VERSION "dbc-export 1 2025.20.8"

NS_ :

BS_:

BU_: ADSP APB APP APS APSB BB BMS CC CMP CMPD CP DAS DI DIF DIR DPB EPAS3P EPAS3S EPASTP EPASTS EPBL EPBR ESP EVSE FC GTW HCML HCMR HVP IBST ICR IDB LS OCS1P ODIN PARK PCS PLG PM PMF PMR PNCD PTC RADC RCM RCM2 RCM3 RCU SCCM SCM SCS SDCR TAS TCU TPMS TRCM UDS UI UIS UMC USM VC VCFRONT VCLEFT VCRIGHT VCSEC VEH

BO_ 1298 TRCM_alertLog: 8 TRCM
 SG_ TRCM_alertID M : 0|10@1+ (1,0) [0|1023] "" Vector__XXX
 SG_ TRCM_alertState : 15|1@1+ (1,0) [0|1] "" Vector__XXX
 SG_ TRCM_a015_NVMMMemOverflow m15 : 16|1@1+ (1,0) [0|1] "" Vector__XXX
 SG_ TRCM_a015_NVMMFilesystemError m15 : 17|1@1+ (1,0) [0|1] "" Vector__XXX
 SG_ TRCM_a015_NVMMRecordIDError m15 : 18|1@1+ (1,0) [0|1] "" Vector__XXX
 SG_ TRCM_a057_VEH_cpControl m57 : 16|1@1+ (1,0) [0|1] "" Vector__XXX
 SG_ TRCM_a059_voltageDrop m59 : 16|12@1+ (0.005443676,0) [0|22.29185322] "V" Vector__XXX
 SG_ TRCM_a059_resistanceEstimate m59 : 28|12@1+ (0.00244,0) [0|9.9918] "Ohms" Vector__XXX
 SG_ TRCM_a059_current m59 : 40|12@1+ (0.05,0) [0|204.75] "A" Vector__XXX
 SG_ TRCM_a063_switchChannel m63 : 16|8@1+ (1,0) [0|255] "" Vector__XXX
 SG_ TRCM_a063_switchType m63 : 24|8@1+ (1,0) [0|255] "" Vector__XXX
 SG_ TRCM_a063_ADCVoltage m63 : 32|8@1+ (0.025,0) [0|6.375] "V" Vector__XXX
 SG_ TRCM_a063_disconnected m63 : 40|1@1+ (1,0) [0|1] "" Vector__XXX
 SG_ TRCM_a063_indeterminate m63 : 41|1@1+ (1,0) [0|1] "" Vector__XXX
 SG_ TRCM_a063_stuckActive m63 : 42|1@1+ (1,0) [0|1] "" Vector__XXX
 SG_ TRCM_a063_faulted m63 : 43|1@1+ (1,0) [0|1] "" Vector__XXX
 SG_ TRCM_a082_RIPC_epbPrivateState m82 : 16|1@1+ (1,0) [0|1] "" Vector__XXX
 SG_ TRCM_a082_RIPC_remoteHSD m82 : 17|1@1+ (1,0) [0|1] "" Vector__XXX
 SG_ TRCM_a082_RIPC_railStatus m82 : 18|1@1+ (1,0) [0|1] "" Vector__XXX
 SG_ TRCM_a082_RIPC_remoteMux m82 : 19|1@1+ (1,0) [0|1] "" Vector__XXX
 SG_ TRCM_a083_LIPC_epbPrivateState m83 : 16|1@1+ (1,0) [0|1] "" Vector__XXX
 SG_ TRCM_a083_LIPC_remoteHSD m83 : 17|1@1+ (1,0) [0|1] "" Vector__XXX
 SG_ TRCM_a083_LIPC_railStatus m83 : 18|1@1+ (1,0) [0|1] "" Vector__XXX
 SG_ TRCM_a083_LIPC_HSDFaults m83 : 19|1@1+ (1,0) [0|1] "" Vector__XXX
 SG_ TRCM_a084_CH_StatusC m84 : 16|1@1+ (1,0) [0|1] "" Vector__XXX
 SG_ TRCM_a085_PARTY_buttonStatus m85 : 16|1@1+ (1,0) [0|1] "" Vector__XXX
 SG_ TRCM_a086_VEH_LVBMS_statusHigh m86 : 16|1@1+ (1,0) [0|1] "" Vector__XXX
 SG_ TRCM_a086_VEH_LVBMS_statusLow m86 : 17|1@1+ (1,0) [0|1] "" Vector__XXX
 SG_ TRCM_a086_VEH_status m86 : 18|1@1+ (1,0) [0|1] "" Vector__XXX
 SG_ TRCM_a086_VEH_12VBatteryStatus m86 : 19|1@1+ (1,0) [0|1] "" Vector__XXX
 SG_ TRCM_a086_VEH_LVPowerState m86 : 20|1@1+ (1,0) [0|1] "" Vector__XXX
 SG_ TRCM_a086_VEH_lightStatus m86 : 21|1@1+ (1,0) [0|1] "" Vector__XXX
 SG_ TRCM_a086_VEH_systemStatus m86 : 22|1@1+ (1,0) [0|1] "" Vector__XXX
 SG_ TRCM_a086_VEH_thermalStatus m86 : 23|1@1+ (1,0) [0|1] "" Vector__XXX
 SG_ TRCM_a086_VEH_vehNm m86 : 24|1@1+ (1,0) [0|1] "" Vector__XXX
 SG_ TRCM_a087_VEH_temperature m87 : 16|1@1+ (1,0) [0|1] "" Vector__XXX
 SG_ TRCM_a087_VEH_thermalControl m87 : 17|1@1+ (1,0) [0|1] "" Vector__XXX
 SG_ TRCM_a087_VEH_torque m87 : 18|1@1+ (1,0) [0|1] "" Vector__XXX
 SG_ TRCM_a087_VEH_status m87 : 19|1@1+ (1,0) [0|1] "" Vector__XXX
 SG_ TRCM_a087_PARTY_torque m87 : 20|1@1+ (1,0) [0|1] "" Vector__XXX
 SG_ TRCM_a087_PARTY_status m87 : 21|1@1+ (1,0) [0|1] "" Vector__XXX
 SG_ TRCM_a087_PARTY_temperature m87 : 22|1@1+ (1,0) [0|1] "" Vector__XXX
 SG_ TRCM_a087_PARTY_thermalControl m87 : 23|1@1+ (1,0) [0|1] "" Vector__XXX
 SG_ TRCM_a088_VEH_temperature m88 : 16|1@1+ (1,0) [0|1] "" Vector__XXX
 SG_ TRCM_a088_VEH_thermalControl m88 : 17|1@1+ (1,0) [0|1] "" Vector__XXX
 SG_ TRCM_a088_VEH_torque m88 : 18|1@1+ (1,0) [0|1] "" Vector__XXX
 SG_ TRCM_a088_VEH_status m88 : 19|1@1+ (1,0) [0|1] "" Vector__XXX
 SG_ TRCM_a088_PARTY_torque m88 : 20|1@1+ (1,0) [0|1] "" Vector__XXX
 SG_ TRCM_a088_PARTY_status m88 : 21|1@1+ (1,0) [0|1] "" Vector__XXX
 SG_ TRCM_a088_PARTY_temperature m88 : 22|1@1+ (1,0) [0|1] "" Vector__XXX
 SG_ TRCM_a088_PARTY_thermalControl m88 : 23|1@1+ (1,0) [0|1] "" Vector__XXX
 SG_ TRCM_a089_PARTY_party1 m89 : 16|1@1+ (1,0) [0|1] "" Vector__XXX
 SG_ TRCM_a089_PARTY_status m89 : 17|1@1+ (1,0) [0|1] "" Vector__XXX
 SG_ TRCM_a089_VEH_status m89 : 18|1@1+ (1,0) [0|1] "" Vector__XXX
 SG_ TRCM_a089_BDY_party1 m89 : 19|1@1+ (1,0) [0|1] "" Vector__XXX
 SG_ TRCM_a089_BDY_status m89 : 20|1@1+ (1,0) [0|1] "" Vector__XXX
 SG_ TRCM_a089_CH_status m89 : 21|1@1+ (1,0) [0|1] "" Vector__XXX
 SG_ TRCM_a089_CH_party1 m89 : 22|1@1+ (1,0) [0|1] "" Vector__XXX
 SG_ TRCM_a089_CH_party3 m89 : 23|1@1+ (1,0) [0|1] "" Vector__XXX
 SG_ TRCM_a089_VEH_party1 m89 : 24|1@1+ (1,0) [0|1] "" Vector__XXX
 SG_ TRCM_a089_VEH_party3 m89 : 25|1@1+ (1,0) [0|1] "" Vector__XXX
 SG_ TRCM_a091_VEH_faultsAndExtras m91 : 16|1@1+ (1,0) [0|1] "" Vector__XXX
 SG_ TRCM_a091_VEH_info m91 : 17|1@1+ (1,0) [0|1] "" Vector__XXX
 SG_ TRCM_a091_VEH_state m91 : 18|1@1+ (1,0) [0|1] "" Vector__XXX
 SG_ TRCM_a092_VEH_restraintStatus m92 : 16|1@1+ (1,0) [0|1] "" Vector__XXX
 SG_ TRCM_a092_VEH_switchStatus m92 : 17|1@1+ (1,0) [0|1] "" Vector__XXX
 SG_ TRCM_a092_VEH_seatStatus2 m92 : 18|1@1+ (1,0) [0|1] "" Vector__XXX
 SG_ TRCM_a092_VEH_vehNm m92 : 19|1@1+ (1,0) [0|1] "" Vector__XXX
 SG_ TRCM_a093_VEH_restraintStatus m93 : 16|1@1+ (1,0) [0|1] "" Vector__XXX
 SG_ TRCM_a093_VEH_switchStatus m93 : 17|1@1+ (1,0) [0|1] "" Vector__XXX
 SG_ TRCM_a093_VEH_seatStatus2 m93 : 18|1@1+ (1,0) [0|1] "" Vector__XXX
 SG_ TRCM_a093_VEH_vehNm m93 : 19|1@1+ (1,0) [0|1] "" Vector__XXX
 SG_ TRCM_a094_VEH_sysStatus m94 : 16|1@1+ (1,0) [0|1] "" Vector__XXX
 SG_ TRCM_a094_PARTY_sysStatus m94 : 17|1@1+ (1,0) [0|1] "" Vector__XXX
 SG_ TRCM_a095_PT_ptNm m95 : 16|1@1+ (1,0) [0|1] "" Vector__XXX
 SG_ TRCM_a095_PT_status m95 : 17|1@1+ (1,0) [0|1] "" Vector__XXX
 SG_ TRCM_a096_VEH_status m96 : 16|1@1+ (1,0) [0|1] "" Vector__XXX
 SG_ TRCM_a096_CH_status m96 : 17|1@1+ (1,0) [0|1] "" Vector__XXX
 SG_ TRCM_a098_CH_torque m98 : 16|1@1+ (1,0) [0|1] "" Vector__XXX
 SG_ TRCM_a098_VEH_hvStatus m98 : 17|1@1+ (1,0) [0|1] "" Vector__XXX
 SG_ TRCM_a098_VEH_status m98 : 18|1@1+ (1,0) [0|1] "" Vector__XXX
 SG_ TRCM_a098_VEH_thermalControl m98 : 19|1@1+ (1,0) [0|1] "" Vector__XXX
 SG_ TRCM_a098_VEH_temperature m98 : 20|1@1+ (1,0) [0|1] "" Vector__XXX
 SG_ TRCM_a098_VEH_torque m98 : 21|1@1+ (1,0) [0|1] "" Vector__XXX
 SG_ TRCM_a098_PARTY_status m98 : 22|1@1+ (1,0) [0|1] "" Vector__XXX
 SG_ TRCM_a098_PARTY_temperature m98 : 23|1@1+ (1,0) [0|1] "" Vector__XXX
 SG_ TRCM_a098_PARTY_thermalControl m98 : 24|1@1+ (1,0) [0|1] "" Vector__XXX
 SG_ TRCM_a098_PARTY_torque m98 : 25|1@1+ (1,0) [0|1] "" Vector__XXX
 SG_ TRCM_a098_PT_thermalControl m98 : 26|1@1+ (1,0) [0|1] "" Vector__XXX
 SG_ TRCM_a098_PT_temperature m98 : 27|1@1+ (1,0) [0|1] "" Vector__XXX
 SG_ TRCM_a099_VEH_oocStatus m99 : 16|1@1+ (1,0) [0|1] "" Vector__XXX
 SG_ TRCM_a100_VEH m100 : 16|1@1+ (1,0) [0|1] "" Vector__XXX
 SG_ TRCM_a100_PARTY m100 : 17|1@1+ (1,0) [0|1] "" Vector__XXX
 SG_ TRCM_a100_PT m100 : 18|1@1+ (1,0) [0|1] "" Vector__XXX
 SG_ TRCM_a100_CH m100 : 19|1@1+ (1,0) [0|1] "" Vector__XXX
 SG_ TRCM_a100_OBD m100 : 20|1@1+ (1,0) [0|1] "" Vector__XXX
 SG_ TRCM_a101_VEH_state m101 : 16|1@1+ (1,0) [0|1] "" Vector__XXX
 SG_ TRCM_a101_PARTY_locState m101 : 17|1@1+ (1,0) [0|1] "" Vector__XXX
 SG_ TRCM_a101_LIPC_externalWatchdogH m101 : 18|1@1+ (1,0) [0|1] "" Vector__XXX
 SG_ TRCM_a101_VEH_locState m101 : 19|1@1+ (1,0) [0|1] "" Vector__XXX
 SG_ TRCM_a101_BDY_locState m101 : 20|1@1+ (1,0) [0|1] "" Vector__XXX
 SG_ TRCM_a102_VEH_faultsAndExtras m102 : 16|1@1+ (1,0) [0|1] "" Vector__XXX
 SG_ TRCM_a102_VEH_feedbackStatus m102 : 17|1@1+ (1,0) [0|1] "" Vector__XXX
 SG_ TRCM_a102_VEH_sensorStatus m102 : 18|1@1+ (1,0) [0|1] "" Vector__XXX
 SG_ TRCM_a102_VEH_rods m102 : 19|1@1+ (1,0) [0|1] "" Vector__XXX
 SG_ TRCM_a103_VEH_hvsNm m103 : 16|1@1+ (1,0) [0|1] "" Vector__XXX
 SG_ TRCM_a103_VEH_vehNm m103 : 17|1@1+ (1,0) [0|1] "" Vector__XXX
 SG_ TRCM_a103_VEH_status m103 : 18|1@1+ (1,0) [0|1] "" Vector__XXX
 SG_ TRCM_a103_PT_ptNm m103 : 19|1@1+ (1,0) [0|1] "" Vector__XXX
 SG_ TRCM_a103_PT_status m103 : 20|1@1+ (1,0) [0|1] "" Vector__XXX
 SG_ TRCM_a103_VEH_evseStatus m103 : 21|1@1+ (1,0) [0|1] "" Vector__XXX
 SG_ TRCM_a105_VEH_states m105 : 16|1@1+ (1,0) [0|1] "" Vector__XXX
 SG_ TRCM_a105_VEH_chNm m105 : 17|1@1+ (1,0) [0|1] "" Vector__XXX
 SG_ TRCM_a105_VEH_dampingStates m105 : 18|1@1+ (1,0) [0|1] "" Vector__XXX
 SG_ TRCM_a106_VEH_dcdcStatus m106 : 16|1@1+ (1,0) [0|1] "" Vector__XXX
 SG_ TRCM_a106_VEH_thermalControl m106 : 17|1@1+ (1,0) [0|1] "" Vector__XXX
 SG_ TRCM_a106_VEH_thermalInterface m106 : 18|1@1+ (1,0) [0|1] "" Vector__XXX
 SG_ TRCM_a106_VEH_dcdcRailStatus m106 : 19|1@1+ (1,0) [0|1] "" Vector__XXX
 SG_ TRCM_a106_CH_dcdcRailStatus m106 : 20|1@1+ (1,0) [0|1] "" Vector__XXX
 SG_ TRCM_a106_CH_alertMatrix m106 : 21|1@1+ (1,0) [0|1] "" Vector__XXX
 SG_ TRCM_a107_VEH_hvsNm m107 : 16|1@1+ (1,0) [0|1] "" Vector__XXX
 SG_ TRCM_a107_VEH_vehNm m107 : 17|1@1+ (1,0) [0|1] "" Vector__XXX
 SG_ TRCM_a107_VEH_status m107 : 18|1@1+ (1,0) [0|1] "" Vector__XXX
 SG_ TRCM_a107_VEH_thermalStatus m107 : 19|1@1+ (1,0) [0|1] "" Vector__XXX
 SG_ TRCM_a107_VEH_thermalStatus2 m107 : 20|1@1+ (1,0) [0|1] "" Vector__XXX
 SG_ TRCM_a107_VEH_bmbMinMax m107 : 21|1@1+ (1,0) [0|1] "" Vector__XXX
 SG_ TRCM_a107_VEH_powerAvailable m107 : 22|1@1+ (1,0) [0|1] "" Vector__XXX
 SG_ TRCM_a107_PT_ptNm m107 : 23|1@1+ (1,0) [0|1] "" Vector__XXX
 SG_ TRCM_a107_PT_status m107 : 24|1@1+ (1,0) [0|1] "" Vector__XXX
 SG_ TRCM_a107_PT_thermalStatus m107 : 25|1@1+ (1,0) [0|1] "" Vector__XXX
 SG_ TRCM_a107_PT_socStatus m107 : 26|1@1+ (1,0) [0|1] "" Vector__XXX
 SG_ TRCM_a107_VEH_socStatus m107 : 27|1@1+ (1,0) [0|1] "" Vector__XXX
 SG_ TRCM_a107_VEH_packConfig m107 : 28|1@1+ (1,0) [0|1] "" Vector__XXX
 SG_ TRCM_a107_VEH_energyStatus m107 : 29|1@1+ (1,0) [0|1] "" Vector__XXX
 SG_ TRCM_a107_VEH_chargeInfo m107 : 30|1@1+ (1,0) [0|1] "" Vector__XXX
 SG_ TRCM_a108_VEH_hvStatus m108 : 16|1@1+ (1,0) [0|1] "" Vector__XXX
 SG_ TRCM_a108_VEH_temperature m108 : 17|1@1+ (1,0) [0|1] "" Vector__XXX
 SG_ TRCM_a108_VEH_thermalControl m108 : 18|1@1+ (1,0) [0|1] "" Vector__XXX
 SG_ TRCM_a108_VEH_torque m108 : 19|1@1+ (1,0) [0|1] "" Vector__XXX
 SG_ TRCM_a108_VEH_status m108 : 20|1@1+ (1,0) [0|1] "" Vector__XXX
 SG_ TRCM_a108_PARTY_torque m108 : 21|1@1+ (1,0) [0|1] "" Vector__XXX
 SG_ TRCM_a108_PARTY_status m108 : 22|1@1+ (1,0) [0|1] "" Vector__XXX
 SG_ TRCM_a108_PARTY_temperature m108 : 23|1@1+ (1,0) [0|1] "" Vector__XXX
 SG_ TRCM_a108_PARTY_thermalControl m108 : 24|1@1+ (1,0) [0|1] "" Vector__XXX
 SG_ TRCM_a108_PT_temperature m108 : 25|1@1+ (1,0) [0|1] "" Vector__XXX
 SG_ TRCM_a108_PT_thermalControl m108 : 26|1@1+ (1,0) [0|1] "" Vector__XXX
 SG_ TRCM_a109_PARTY_status m109 : 16|1@1+ (1,0) [0|1] "" Vector__XXX
 SG_ TRCM_a109_PARTY_inertial2 m109 : 17|1@1+ (1,0) [0|1] "" Vector__XXX
 SG_ TRCM_a109_PARTY_nearDeploy m109 : 18|1@1+ (1,0) [0|1] "" Vector__XXX
 SG_ TRCM_a109_PARTY_collision m109 : 19|1@1+ (1,0) [0|1] "" Vector__XXX
 SG_ TRCM_a109_VEH_status m109 : 20|1@1+ (1,0) [0|1] "" Vector__XXX
 SG_ TRCM_a109_VEH_imuOffsets m109 : 21|1@1+ (1,0) [0|1] "" Vector__XXX
 SG_ TRCM_a109_PARTY_inertial1 m109 : 22|1@1+ (1,0) [0|1] "" Vector__XXX
 SG_ TRCM_a109_BDY_imuOffsets m109 : 23|1@1+ (1,0) [0|1] "" Vector__XXX
 SG_ TRCM_a109_BDY_inertial1 m109 : 24|1@1+ (1,0) [0|1] "" Vector__XXX
 SG_ TRCM_a109_BDY_inertial2 m109 : 25|1@1+ (1,0) [0|1] "" Vector__XXX
 SG_ TRCM_a109_BDY_status m109 : 26|1@1+ (1,0) [0|1] "" Vector__XXX
 SG_ TRCM_a109_VEH_inertial1 m109 : 27|1@1+ (1,0) [0|1] "" Vector__XXX
 SG_ TRCM_a109_VEH_inertial2 m109 : 28|1@1+ (1,0) [0|1] "" Vector__XXX
 SG_ TRCM_a109_CH_inertial1 m109 : 29|1@1+ (1,0) [0|1] "" Vector__XXX
 SG_ TRCM_a109_CH_inertial2 m109 : 30|1@1+ (1,0) [0|1] "" Vector__XXX
 SG_ TRCM_a109_CH_status m109 : 31|1@1+ (1,0) [0|1] "" Vector__XXX
 SG_ TRCM_a110_VEH_carState m110 : 16|1@1+ (1,0) [0|1] "" Vector__XXX
 SG_ TRCM_a110_VEH_carConfig m110 : 17|1@1+ (1,0) [0|1] "" Vector__XXX
 SG_ TRCM_a110_VEH_time m110 : 18|1@1+ (1,0) [0|1] "" Vector__XXX
 SG_ TRCM_a110_VEH_updateStatus m110 : 19|1@1+ (1,0) [0|1] "" Vector__XXX
 SG_ TRCM_a110_VEH_vehNm m110 : 20|1@1+ (1,0) [0|1] "" Vector__XXX
 SG_ TRCM_a110_VEH_mismatchFault m110 : 21|1@1+ (1,0) [0|1] "" Vector__XXX
 SG_ TRCM_a110_VEH_vin m110 : 22|1@1+ (1,0) [0|1] "" Vector__XXX
 SG_ TRCM_a110_VEH_bmpDebug m110 : 23|1@1+ (1,0) [0|1] "" Vector__XXX
 SG_ TRCM_a110_VEH_gearControl m110 : 24|1@1+ (1,0) [0|1] "" Vector__XXX
 SG_ TRCM_a110_VEH_canLogAvailability m110 : 25|1@1+ (1,0) [0|1] "" Vector__XXX
 SG_ TRCM_a110_CH_airbagCutoffStatus m110 : 26|1@1+ (1,0) [0|1] "" Vector__XXX
 SG_ TRCM_a110_CH_carConfig m110 : 27|1@1+ (1,0) [0|1] "" Vector__XXX
 SG_ TRCM_a110_CH_carState m110 : 28|1@1+ (1,0) [0|1] "" Vector__XXX
 SG_ TRCM_a110_CH_vin m110 : 29|1@1+ (1,0) [0|1] "" Vector__XXX
 SG_ TRCM_a110_CH_chNm m110 : 30|1@1+ (1,0) [0|1] "" Vector__XXX
 SG_ TRCM_a110_CH_epochTimeGtw m110 : 31|1@1+ (1,0) [0|1] "" Vector__XXX
 SG_ TRCM_a111_VEH_internalStatus m111 : 16|1@1+ (1,0) [0|1] "" Vector__XXX
 SG_ TRCM_a111_VEH_status m111 : 17|1@1+ (1,0) [0|1] "" Vector__XXX
 SG_ TRCM_a111_VEH_vehNm m111 : 18|1@1+ (1,0) [0|1] "" Vector__XXX
 SG_ TRCM_a111_RIPC_LVPowerState m111 : 19|1@1+ (1,0) [0|1] "" Vector__XXX
 SG_ TRCM_a111_RIPC_epbPrivateState m111 : 20|1@1+ (1,0) [0|1] "" Vector__XXX
 SG_ TRCM_a111_RIPC_railStatus m111 : 21|1@1+ (1,0) [0|1] "" Vector__XXX
 SG_ TRCM_a111_RIPC_remoteADC m111 : 22|1@1+ (1,0) [0|1] "" Vector__XXX
 SG_ TRCM_a111_RIPC_switchStatus m111 : 23|1@1+ (1,0) [0|1] "" Vector__XXX
 SG_ TRCM_a111_VEH_LVPowerState m111 : 24|1@1+ (1,0) [0|1] "" Vector__XXX
 SG_ TRCM_a111_VEH_seatStatus m111 : 25|1@1+ (1,0) [0|1] "" Vector__XXX
 SG_ TRCM_a111_PARTY_status m111 : 26|1@1+ (1,0) [0|1] "" Vector__XXX
 SG_ TRCM_a111_CH_status m111 : 27|1@1+ (1,0) [0|1] "" Vector__XXX
 SG_ TRCM_a112_VEH_internalStatus m112 : 16|1@1+ (1,0) [0|1] "" Vector__XXX
 SG_ TRCM_a112_VEH_status m112 : 17|1@1+ (1,0) [0|1] "" Vector__XXX
 SG_ TRCM_a112_VEH_vehNm m112 : 18|1@1+ (1,0) [0|1] "" Vector__XXX
 SG_ TRCM_a112_LIPC_LVPowerState m112 : 19|1@1+ (1,0) [0|1] "" Vector__XXX
 SG_ TRCM_a112_LIPC_epbPrivateState m112 : 20|1@1+ (1,0) [0|1] "" Vector__XXX
 SG_ TRCM_a112_LIPC_railStatus m112 : 21|1@1+ (1,0) [0|1] "" Vector__XXX
 SG_ TRCM_a112_LIPC_remoteADC m112 : 22|1@1+ (1,0) [0|1] "" Vector__XXX
 SG_ TRCM_a112_LIPC_switchStatus m112 : 23|1@1+ (1,0) [0|1] "" Vector__XXX
 SG_ TRCM_a112_VEH_LVPowerState m112 : 24|1@1+ (1,0) [0|1] "" Vector__XXX
 SG_ TRCM_a112_PARTY_status m112 : 25|1@1+ (1,0) [0|1] "" Vector__XXX
 SG_ TRCM_a112_CH_status m112 : 26|1@1+ (1,0) [0|1] "" Vector__XXX
 SG_ TRCM_a114_PARTY_status m114 : 16|1@1+ (1,0) [0|1] "" Vector__XXX
 SG_ TRCM_a114_PARTY_wheelSpeeds m114 : 17|1@1+ (1,0) [0|1] "" Vector__XXX
 SG_ TRCM_a114_VEH_wheelSpeeds m114 : 18|1@1+ (1,0) [0|1] "" Vector__XXX
 SG_ TRCM_a114_CH_wheelSpeeds m114 : 19|1@1+ (1,0) [0|1] "" Vector__XXX
 SG_ TRCM_a114_PARTY_party3 m114 : 20|1@1+ (1,0) [0|1] "" Vector__XXX
 SG_ TRCM_a114_VEH_party3 m114 : 21|1@1+ (1,0) [0|1] "" Vector__XXX
 SG_ TRCM_a114_VEH_status m114 : 22|1@1+ (1,0) [0|1] "" Vector__XXX
 SG_ TRCM_a114_PARTY_wheelRotation m114 : 23|1@1+ (1,0) [0|1] "" Vector__XXX
 SG_ TRCM_a114_CH_wheelRotation m114 : 24|1@1+ (1,0) [0|1] "" Vector__XXX
 SG_ TRCM_a114_VEH_wheelRotation m114 : 25|1@1+ (1,0) [0|1] "" Vector__XXX
 SG_ TRCM_a114_PARTY_brakeTorque m114 : 26|1@1+ (1,0) [0|1] "" Vector__XXX
 SG_ TRCM_a114_PARTY_offsets m114 : 27|1@1+ (1,0) [0|1] "" Vector__XXX
 SG_ TRCM_a114_BDY_offsets m114 : 28|1@1+ (1,0) [0|1] "" Vector__XXX
 SG_ TRCM_a114_BDY_party3 m114 : 29|1@1+ (1,0) [0|1] "" Vector__XXX
 SG_ TRCM_a114_BDY_status m114 : 30|1@1+ (1,0) [0|1] "" Vector__XXX
 SG_ TRCM_a114_BDY_wheelRotation m114 : 31|1@1+ (1,0) [0|1] "" Vector__XXX
 SG_ TRCM_a114_BDY_wheelSpeeds m114 : 32|1@1+ (1,0) [0|1] "" Vector__XXX
 SG_ TRCM_a114_CH_party1 m114 : 33|1@1+ (1,0) [0|1] "" Vector__XXX
 SG_ TRCM_a114_CH_party3 m114 : 34|1@1+ (1,0) [0|1] "" Vector__XXX
 SG_ TRCM_a114_CH_status m114 : 35|1@1+ (1,0) [0|1] "" Vector__XXX
 SG_ TRCM_a115_VEH_vehNm m115 : 16|1@1+ (1,0) [0|1] "" Vector__XXX
 SG_ TRCM_a115_VEH_authentication m115 : 17|1@1+ (1,0) [0|1] "" Vector__XXX
 SG_ TRCM_a115_VEH_BLEResetRequest m115 : 18|1@1+ (1,0) [0|1] "" Vector__XXX
 SG_ TRCM_a115_VEH_requests m115 : 19|1@1+ (1,0) [0|1] "" Vector__XXX
 SG_ TRCM_a115_VEH_requests2 m115 : 20|1@1+ (1,0) [0|1] "" Vector__XXX
 SG_ TRCM_a115_REM_authentication m115 : 21|1@1+ (1,0) [0|1] "" Vector__XXX
 SG_ TRCM_a115_UI_corianderVehicleCon m115 : 22|1@1+ (1,0) [0|1] "" Vector__XXX
 SG_ TRCM_a115_CH_TPMSDisplay m115 : 23|1@1+ (1,0) [0|1] "" Vector__XXX
 SG_ TRCM_a116_PARTY_epbmStatus m116 : 16|1@1+ (1,0) [0|1] "" Vector__XXX
 SG_ TRCM_a116_VEH_vehNm m116 : 17|1@1+ (1,0) [0|1] "" Vector__XXX
 SG_ TRCM_a116_VEH_hvacRequest m116 : 18|1@1+ (1,0) [0|1] "" Vector__XXX
 SG_ TRCM_a116_VEH_hvacStatus m116 : 19|1@1+ (1,0) [0|1] "" Vector__XXX
 SG_ TRCM_a116_VEH_LVPowerState m116 : 20|1@1+ (1,0) [0|1] "" Vector__XXX
 SG_ TRCM_a116_VEH_lightStatus m116 : 21|1@1+ (1,0) [0|1] "" Vector__XXX
 SG_ TRCM_a116_VEH_seatStatus m116 : 22|1@1+ (1,0) [0|1] "" Vector__XXX
 SG_ TRCM_a116_VEH_thsStatus m116 : 23|1@1+ (1,0) [0|1] "" Vector__XXX
 SG_ TRCM_a116_VEH_doorStatus m116 : 24|1@1+ (1,0) [0|1] "" Vector__XXX
 SG_ TRCM_a116_VEH_seatHeatStatus m116 : 25|1@1+ (1,0) [0|1] "" Vector__XXX
 SG_ TRCM_a116_VEH_restraintStatus m116 : 26|1@1+ (1,0) [0|1] "" Vector__XXX
 SG_ TRCM_a116_VEH_switchStatus m116 : 27|1@1+ (1,0) [0|1] "" Vector__XXX
 SG_ TRCM_a116_VEH_logging1Hz m116 : 28|1@1+ (1,0) [0|1] "" Vector__XXX
 SG_ TRCM_a116_VEH_seatStatus2 m116 : 29|1@1+ (1,0) [0|1] "" Vector__XXX
 SG_ TRCM_a116_VEH_status m116 : 30|1@1+ (1,0) [0|1] "" Vector__XXX
 SG_ TRCM_a116_VEH_thermalCommand m116 : 31|1@1+ (1,0) [0|1] "" Vector__XXX
 SG_ TRCM_a116_VEH_windowStatus m116 : 32|1@1+ (1,0) [0|1] "" Vector__XXX
 SG_ TRCM_a116_PARTY_restraintStatus m116 : 33|1@1+ (1,0) [0|1] "" Vector__XXX
 SG_ TRCM_a116_PARTY_doorStatus m116 : 34|1@1+ (1,0) [0|1] "" Vector__XXX
 SG_ TRCM_a116_BDY_epbmStatus m116 : 35|1@1+ (1,0) [0|1] "" Vector__XXX
 SG_ TRCM_a116_BDY_restraintStatus m116 : 36|1@1+ (1,0) [0|1] "" Vector__XXX
 SG_ TRCM_a117_BDY_epbmStatus m117 : 16|1@1+ (1,0) [0|1] "" Vector__XXX
 SG_ TRCM_a117_BDY_restraintStatus m117 : 17|1@1+ (1,0) [0|1] "" Vector__XXX
 SG_ TRCM_a117_VEH_prndStatus m117 : 18|1@1+ (1,0) [0|1] "" Vector__XXX
 SG_ TRCM_a117_PARTY_epbmStatus m117 : 19|1@1+ (1,0) [0|1] "" Vector__XXX
 SG_ TRCM_a117_VEH_vehNm m117 : 20|1@1+ (1,0) [0|1] "" Vector__XXX
 SG_ TRCM_a117_VEH_hvacBlowerFdb m117 : 21|1@1+ (1,0) [0|1] "" Vector__XXX
 SG_ TRCM_a117_VEH_LVPowerState m117 : 22|1@1+ (1,0) [0|1] "" Vector__XXX
 SG_ TRCM_a117_VEH_restraintStatus m117 : 23|1@1+ (1,0) [0|1] "" Vector__XXX
 SG_ TRCM_a117_VEH_lightStatus m117 : 24|1@1+ (1,0) [0|1] "" Vector__XXX
 SG_ TRCM_a117_VEH_seatStatus m117 : 25|1@1+ (1,0) [0|1] "" Vector__XXX
 SG_ TRCM_a117_BDY_falconSwitchStatus m117 : 26|1@1+ (1,0) [0|1] "" Vector__XXX
 SG_ TRCM_a117_VEH_doorStatus m117 : 27|1@1+ (1,0) [0|1] "" Vector__XXX
 SG_ TRCM_a117_VEH_doorStatus2 m117 : 28|1@1+ (1,0) [0|1] "" Vector__XXX
 SG_ TRCM_a117_VEH_windowStatus m117 : 29|1@1+ (1,0) [0|1] "" Vector__XXX
 SG_ TRCM_a117_VEH_switchStatus m117 : 30|1@1+ (1,0) [0|1] "" Vector__XXX
 SG_ TRCM_a117_VEH_intrusionSensorSta m117 : 31|1@1+ (1,0) [0|1] "" Vector__XXX
 SG_ TRCM_a117_VEH_liftgateStatus m117 : 32|1@1+ (1,0) [0|1] "" Vector__XXX
 SG_ TRCM_a117_VEH_seatStatus2 m117 : 33|1@1+ (1,0) [0|1] "" Vector__XXX
 SG_ TRCM_a117_PARTY_restraintStatus m117 : 34|1@1+ (1,0) [0|1] "" Vector__XXX
 SG_ TRCM_a117_VEH_thermalStatus m117 : 35|1@1+ (1,0) [0|1] "" Vector__XXX
 SG_ TRCM_a117_PARTY_doorStatus m117 : 36|1@1+ (1,0) [0|1] "" Vector__XXX
 SG_ TRCM_a117_VEH_status m117 : 37|1@1+ (1,0) [0|1] "" Vector__XXX
 SG_ TRCM_a117_PARTY_prndStatus m117 : 38|1@1+ (1,0) [0|1] "" Vector__XXX
 SG_ TRCM_a118_VEH_vehNm m118 : 16|1@1+ (1,0) [0|1] "" Vector__XXX
 SG_ TRCM_a118_VEH_lighting m118 : 17|1@1+ (1,0) [0|1] "" Vector__XXX
 SG_ TRCM_a118_VEH_sensors m118 : 18|1@1+ (1,0) [0|1] "" Vector__XXX
 SG_ TRCM_a118_VEH_status m118 : 19|1@1+ (1,0) [0|1] "" Vector__XXX
 SG_ TRCM_a118_VEH_okToUseHighPwr m118 : 20|1@1+ (1,0) [0|1] "" Vector__XXX
 SG_ TRCM_a118_VEH_LVPowerState m118 : 21|1@1+ (1,0) [0|1] "" Vector__XXX
 SG_ TRCM_a118_VEH_coolant m118 : 22|1@1+ (1,0) [0|1] "" Vector__XXX
 SG_ TRCM_a118_VEH_vehicleStatus m118 : 23|1@1+ (1,0) [0|1] "" Vector__XXX
 SG_ TRCM_a118_VEH_12VBatteryStatus m118 : 24|1@1+ (1,0) [0|1] "" Vector__XXX
 SG_ TRCM_a118_VEH_systemStatus m118 : 25|1@1+ (1,0) [0|1] "" Vector__XXX
 SG_ TRCM_a118_PARTY_LVPowerState m118 : 26|1@1+ (1,0) [0|1] "" Vector__XXX
 SG_ TRCM_a118_PARTY_outputPowerStatu m118 : 27|1@1+ (1,0) [0|1] "" Vector__XXX
 SG_ TRCM_a118_PARTY_vehicleTime m118 : 28|1@1+ (1,0) [0|1] "" Vector__XXX
 SG_ TRCM_a118_VEH_thermalCommand m118 : 29|1@1+ (1,0) [0|1] "" Vector__XXX
 SG_ TRCM_a118_CH_LVPowerState m118 : 30|1@1+ (1,0) [0|1] "" Vector__XXX
 SG_ TRCM_a118_PARTY_sensors m118 : 31|1@1+ (1,0) [0|1] "" Vector__XXX
 SG_ TRCM_a118_CH_sensors m118 : 32|1@1+ (1,0) [0|1] "" Vector__XXX
 SG_ TRCM_a118_VEH_interNodeResistanc m118 : 33|1@1+ (1,0) [0|1] "" Vector__XXX
 SG_ TRCM_a118_CH_lighting m118 : 34|1@1+ (1,0) [0|1] "" Vector__XXX
 SG_ TRCM_a118_VEH_lightStatus m118 : 35|1@1+ (1,0) [0|1] "" Vector__XXX
 SG_ TRCM_a118_PARTY_vehNm m118 : 36|1@1+ (1,0) [0|1] "" Vector__XXX
 SG_ TRCM_a118_CH_12VBatteryStatus m118 : 37|1@1+ (1,0) [0|1] "" Vector__XXX
 SG_ TRCM_a118_CH_LVBMS_statusHigh m118 : 38|1@1+ (1,0) [0|1] "" Vector__XXX
 SG_ TRCM_a118_CH_alertMatrix m118 : 39|1@1+ (1,0) [0|1] "" Vector__XXX
 SG_ TRCM_a118_BDY_outputPowerStatus m118 : 40|1@1+ (1,0) [0|1] "" Vector__XXX
 SG_ TRCM_a118_BDY_vehicleTime m118 : 41|1@1+ (1,0) [0|1] "" Vector__XXX
 SG_ TRCM_a118_PARTY_AP_vehicleState1 m118 : 42|1@1+ (1,0) [0|1] "" Vector__XXX
 SG_ TRCM_a118_BDY_AP_vehicleState1Hz m118 : 43|1@1+ (1,0) [0|1] "" Vector__XXX
 SG_ TRCM_a119_VEH_steerAngle m119 : 16|1@1+ (1,0) [0|1] "" Vector__XXX
 SG_ TRCM_a119_VEH_leftStalk m119 : 17|1@1+ (1,0) [0|1] "" Vector__XXX
 SG_ TRCM_a119_VEH_rightStalk m119 : 18|1@1+ (1,0) [0|1] "" Vector__XXX
 SG_ TRCM_a119_PARTY_rightStalk m119 : 19|1@1+ (1,0) [0|1] "" Vector__XXX
 SG_ TRCM_a119_CH_steerAngle m119 : 20|1@1+ (1,0) [0|1] "" Vector__XXX
 SG_ TRCM_a119_PARTY_steerAngle m119 : 21|1@1+ (1,0) [0|1] "" Vector__XXX
 SG_ TRCM_a120_PARTY_chassisCntl m120 : 16|1@1+ (1,0) [0|1] "" Vector__XXX
 SG_ TRCM_a120_VEH_systemStatus m120 : 17|1@1+ (1,0) [0|1] "" Vector__XXX
 SG_ TRCM_a120_CH_chassisCntl m120 : 18|1@1+ (1,0) [0|1] "" Vector__XXX
 SG_ TRCM_a120_PARTY_systemStatus m120 : 19|1@1+ (1,0) [0|1] "" Vector__XXX
 SG_ TRCM_a120_PARTY_torque m120 : 20|1@1+ (1,0) [0|1] "" Vector__XXX
 SG_ TRCM_a120_VEH_torque m120 : 21|1@1+ (1,0) [0|1] "" Vector__XXX
 SG_ TRCM_a120_PARTY_locStatus m120 : 22|1@1+ (1,0) [0|1] "" Vector__XXX
 SG_ TRCM_a120_PARTY_speed m120 : 23|1@1+ (1,0) [0|1] "" Vector__XXX
 SG_ TRCM_a120_VEH_speed m120 : 24|1@1+ (1,0) [0|1] "" Vector__XXX
 SG_ TRCM_a120_PARTY_status m120 : 25|1@1+ (1,0) [0|1] "" Vector__XXX
 SG_ TRCM_a120_PT_speed m120 : 26|1@1+ (1,0) [0|1] "" Vector__XXX
 SG_ TRCM_a120_PT_systemStatus m120 : 27|1@1+ (1,0) [0|1] "" Vector__XXX
 SG_ TRCM_a120_PARTY_vehicleEstimates m120 : 28|1@1+ (1,0) [0|1] "" Vector__XXX
 SG_ TRCM_a120_VEH_aggregatedAxleSpee m120 : 29|1@1+ (1,0) [0|1] "" Vector__XXX
 SG_ TRCM_a120_PARTY_aggregatedAxleSp m120 : 30|1@1+ (1,0) [0|1] "" Vector__XXX
 SG_ TRCM_a120_VEH_systemPower m120 : 31|1@1+ (1,0) [0|1] "" Vector__XXX
 SG_ TRCM_a120_PT_systemPower m120 : 32|1@1+ (1,0) [0|1] "" Vector__XXX
 SG_ TRCM_a120_PARTY_stalklessInterfa m120 : 33|1@1+ (1,0) [0|1] "" Vector__XXX
 SG_ TRCM_a120_CH_speed m120 : 34|1@1+ (1,0) [0|1] "" Vector__XXX
 SG_ TRCM_a120_VEH_estimatedBrakeTemp m120 : 35|1@1+ (1,0) [0|1] "" Vector__XXX
 SG_ TRCM_a120_PARTY_prndControl m120 : 36|1@1+ (1,0) [0|1] "" Vector__XXX
 SG_ TRCM_a120_PARTY_locStatus2 m120 : 37|1@1+ (1,0) [0|1] "" Vector__XXX
 SG_ TRCM_a120_VEH_chassisCntl m120 : 38|1@1+ (1,0) [0|1] "" Vector__XXX
 SG_ TRCM_a120_VEH_locStatus m120 : 39|1@1+ (1,0) [0|1] "" Vector__XXX
 SG_ TRCM_a120_VEH_locStatus2 m120 : 40|1@1+ (1,0) [0|1] "" Vector__XXX
 SG_ TRCM_a120_VEH_prndControl m120 : 41|1@1+ (1,0) [0|1] "" Vector__XXX
 SG_ TRCM_a120_VEH_vehicleEstimates m120 : 42|1@1+ (1,0) [0|1] "" Vector__XXX

BO_ 2030 TRCM_alertMatrix: 8 TRCM
 SG_ TRCM_matrixIndex M : 0|4@1+ (1,0) [0|15] "" Vector__XXX
 SG_ TRCM_a003_SWAssertion m0 : 6|1@1+ (1,0) [0|1] "" Vector__XXX
 SG_ TRCM_a005_CANTXError m0 : 8|1@1+ (1,0) [0|1] "" Vector__XXX
 SG_ TRCM_a006_CANTX_cyclicError m0 : 9|1@1+ (1,0) [0|1] "" Vector__XXX
 SG_ TRCM_a007_chassisChecksumError m0 : 10|1@1+ (1,0) [0|1] "" Vector__XXX
 SG_ TRCM_a008_chassisCounterError m0 : 11|1@1+ (1,0) [0|1] "" Vector__XXX
 SG_ TRCM_a009_partyChecksumError m0 : 12|1@1+ (1,0) [0|1] "" Vector__XXX
 SG_ TRCM_a010_partyCounterError m0 : 13|1@1+ (1,0) [0|1] "" Vector__XXX
 SG_ TRCM_a012_asm5TemperatureOutside m0 : 15|1@1+ (1,0) [0|1] "" Vector__XXX
 SG_ TRCM_a013_AlertManagerFault m0 : 16|1@1+ (1,0) [0|1] "" Vector__XXX
 SG_ TRCM_a014_asm3TemperatureOutside m0 : 17|1@1+ (1,0) [0|1] "" Vector__XXX
 SG_ TRCM_a015_NVMMError m0 : 18|1@1+ (1,0) [0|1] "" Vector__XXX
 SG_ TRCM_a016_NVMMRecordError m0 : 19|1@1+ (1,0) [0|1] "" Vector__XXX
 SG_ TRCM_a017_asm5TemperatureOutside m0 : 20|1@1+ (1,0) [0|1] "" Vector__XXX
 SG_ TRCM_a018_asm3TemperatureOutside m0 : 21|1@1+ (1,0) [0|1] "" Vector__XXX
 SG_ TRCM_a019_Task500usError m0 : 22|1@1+ (1,0) [0|1] "" Vector__XXX
 SG_ TRCM_a020_asm3ComStatusError m0 : 23|1@1+ (1,0) [0|1] "" Vector__XXX
 SG_ TRCM_a021_TaskSchedulerError m0 : 24|1@1+ (1,0) [0|1] "" Vector__XXX
 SG_ TRCM_a022_TaskInitError m0 : 25|1@1+ (1,0) [0|1] "" Vector__XXX
 SG_ TRCM_a023_asm3ArsStatusXError m0 : 26|1@1+ (1,0) [0|1] "" Vector__XXX
 SG_ TRCM_a024_asm3AccStatusError m0 : 27|1@1+ (1,0) [0|1] "" Vector__XXX
 SG_ TRCM_a025_CHCANBusFaults m0 : 28|1@1+ (1,0) [0|1] "" Vector__XXX
 SG_ TRCM_a026_airbagAsicDiagnosticFa m0 : 29|1@1+ (1,0) [0|1] "" Vector__XXX
 SG_ TRCM_a027_airbagAsicDeploymentDi m0 : 30|1@1+ (1,0) [0|1] "" Vector__XXX
 SG_ TRCM_a030_ECULogUploadRequest m0 : 33|1@1+ (1,0) [0|1] "" Vector__XXX
 SG_ TRCM_a031_UDSActive m0 : 34|1@1+ (1,0) [0|1] "" Vector__XXX
 SG_ TRCM_a033_HercLogCreated m0 : 36|1@1+ (1,0) [0|1] "" Vector__XXX
 SG_ TRCM_a034_apClipTrigger m0 : 37|1@1+ (1,0) [0|1] "" Vector__XXX
 SG_ TRCM_a035_hvDisconnectCommanded m0 : 38|1@1+ (1,0) [0|1] "" Vector__XXX
 SG_ TRCM_a041_HighCPULoad m0 : 44|1@1+ (1,0) [0|1] "" Vector__XXX
 SG_ TRCM_a042_HighStackUsage m0 : 45|1@1+ (1,0) [0|1] "" Vector__XXX
 SG_ TRCM_a043_Task1msError m0 : 46|1@1+ (1,0) [0|1] "" Vector__XXX
 SG_ TRCM_a044_Task10msError m0 : 47|1@1+ (1,0) [0|1] "" Vector__XXX
 SG_ TRCM_a045_Task100msError m0 : 48|1@1+ (1,0) [0|1] "" Vector__XXX
 SG_ TRCM_a046_Task1000msError m0 : 49|1@1+ (1,0) [0|1] "" Vector__XXX
 SG_ TRCM_a057_HVP_MIA m0 : 60|1@1+ (1,0) [0|1] "" Vector__XXX
 SG_ TRCM_a058_inputRHighSyncDebug m0 : 61|1@1+ (1,0) [0|1] "" Vector__XXX
 SG_ TRCM_a059_inputResistanceHigh m0 : 62|1@1+ (1,0) [0|1] "" Vector__XXX
 SG_ TRCM_a060_engineeringBuild m0 : 63|1@1+ (1,0) [0|1] "" Vector__XXX
 SG_ TRCM_a061_XCPConnected m1 : 4|1@1+ (1,0) [0|1] "" Vector__XXX
 SG_ TRCM_a062_XCPWasConnected m1 : 5|1@1+ (1,0) [0|1] "" Vector__XXX
 SG_ TRCM_a063_SwitchFault m1 : 6|1@1+ (1,0) [0|1] "" Vector__XXX
 SG_ TRCM_a064_busSleepReqTimeout m1 : 7|1@1+ (1,0) [0|1] "" Vector__XXX
 SG_ TRCM_a065_vSafingFetUnderVoltage m1 : 8|1@1+ (1,0) [0|1] "" Vector__XXX
 SG_ TRCM_a066_vBusAUnderVoltage m1 : 9|1@1+ (1,0) [0|1] "" Vector__XXX
 SG_ TRCM_a067_vBusBUnderVoltage m1 : 10|1@1+ (1,0) [0|1] "" Vector__XXX
 SG_ TRCM_a068_vBusCUnderVoltage m1 : 11|1@1+ (1,0) [0|1] "" Vector__XXX
 SG_ TRCM_a069_swAppBoot m1 : 12|1@1+ (1,0) [0|1] "" Vector__XXX
 SG_ TRCM_a070_asm3StatusError m1 : 13|1@1+ (1,0) [0|1] "" Vector__XXX
 SG_ TRCM_a071_asm3DeviceFaulted m1 : 14|1@1+ (1,0) [0|1] "" Vector__XXX
 SG_ TRCM_a072_ais2120StatusError m1 : 15|1@1+ (1,0) [0|1] "" Vector__XXX
 SG_ TRCM_a073_ais2120DeviceFaulted m1 : 16|1@1+ (1,0) [0|1] "" Vector__XXX
 SG_ TRCM_a074_ais2120SelfTestXPositi m1 : 17|1@1+ (1,0) [0|1] "" Vector__XXX
 SG_ TRCM_a075_ais2120SelfTestXNegati m1 : 18|1@1+ (1,0) [0|1] "" Vector__XXX
 SG_ TRCM_a076_ais2120SelfTestYPositi m1 : 19|1@1+ (1,0) [0|1] "" Vector__XXX
 SG_ TRCM_a077_ais2120SelfTestYNegati m1 : 20|1@1+ (1,0) [0|1] "" Vector__XXX
 SG_ TRCM_a081_autarkyActive m1 : 24|1@1+ (1,0) [0|1] "" Vector__XXX
 SG_ TRCM_a082_VCRIGHT_IPC_MIA m1 : 25|1@1+ (1,0) [0|1] "" Vector__XXX
 SG_ TRCM_a083_VCLEFT_IPC_MIA m1 : 26|1@1+ (1,0) [0|1] "" Vector__XXX
 SG_ TRCM_a084_TPMS_MIA m1 : 27|1@1+ (1,0) [0|1] "" Vector__XXX
 SG_ TRCM_a085_CCCM_MIA m1 : 28|1@1+ (1,0) [0|1] "" Vector__XXX
 SG_ TRCM_a086_VCBATT_MIA m1 : 29|1@1+ (1,0) [0|1] "" Vector__XXX
 SG_ TRCM_a087_DIREL_MIA m1 : 30|1@1+ (1,0) [0|1] "" Vector__XXX
 SG_ TRCM_a088_DIRER_MIA m1 : 31|1@1+ (1,0) [0|1] "" Vector__XXX
 SG_ TRCM_a089_IBST_MIA m1 : 32|1@1+ (1,0) [0|1] "" Vector__XXX
 SG_ TRCM_a090_APS_MIA m1 : 33|1@1+ (1,0) [0|1] "" Vector__XXX
 SG_ TRCM_a091_CMPD_MIA m1 : 34|1@1+ (1,0) [0|1] "" Vector__XXX
 SG_ TRCM_a092_VCSEATD_MIA m1 : 35|1@1+ (1,0) [0|1] "" Vector__XXX
 SG_ TRCM_a093_VCSEATP_MIA m1 : 36|1@1+ (1,0) [0|1] "" Vector__XXX
 SG_ TRCM_a094_EPAS3P_MIA m1 : 37|1@1+ (1,0) [0|1] "" Vector__XXX
 SG_ TRCM_a095_CHG_MIA m1 : 38|1@1+ (1,0) [0|1] "" Vector__XXX
 SG_ TRCM_a096_OCS1P_MIA m1 : 39|1@1+ (1,0) [0|1] "" Vector__XXX
 SG_ TRCM_a097_CMP_MIA m1 : 40|1@1+ (1,0) [0|1] "" Vector__XXX
 SG_ TRCM_a098_DIR_MIA m1 : 41|1@1+ (1,0) [0|1] "" Vector__XXX
 SG_ TRCM_a099_PARK_MIA m1 : 42|1@1+ (1,0) [0|1] "" Vector__XXX
 SG_ TRCM_a100_CANbus_MIA m1 : 43|1@1+ (1,0) [0|1] "" Vector__XXX
 SG_ TRCM_a101_PM_MIA m1 : 44|1@1+ (1,0) [0|1] "" Vector__XXX
 SG_ TRCM_a102_PTC_MIA m1 : 45|1@1+ (1,0) [0|1] "" Vector__XXX
 SG_ TRCM_a103_CP_MIA m1 : 46|1@1+ (1,0) [0|1] "" Vector__XXX
 SG_ TRCM_a104_DAS_MIA m1 : 47|1@1+ (1,0) [0|1] "" Vector__XXX
 SG_ TRCM_a105_TAS_MIA m1 : 48|1@1+ (1,0) [0|1] "" Vector__XXX
 SG_ TRCM_a106_PCS_MIA m1 : 49|1@1+ (1,0) [0|1] "" Vector__XXX
 SG_ TRCM_a107_BMS_MIA m1 : 50|1@1+ (1,0) [0|1] "" Vector__XXX
 SG_ TRCM_a108_DIF_MIA m1 : 51|1@1+ (1,0) [0|1] "" Vector__XXX
 SG_ TRCM_a109_RCM_MIA m1 : 52|1@1+ (1,0) [0|1] "" Vector__XXX
 SG_ TRCM_a110_GTW_MIA m1 : 53|1@1+ (1,0) [0|1] "" Vector__XXX
 SG_ TRCM_a111_EPBR_MIA m1 : 54|1@1+ (1,0) [0|1] "" Vector__XXX
 SG_ TRCM_a112_EPBL_MIA m1 : 55|1@1+ (1,0) [0|1] "" Vector__XXX
 SG_ TRCM_a113_UI_MIA m1 : 56|1@1+ (1,0) [0|1] "" Vector__XXX
 SG_ TRCM_a114_ESP_MIA m1 : 57|1@1+ (1,0) [0|1] "" Vector__XXX
 SG_ TRCM_a115_VCSEC_MIA m1 : 58|1@1+ (1,0) [0|1] "" Vector__XXX
 SG_ TRCM_a116_VCRIGHT_MIA m1 : 59|1@1+ (1,0) [0|1] "" Vector__XXX
 SG_ TRCM_a117_VCLEFT_MIA m1 : 60|1@1+ (1,0) [0|1] "" Vector__XXX
 SG_ TRCM_a118_VCFRONT_MIA m1 : 61|1@1+ (1,0) [0|1] "" Vector__XXX
 SG_ TRCM_a119_SCCM_MIA m1 : 62|1@1+ (1,0) [0|1] "" Vector__XXX
 SG_ TRCM_a120_DI_DRIVE_MIA m1 : 63|1@1+ (1,0) [0|1] "" Vector__XXX
 SG_ TRCM_a121_glacierInitialStatusFa m2 : 4|1@1+ (1,0) [0|1] "" Vector__XXX
 SG_ TRCM_a122_glacierTraceabilityRea m2 : 5|1@1+ (1,0) [0|1] "" Vector__XXX
 SG_ TRCM_a123_glacierTraceabilityRea m2 : 6|1@1+ (1,0) [0|1] "" Vector__XXX
 SG_ TRCM_a124_glacierRegisterPattern m2 : 7|1@1+ (1,0) [0|1] "" Vector__XXX
 SG_ TRCM_a125_glacierFixedPatternSel m2 : 8|1@1+ (1,0) [0|1] "" Vector__XXX
 SG_ TRCM_a126_glacierSelfTestEFailur m2 : 9|1@1+ (1,0) [0|1] "" Vector__XXX
 SG_ TRCM_a127_glacierSelfTestFFailur m2 : 10|1@1+ (1,0) [0|1] "" Vector__XXX
 SG_ TRCM_a128_glacierAnalogSelfTestF m2 : 11|1@1+ (1,0) [0|1] "" Vector__XXX
 SG_ TRCM_a129_glacierOscillatorVerif m2 : 12|1@1+ (1,0) [0|1] "" Vector__XXX
 SG_ TRCM_a130_glacierFinalStatusFail m2 : 13|1@1+ (1,0) [0|1] "" Vector__XXX
 SG_ TRCM_a131_glacierOffsetVerificat m2 : 14|1@1+ (1,0) [0|1] "" Vector__XXX
 SG_ TRCM_a132_glacierNormalOperation m2 : 15|1@1+ (1,0) [0|1] "" Vector__XXX
 SG_ TRCM_a133_glacierDeviceReset m2 : 16|1@1+ (1,0) [0|1] "" Vector__XXX
 SG_ TRCM_a134_glacierDeviceFaulted m2 : 17|1@1+ (1,0) [0|1] "" Vector__XXX
 SG_ TRCM_a135_asm5StatusError m2 : 18|1@1+ (1,0) [0|1] "" Vector__XXX
 SG_ TRCM_a136_asm5DeviceFaulted m2 : 19|1@1+ (1,0) [0|1] "" Vector__XXX
 SG_ TRCM_a137_ext1AsicSnoopTestFaile m2 : 20|1@1+ (1,0) [0|1] "" Vector__XXX
 SG_ TRCM_a138_ext2AsicSnoopTestFaile m2 : 21|1@1+ (1,0) [0|1] "" Vector__XXX
 SG_ TRCM_a139_disarmed m2 : 22|1@1+ (1,0) [0|1] "" Vector__XXX
 SG_ TRCM_a140_frontRightAccelInitFai m2 : 23|1@1+ (1,0) [0|1] "" Vector__XXX
 SG_ TRCM_a141_frontRightAccelShortTo m2 : 24|1@1+ (1,0) [0|1] "" Vector__XXX
 SG_ TRCM_a142_frontRightAccelShortTo m2 : 25|1@1+ (1,0) [0|1] "" Vector__XXX
 SG_ TRCM_a143_frontRightAccelConfigE m2 : 26|1@1+ (1,0) [0|1] "" Vector__XXX
 SG_ TRCM_a144_frontRightAccelOpen m2 : 27|1@1+ (1,0) [0|1] "" Vector__XXX
 SG_ TRCM_a145_frontRightAccelCommErr m2 : 28|1@1+ (1,0) [0|1] "" Vector__XXX
 SG_ TRCM_a146_frontRightAccelSensorD m2 : 29|1@1+ (1,0) [0|1] "" Vector__XXX
 SG_ TRCM_a147_frontRightAccelSignalM m2 : 30|1@1+ (1,0) [0|1] "" Vector__XXX
 SG_ TRCM_a150_rightFrontDoorPressure m2 : 33|1@1+ (1,0) [0|1] "" Vector__XXX
 SG_ TRCM_a151_rightFrontDoorPressure m2 : 34|1@1+ (1,0) [0|1] "" Vector__XXX
 SG_ TRCM_a152_rightFrontDoorPressure m2 : 35|1@1+ (1,0) [0|1] "" Vector__XXX
 SG_ TRCM_a153_rightFrontDoorPressure m2 : 36|1@1+ (1,0) [0|1] "" Vector__XXX
 SG_ TRCM_a154_rightFrontDoorPressure m2 : 37|1@1+ (1,0) [0|1] "" Vector__XXX
 SG_ TRCM_a155_rightFrontDoorPressure m2 : 38|1@1+ (1,0) [0|1] "" Vector__XXX
 SG_ TRCM_a156_rightFrontDoorPressure m2 : 39|1@1+ (1,0) [0|1] "" Vector__XXX
 SG_ TRCM_a157_rightFrontDoorPressure m2 : 40|1@1+ (1,0) [0|1] "" Vector__XXX
 SG_ TRCM_a160_frontLeftAccelInitFail m2 : 43|1@1+ (1,0) [0|1] "" Vector__XXX
 SG_ TRCM_a161_frontLeftAccelShortToG m2 : 44|1@1+ (1,0) [0|1] "" Vector__XXX
 SG_ TRCM_a162_frontLeftAccelShortToB m2 : 45|1@1+ (1,0) [0|1] "" Vector__XXX
 SG_ TRCM_a163_frontLeftAccelConfigEr m2 : 46|1@1+ (1,0) [0|1] "" Vector__XXX
 SG_ TRCM_a164_frontLeftAccelOpen m2 : 47|1@1+ (1,0) [0|1] "" Vector__XXX
 SG_ TRCM_a165_frontLeftAccelCommErro m2 : 48|1@1+ (1,0) [0|1] "" Vector__XXX
 SG_ TRCM_a166_frontLeftAccelSensorDe m2 : 49|1@1+ (1,0) [0|1] "" Vector__XXX
 SG_ TRCM_a167_frontLeftAccelSignalMo m2 : 50|1@1+ (1,0) [0|1] "" Vector__XXX
 SG_ TRCM_a170_leftFrontDoorPressureI m2 : 53|1@1+ (1,0) [0|1] "" Vector__XXX
 SG_ TRCM_a171_leftFrontDoorPressureS m2 : 54|1@1+ (1,0) [0|1] "" Vector__XXX
 SG_ TRCM_a172_leftFrontDoorPressureS m2 : 55|1@1+ (1,0) [0|1] "" Vector__XXX
 SG_ TRCM_a173_leftFrontDoorPressureC m2 : 56|1@1+ (1,0) [0|1] "" Vector__XXX
 SG_ TRCM_a174_leftFrontDoorPressureO m2 : 57|1@1+ (1,0) [0|1] "" Vector__XXX
 SG_ TRCM_a175_leftFrontDoorPressureC m2 : 58|1@1+ (1,0) [0|1] "" Vector__XXX
 SG_ TRCM_a176_leftFrontDoorPressureS m2 : 59|1@1+ (1,0) [0|1] "" Vector__XXX
 SG_ TRCM_a177_leftFrontDoorPressureS m2 : 60|1@1+ (1,0) [0|1] "" Vector__XXX
 SG_ TRCM_a180_rightBPillarAccelInitF m2 : 63|1@1+ (1,0) [0|1] "" Vector__XXX
 SG_ TRCM_a181_rightBPillarAccelShort m3 : 4|1@1+ (1,0) [0|1] "" Vector__XXX
 SG_ TRCM_a182_rightBPillarAccelShort m3 : 5|1@1+ (1,0) [0|1] "" Vector__XXX
 SG_ TRCM_a183_rightBPillarAccelConfi m3 : 6|1@1+ (1,0) [0|1] "" Vector__XXX
 SG_ TRCM_a184_rightBPillarAccelOpen m3 : 7|1@1+ (1,0) [0|1] "" Vector__XXX
 SG_ TRCM_a185_rightBPillarAccelCommE m3 : 8|1@1+ (1,0) [0|1] "" Vector__XXX
 SG_ TRCM_a186_rightBPillarAccelSenso m3 : 9|1@1+ (1,0) [0|1] "" Vector__XXX
 SG_ TRCM_a187_rightBPillarAccelSigna m3 : 10|1@1+ (1,0) [0|1] "" Vector__XXX
 SG_ TRCM_a190_leftBPillarAccelInitFa m3 : 13|1@1+ (1,0) [0|1] "" Vector__XXX
 SG_ TRCM_a191_leftBPillarAccelShortT m3 : 14|1@1+ (1,0) [0|1] "" Vector__XXX
 SG_ TRCM_a192_leftBPillarAccelShortT m3 : 15|1@1+ (1,0) [0|1] "" Vector__XXX
 SG_ TRCM_a193_leftBPillarAccelConfig m3 : 16|1@1+ (1,0) [0|1] "" Vector__XXX
 SG_ TRCM_a194_leftBPillarAccelOpen m3 : 17|1@1+ (1,0) [0|1] "" Vector__XXX
 SG_ TRCM_a195_leftBPillarAccelCommEr m3 : 18|1@1+ (1,0) [0|1] "" Vector__XXX
 SG_ TRCM_a196_leftBPillarAccelSensor m3 : 19|1@1+ (1,0) [0|1] "" Vector__XXX
 SG_ TRCM_a197_leftBPillarAccelSignal m3 : 20|1@1+ (1,0) [0|1] "" Vector__XXX
 SG_ TRCM_a200_frontCenterAccelInitFa m3 : 23|1@1+ (1,0) [0|1] "" Vector__XXX
 SG_ TRCM_a201_frontCenterAccelShortT m3 : 24|1@1+ (1,0) [0|1] "" Vector__XXX
 SG_ TRCM_a202_frontCenterAccelShortT m3 : 25|1@1+ (1,0) [0|1] "" Vector__XXX
 SG_ TRCM_a203_frontCenterAccelConfig m3 : 26|1@1+ (1,0) [0|1] "" Vector__XXX
 SG_ TRCM_a204_frontCenterAccelOpen m3 : 27|1@1+ (1,0) [0|1] "" Vector__XXX
 SG_ TRCM_a205_frontCenterAccelCommEr m3 : 28|1@1+ (1,0) [0|1] "" Vector__XXX
 SG_ TRCM_a206_frontCenterAccelSensor m3 : 29|1@1+ (1,0) [0|1] "" Vector__XXX
 SG_ TRCM_a207_frontCenterAccelSignal m3 : 30|1@1+ (1,0) [0|1] "" Vector__XXX
 SG_ TRCM_a210_leftCPillarAccelInitFa m3 : 33|1@1+ (1,0) [0|1] "" Vector__XXX
 SG_ TRCM_a211_leftCPillarAccelShortT m3 : 34|1@1+ (1,0) [0|1] "" Vector__XXX
 SG_ TRCM_a212_leftCPillarAccelShortT m3 : 35|1@1+ (1,0) [0|1] "" Vector__XXX
 SG_ TRCM_a213_leftCPillarAccelConfig m3 : 36|1@1+ (1,0) [0|1] "" Vector__XXX
 SG_ TRCM_a214_leftCPillarAccelOpen m3 : 37|1@1+ (1,0) [0|1] "" Vector__XXX
 SG_ TRCM_a215_leftCPillarAccelCommEr m3 : 38|1@1+ (1,0) [0|1] "" Vector__XXX
 SG_ TRCM_a216_leftCPillarAccelSensor m3 : 39|1@1+ (1,0) [0|1] "" Vector__XXX
 SG_ TRCM_a217_leftCPillarAccelSignal m3 : 40|1@1+ (1,0) [0|1] "" Vector__XXX
 SG_ TRCM_a220_rightCPillarAccelInitF m3 : 43|1@1+ (1,0) [0|1] "" Vector__XXX
 SG_ TRCM_a221_rightCPillarAccelShort m3 : 44|1@1+ (1,0) [0|1] "" Vector__XXX
 SG_ TRCM_a222_rightCPillarAccelShort m3 : 45|1@1+ (1,0) [0|1] "" Vector__XXX
 SG_ TRCM_a223_rightCPillarAccelConfi m3 : 46|1@1+ (1,0) [0|1] "" Vector__XXX
 SG_ TRCM_a224_rightCPillarAccelOpen m3 : 47|1@1+ (1,0) [0|1] "" Vector__XXX
 SG_ TRCM_a225_rightCPillarAccelCommE m3 : 48|1@1+ (1,0) [0|1] "" Vector__XXX
 SG_ TRCM_a226_rightCPillarAccelSenso m3 : 49|1@1+ (1,0) [0|1] "" Vector__XXX
 SG_ TRCM_a227_rightCPillarAccelSigna m3 : 50|1@1+ (1,0) [0|1] "" Vector__XXX
 SG_ TRCM_a230_leftRearDoorPressureIn m3 : 53|1@1+ (1,0) [0|1] "" Vector__XXX
 SG_ TRCM_a231_leftRearDoorPressureSh m3 : 54|1@1+ (1,0) [0|1] "" Vector__XXX
 SG_ TRCM_a232_leftRearDoorPressureSh m3 : 55|1@1+ (1,0) [0|1] "" Vector__XXX
 SG_ TRCM_a233_leftRearDoorPressureCo m3 : 56|1@1+ (1,0) [0|1] "" Vector__XXX
 SG_ TRCM_a234_leftRearDoorPressureOp m3 : 57|1@1+ (1,0) [0|1] "" Vector__XXX
 SG_ TRCM_a235_leftRearDoorPressureCo m3 : 58|1@1+ (1,0) [0|1] "" Vector__XXX
 SG_ TRCM_a236_leftRearDoorPressureSe m3 : 59|1@1+ (1,0) [0|1] "" Vector__XXX
 SG_ TRCM_a237_leftRearDoorPressureSi m3 : 60|1@1+ (1,0) [0|1] "" Vector__XXX
 SG_ TRCM_a240_rightRearDoorPressureI m3 : 63|1@1+ (1,0) [0|1] "" Vector__XXX
 SG_ TRCM_a241_rightRearDoorPressureS m4 : 4|1@1+ (1,0) [0|1] "" Vector__XXX
 SG_ TRCM_a242_rightRearDoorPressureS m4 : 5|1@1+ (1,0) [0|1] "" Vector__XXX
 SG_ TRCM_a243_rightRearDoorPressureC m4 : 6|1@1+ (1,0) [0|1] "" Vector__XXX
 SG_ TRCM_a244_rightRearDoorPressureO m4 : 7|1@1+ (1,0) [0|1] "" Vector__XXX
 SG_ TRCM_a245_rightRearDoorPressureC m4 : 8|1@1+ (1,0) [0|1] "" Vector__XXX
 SG_ TRCM_a246_rightRearDoorPressureS m4 : 9|1@1+ (1,0) [0|1] "" Vector__XXX
 SG_ TRCM_a247_rightRearDoorPressureS m4 : 10|1@1+ (1,0) [0|1] "" Vector__XXX
 SG_ TRCM_a250_frontCenterAccelXInitF m4 : 13|1@1+ (1,0) [0|1] "" Vector__XXX
 SG_ TRCM_a251_frontCenterAccelXShort m4 : 14|1@1+ (1,0) [0|1] "" Vector__XXX
 SG_ TRCM_a252_frontCenterAccelXShort m4 : 15|1@1+ (1,0) [0|1] "" Vector__XXX
 SG_ TRCM_a253_frontCenterAccelXConfi m4 : 16|1@1+ (1,0) [0|1] "" Vector__XXX
 SG_ TRCM_a254_frontCenterAccelXOpen m4 : 17|1@1+ (1,0) [0|1] "" Vector__XXX
 SG_ TRCM_a255_frontCenterAccelXCommE m4 : 18|1@1+ (1,0) [0|1] "" Vector__XXX
 SG_ TRCM_a256_frontCenterAccelXSenso m4 : 19|1@1+ (1,0) [0|1] "" Vector__XXX
 SG_ TRCM_a257_frontCenterAccelXSigna m4 : 20|1@1+ (1,0) [0|1] "" Vector__XXX
 SG_ TRCM_a260_frontCenterAccelYInitF m4 : 23|1@1+ (1,0) [0|1] "" Vector__XXX
 SG_ TRCM_a261_frontCenterAccelYShort m4 : 24|1@1+ (1,0) [0|1] "" Vector__XXX
 SG_ TRCM_a262_frontCenterAccelYShort m4 : 25|1@1+ (1,0) [0|1] "" Vector__XXX
 SG_ TRCM_a263_frontCenterAccelYConfi m4 : 26|1@1+ (1,0) [0|1] "" Vector__XXX
 SG_ TRCM_a264_frontCenterAccelYOpen m4 : 27|1@1+ (1,0) [0|1] "" Vector__XXX
 SG_ TRCM_a265_frontCenterAccelYCommE m4 : 28|1@1+ (1,0) [0|1] "" Vector__XXX
 SG_ TRCM_a266_frontCenterAccelYSenso m4 : 29|1@1+ (1,0) [0|1] "" Vector__XXX
 SG_ TRCM_a267_frontCenterAccelYSigna m4 : 30|1@1+ (1,0) [0|1] "" Vector__XXX
 SG_ TRCM_a272_asm5ComStatusError m4 : 35|1@1+ (1,0) [0|1] "" Vector__XXX
 SG_ TRCM_a273_asm5ArsStatusXError m4 : 36|1@1+ (1,0) [0|1] "" Vector__XXX
 SG_ TRCM_a274_asm5ArsStatusZError m4 : 37|1@1+ (1,0) [0|1] "" Vector__XXX
 SG_ TRCM_a275_asm5AccStatusError m4 : 38|1@1+ (1,0) [0|1] "" Vector__XXX
 SG_ TRCM_a276_watchdogStatus m4 : 39|1@1+ (1,0) [0|1] "" Vector__XXX
 SG_ TRCM_a278_safingEngine0Armed m4 : 41|1@1+ (1,0) [0|1] "" Vector__XXX
 SG_ TRCM_a279_safingEngine1Armed m4 : 42|1@1+ (1,0) [0|1] "" Vector__XXX
 SG_ TRCM_a280_safingEngine2Armed m4 : 43|1@1+ (1,0) [0|1] "" Vector__XXX
 SG_ TRCM_a281_safingEngine3Armed m4 : 44|1@1+ (1,0) [0|1] "" Vector__XXX
 SG_ TRCM_a282_safingEngine4Armed m4 : 45|1@1+ (1,0) [0|1] "" Vector__XXX
 SG_ TRCM_a283_safingEngine5Armed m4 : 46|1@1+ (1,0) [0|1] "" Vector__XXX
 SG_ TRCM_a284_safingEngine6Armed m4 : 47|1@1+ (1,0) [0|1] "" Vector__XXX
 SG_ TRCM_a285_safingEngine7Armed m4 : 48|1@1+ (1,0) [0|1] "" Vector__XXX
 SG_ TRCM_a286_safingEngine8Armed m4 : 49|1@1+ (1,0) [0|1] "" Vector__XXX
 SG_ TRCM_a287_safingEngine9Armed m4 : 50|1@1+ (1,0) [0|1] "" Vector__XXX
 SG_ TRCM_a288_safingEngine10Armed m4 : 51|1@1+ (1,0) [0|1] "" Vector__XXX
 SG_ TRCM_a289_safingEngine11Armed m4 : 52|1@1+ (1,0) [0|1] "" Vector__XXX
 SG_ TRCM_a290_safingEngine12Armed m4 : 53|1@1+ (1,0) [0|1] "" Vector__XXX
 SG_ TRCM_a291_safingEngine13Armed m4 : 54|1@1+ (1,0) [0|1] "" Vector__XXX
 SG_ TRCM_a292_safingEngine14Armed m4 : 55|1@1+ (1,0) [0|1] "" Vector__XXX
 SG_ TRCM_a293_safingEngine15Armed m4 : 56|1@1+ (1,0) [0|1] "" Vector__XXX
 SG_ TRCM_a294_safingEngine16Armed m4 : 57|1@1+ (1,0) [0|1] "" Vector__XXX
 SG_ TRCM_a295_safingEngine17Armed m4 : 58|1@1+ (1,0) [0|1] "" Vector__XXX
 SG_ TRCM_a296_safingEngine18Armed m4 : 59|1@1+ (1,0) [0|1] "" Vector__XXX
 SG_ TRCM_a297_safingEngine19Armed m4 : 60|1@1+ (1,0) [0|1] "" Vector__XXX
 SG_ TRCM_a298_safingEngine20Armed m4 : 61|1@1+ (1,0) [0|1] "" Vector__XXX
 SG_ TRCM_a299_safingEngine21Armed m4 : 62|1@1+ (1,0) [0|1] "" Vector__XXX
 SG_ TRCM_a300_unarmedAB1FPDeployComm m4 : 63|1@1+ (1,0) [0|1] "" Vector__XXX
 SG_ TRCM_a301_unarmedAB1FDDeployComm m5 : 4|1@1+ (1,0) [0|1] "" Vector__XXX
 SG_ TRCM_a302_unarmedAV1FPDeployComm m5 : 5|1@1+ (1,0) [0|1] "" Vector__XXX
 SG_ TRCM_a303_unarmedFSABDeployComma m5 : 6|1@1+ (1,0) [0|1] "" Vector__XXX
 SG_ TRCM_a304_unarmedAB2FPDeployComm m5 : 7|1@1+ (1,0) [0|1] "" Vector__XXX
 SG_ TRCM_a305_unarmedAB2FDDeployComm m5 : 8|1@1+ (1,0) [0|1] "" Vector__XXX
 SG_ TRCM_a306_unarmedAV1FDDeployComm m5 : 9|1@1+ (1,0) [0|1] "" Vector__XXX
 SG_ TRCM_a307_unarmedLoop7DeployComm m5 : 10|1@1+ (1,0) [0|1] "" Vector__XXX
 SG_ TRCM_a308_unarmedKA1FPDeployComm m5 : 11|1@1+ (1,0) [0|1] "" Vector__XXX
 SG_ TRCM_a309_unarmedKA1FDDeployComm m5 : 12|1@1+ (1,0) [0|1] "" Vector__XXX
 SG_ TRCM_a310_unarmedALLFRDeployComm m5 : 13|1@1+ (1,0) [0|1] "" Vector__XXX
 SG_ TRCM_a311_unarmedALLFLDeployComm m5 : 14|1@1+ (1,0) [0|1] "" Vector__XXX
 SG_ TRCM_a312_unarmedBT2FRDeployComm m5 : 15|1@1+ (1,0) [0|1] "" Vector__XXX
 SG_ TRCM_a313_unarmedBT2FLDeployComm m5 : 16|1@1+ (1,0) [0|1] "" Vector__XXX
 SG_ TRCM_a314_unarmedSA1FLDeployComm m5 : 17|1@1+ (1,0) [0|1] "" Vector__XXX
 SG_ TRCM_a315_unarmedSA1FRDeployComm m5 : 18|1@1+ (1,0) [0|1] "" Vector__XXX
 SG_ TRCM_a316_unarmedBT1RRDeployComm m5 : 19|1@1+ (1,0) [0|1] "" Vector__XXX
 SG_ TRCM_a317_unarmedBT1RLDeployComm m5 : 20|1@1+ (1,0) [0|1] "" Vector__XXX
 SG_ TRCM_a318_unarmedBT1FRDeployComm m5 : 21|1@1+ (1,0) [0|1] "" Vector__XXX
 SG_ TRCM_a319_unarmedBT1FLDeployComm m5 : 22|1@1+ (1,0) [0|1] "" Vector__XXX
 SG_ TRCM_a320_unarmedLoop20DeployCom m5 : 23|1@1+ (1,0) [0|1] "" Vector__XXX
 SG_ TRCM_a321_unarmedLoop21DeployCom m5 : 24|1@1+ (1,0) [0|1] "" Vector__XXX
 SG_ TRCM_a322_unarmedIC1FRDeployComm m5 : 25|1@1+ (1,0) [0|1] "" Vector__XXX
 SG_ TRCM_a323_unarmedIC1FLDeployComm m5 : 26|1@1+ (1,0) [0|1] "" Vector__XXX
 SG_ TRCM_a324_unarmedLoop24DeployCom m5 : 27|1@1+ (1,0) [0|1] "" Vector__XXX
 SG_ TRCM_a325_unarmedLoop25DeployCom m5 : 28|1@1+ (1,0) [0|1] "" Vector__XXX
 SG_ TRCM_a326_unarmedLoop26DeployCom m5 : 29|1@1+ (1,0) [0|1] "" Vector__XXX
 SG_ TRCM_a327_unarmedLoop27DeployCom m5 : 30|1@1+ (1,0) [0|1] "" Vector__XXX
 SG_ TRCM_a328_unarmedLoop28DeployCom m5 : 31|1@1+ (1,0) [0|1] "" Vector__XXX
 SG_ TRCM_a329_unarmedLoop29DeployCom m5 : 32|1@1+ (1,0) [0|1] "" Vector__XXX
 SG_ TRCM_a330_unarmedLoop30DeployCom m5 : 33|1@1+ (1,0) [0|1] "" Vector__XXX
 SG_ TRCM_a331_unarmedLoop31DeployCom m5 : 34|1@1+ (1,0) [0|1] "" Vector__XXX
 SG_ TRCM_a332_AB1FPDeployment m5 : 35|1@1+ (1,0) [0|1] "" Vector__XXX
 SG_ TRCM_a333_AB1FDDeployment m5 : 36|1@1+ (1,0) [0|1] "" Vector__XXX
 SG_ TRCM_a334_AV1FPDeployment m5 : 37|1@1+ (1,0) [0|1] "" Vector__XXX
 SG_ TRCM_a335_Loop3Deployment m5 : 38|1@1+ (1,0) [0|1] "" Vector__XXX
 SG_ TRCM_a336_AB2FPDeployment m5 : 39|1@1+ (1,0) [0|1] "" Vector__XXX
 SG_ TRCM_a337_AB2FDDeployment m5 : 40|1@1+ (1,0) [0|1] "" Vector__XXX
 SG_ TRCM_a338_AV1FDDeployment m5 : 41|1@1+ (1,0) [0|1] "" Vector__XXX
 SG_ TRCM_a339_Loop7Deployment m5 : 42|1@1+ (1,0) [0|1] "" Vector__XXX
 SG_ TRCM_a340_KA1FPDeployment m5 : 43|1@1+ (1,0) [0|1] "" Vector__XXX
 SG_ TRCM_a341_KA1FDDeployment m5 : 44|1@1+ (1,0) [0|1] "" Vector__XXX
 SG_ TRCM_a342_ALLFRDeployment m5 : 45|1@1+ (1,0) [0|1] "" Vector__XXX
 SG_ TRCM_a343_ALLFLDeployment m5 : 46|1@1+ (1,0) [0|1] "" Vector__XXX
 SG_ TRCM_a344_BT2FRDeployment m5 : 47|1@1+ (1,0) [0|1] "" Vector__XXX
 SG_ TRCM_a345_BT2FLDeployment m5 : 48|1@1+ (1,0) [0|1] "" Vector__XXX
 SG_ TRCM_a346_SA1FLDeployment m5 : 49|1@1+ (1,0) [0|1] "" Vector__XXX
 SG_ TRCM_a347_SA1FRDeployment m5 : 50|1@1+ (1,0) [0|1] "" Vector__XXX
 SG_ TRCM_a348_BT1RRDeployment m5 : 51|1@1+ (1,0) [0|1] "" Vector__XXX
 SG_ TRCM_a349_BT1RLDeployment m5 : 52|1@1+ (1,0) [0|1] "" Vector__XXX
 SG_ TRCM_a350_BT1FRDeployment m5 : 53|1@1+ (1,0) [0|1] "" Vector__XXX
 SG_ TRCM_a351_BT1FLDeployment m5 : 54|1@1+ (1,0) [0|1] "" Vector__XXX
 SG_ TRCM_a352_Loop20Deployment m5 : 55|1@1+ (1,0) [0|1] "" Vector__XXX
 SG_ TRCM_a353_Loop21Deployment m5 : 56|1@1+ (1,0) [0|1] "" Vector__XXX
 SG_ TRCM_a354_IC1FRDeployment m5 : 57|1@1+ (1,0) [0|1] "" Vector__XXX
 SG_ TRCM_a355_IC1FLDeployment m5 : 58|1@1+ (1,0) [0|1] "" Vector__XXX
 SG_ TRCM_a356_Loop24Deployment m5 : 59|1@1+ (1,0) [0|1] "" Vector__XXX
 SG_ TRCM_a357_Loop25Deployment m5 : 60|1@1+ (1,0) [0|1] "" Vector__XXX
 SG_ TRCM_a358_Loop26Deployment m5 : 61|1@1+ (1,0) [0|1] "" Vector__XXX
 SG_ TRCM_a359_Loop27Deployment m5 : 62|1@1+ (1,0) [0|1] "" Vector__XXX
 SG_ TRCM_a360_Loop28Deployment m5 : 63|1@1+ (1,0) [0|1] "" Vector__XXX
 SG_ TRCM_a361_Loop29Deployment m6 : 4|1@1+ (1,0) [0|1] "" Vector__XXX
 SG_ TRCM_a362_Loop30Deployment m6 : 5|1@1+ (1,0) [0|1] "" Vector__XXX
 SG_ TRCM_a363_Loop31Deployment m6 : 6|1@1+ (1,0) [0|1] "" Vector__XXX
 SG_ TRCM_a364_safingEngine0NoValidDa m6 : 7|1@1+ (1,0) [0|1] "" Vector__XXX
 SG_ TRCM_a365_safingEngine1NoValidDa m6 : 8|1@1+ (1,0) [0|1] "" Vector__XXX
 SG_ TRCM_a366_safingEngine2NoValidDa m6 : 9|1@1+ (1,0) [0|1] "" Vector__XXX
 SG_ TRCM_a367_safingEngine3NoValidDa m6 : 10|1@1+ (1,0) [0|1] "" Vector__XXX
 SG_ TRCM_a368_safingEngine4NoValidDa m6 : 11|1@1+ (1,0) [0|1] "" Vector__XXX
 SG_ TRCM_a369_safingEngine5NoValidDa m6 : 12|1@1+ (1,0) [0|1] "" Vector__XXX
 SG_ TRCM_a370_safingEngine6NoValidDa m6 : 13|1@1+ (1,0) [0|1] "" Vector__XXX
 SG_ TRCM_a371_safingEngine7NoValidDa m6 : 14|1@1+ (1,0) [0|1] "" Vector__XXX
 SG_ TRCM_a372_safingEngine8NoValidDa m6 : 15|1@1+ (1,0) [0|1] "" Vector__XXX
 SG_ TRCM_a373_safingEngine9NoValidDa m6 : 16|1@1+ (1,0) [0|1] "" Vector__XXX
 SG_ TRCM_a374_safingEngine10NoValidD m6 : 17|1@1+ (1,0) [0|1] "" Vector__XXX
 SG_ TRCM_a375_safingEngine11NoValidD m6 : 18|1@1+ (1,0) [0|1] "" Vector__XXX
 SG_ TRCM_a376_safingEngine12NoValidD m6 : 19|1@1+ (1,0) [0|1] "" Vector__XXX
 SG_ TRCM_a377_safingEngine13NoValidD m6 : 20|1@1+ (1,0) [0|1] "" Vector__XXX
 SG_ TRCM_a378_safingEngine14NoValidD m6 : 21|1@1+ (1,0) [0|1] "" Vector__XXX
 SG_ TRCM_a379_safingEngine15NoValidD m6 : 22|1@1+ (1,0) [0|1] "" Vector__XXX
 SG_ TRCM_a380_safingEngine16NoValidD m6 : 23|1@1+ (1,0) [0|1] "" Vector__XXX
 SG_ TRCM_a381_safingEngine17NoValidD m6 : 24|1@1+ (1,0) [0|1] "" Vector__XXX
 SG_ TRCM_a382_safingEngine18NoValidD m6 : 25|1@1+ (1,0) [0|1] "" Vector__XXX
 SG_ TRCM_a383_safingEngine19NoValidD m6 : 26|1@1+ (1,0) [0|1] "" Vector__XXX
 SG_ TRCM_a384_safingEngine20NoValidD m6 : 27|1@1+ (1,0) [0|1] "" Vector__XXX
 SG_ TRCM_a385_safingEngine21NoValidD m6 : 28|1@1+ (1,0) [0|1] "" Vector__XXX
 SG_ TRCM_a387_primaryAsicResetSource m6 : 30|1@1+ (1,0) [0|1] "" Vector__XXX
 SG_ TRCM_a388_cpuLoadHigh m6 : 31|1@1+ (1,0) [0|1] "" Vector__XXX
 SG_ TRCM_a389_asicPwrStatusError m6 : 32|1@1+ (1,0) [0|1] "" Vector__XXX
 SG_ TRCM_a390_systemAsicClockOrOpera m6 : 33|1@1+ (1,0) [0|1] "" Vector__XXX
 SG_ TRCM_a391_extAsic1ClockOrOperati m6 : 34|1@1+ (1,0) [0|1] "" Vector__XXX
 SG_ TRCM_a392_extAsic2ClockOrOperati m6 : 35|1@1+ (1,0) [0|1] "" Vector__XXX
 SG_ TRCM_a393_depAdcConvertRatioErro m6 : 36|1@1+ (1,0) [0|1] "" Vector__XXX
 SG_ TRCM_a394_gspiGlobalStatusWordEr m6 : 37|1@1+ (1,0) [0|1] "" Vector__XXX
 SG_ TRCM_a395_imuCalibrationNotDone m6 : 38|1@1+ (1,0) [0|1] "" Vector__XXX
 SG_ TRCM_a396_spiCommunicationProgra m6 : 39|1@1+ (1,0) [0|1] "" Vector__XXX
 SG_ TRCM_a397_safingMonitorError m6 : 40|1@1+ (1,0) [0|1] "" Vector__XXX
 SG_ TRCM_a398_asicNvmReprogrammed m6 : 41|1@1+ (1,0) [0|1] "" Vector__XXX
 SG_ TRCM_a400_AB1FPShortToGround m6 : 43|1@1+ (1,0) [0|1] "" Vector__XXX
 SG_ TRCM_a401_AB1FPShortToBattery m6 : 44|1@1+ (1,0) [0|1] "" Vector__XXX
 SG_ TRCM_a402_AB1FPOpen m6 : 45|1@1+ (1,0) [0|1] "" Vector__XXX
 SG_ TRCM_a403_AB1FPShortToSelf m6 : 46|1@1+ (1,0) [0|1] "" Vector__XXX
 SG_ TRCM_a404_AB1FPCrossCoupled m6 : 47|1@1+ (1,0) [0|1] "" Vector__XXX
 SG_ TRCM_a405_AB1FPConfigError m6 : 48|1@1+ (1,0) [0|1] "" Vector__XXX
 SG_ TRCM_a406_AB1FDShortToGround m6 : 49|1@1+ (1,0) [0|1] "" Vector__XXX
 SG_ TRCM_a407_AB1FDShortToBattery m6 : 50|1@1+ (1,0) [0|1] "" Vector__XXX
 SG_ TRCM_a408_AB1FDOpen m6 : 51|1@1+ (1,0) [0|1] "" Vector__XXX
 SG_ TRCM_a409_AB1FDShortToSelf m6 : 52|1@1+ (1,0) [0|1] "" Vector__XXX
 SG_ TRCM_a410_AB1FDCrossCoupled m6 : 53|1@1+ (1,0) [0|1] "" Vector__XXX
 SG_ TRCM_a411_AB1FDConfigError m6 : 54|1@1+ (1,0) [0|1] "" Vector__XXX
 SG_ TRCM_a412_PAVShortToGround m6 : 55|1@1+ (1,0) [0|1] "" Vector__XXX
 SG_ TRCM_a413_PAVShortToBattery m6 : 56|1@1+ (1,0) [0|1] "" Vector__XXX
 SG_ TRCM_a414_PAVOpen m6 : 57|1@1+ (1,0) [0|1] "" Vector__XXX
 SG_ TRCM_a415_PAVShortToSelf m6 : 58|1@1+ (1,0) [0|1] "" Vector__XXX
 SG_ TRCM_a416_PAVCrossCoupled m6 : 59|1@1+ (1,0) [0|1] "" Vector__XXX
 SG_ TRCM_a417_PAVConfigError m6 : 60|1@1+ (1,0) [0|1] "" Vector__XXX
 SG_ TRCM_a418_AB2FPShortToGround m6 : 61|1@1+ (1,0) [0|1] "" Vector__XXX
 SG_ TRCM_a419_AB2FPShortToBattery m6 : 62|1@1+ (1,0) [0|1] "" Vector__XXX
 SG_ TRCM_a420_AB2FPOpen m6 : 63|1@1+ (1,0) [0|1] "" Vector__XXX
 SG_ TRCM_a421_AB2FPShortToSelf m7 : 4|1@1+ (1,0) [0|1] "" Vector__XXX
 SG_ TRCM_a422_AB2FPCrossCoupled m7 : 5|1@1+ (1,0) [0|1] "" Vector__XXX
 SG_ TRCM_a423_AB2FPConfigError m7 : 6|1@1+ (1,0) [0|1] "" Vector__XXX
 SG_ TRCM_a424_AB2FDShortToGround m7 : 7|1@1+ (1,0) [0|1] "" Vector__XXX
 SG_ TRCM_a425_AB2FDShortToBattery m7 : 8|1@1+ (1,0) [0|1] "" Vector__XXX
 SG_ TRCM_a426_AB2FDOpen m7 : 9|1@1+ (1,0) [0|1] "" Vector__XXX
 SG_ TRCM_a427_AB2FDShortToSelf m7 : 10|1@1+ (1,0) [0|1] "" Vector__XXX
 SG_ TRCM_a428_AB2FDCrossCoupled m7 : 11|1@1+ (1,0) [0|1] "" Vector__XXX
 SG_ TRCM_a429_AB2FDConfigError m7 : 12|1@1+ (1,0) [0|1] "" Vector__XXX
 SG_ TRCM_a430_DAVShortToGround m7 : 13|1@1+ (1,0) [0|1] "" Vector__XXX
 SG_ TRCM_a431_DAVShortToBattery m7 : 14|1@1+ (1,0) [0|1] "" Vector__XXX
 SG_ TRCM_a432_DAVOpen m7 : 15|1@1+ (1,0) [0|1] "" Vector__XXX
 SG_ TRCM_a433_DAVShortToSelf m7 : 16|1@1+ (1,0) [0|1] "" Vector__XXX
 SG_ TRCM_a434_DAVCrossCoupled m7 : 17|1@1+ (1,0) [0|1] "" Vector__XXX
 SG_ TRCM_a435_DAVConfigError m7 : 18|1@1+ (1,0) [0|1] "" Vector__XXX
 SG_ TRCM_a436_IKBFPShortToGround m7 : 19|1@1+ (1,0) [0|1] "" Vector__XXX
 SG_ TRCM_a437_IKBFPShortToBattery m7 : 20|1@1+ (1,0) [0|1] "" Vector__XXX
 SG_ TRCM_a438_IKBFPOpen m7 : 21|1@1+ (1,0) [0|1] "" Vector__XXX
 SG_ TRCM_a439_IKBFPShortToSelf m7 : 22|1@1+ (1,0) [0|1] "" Vector__XXX
 SG_ TRCM_a440_IKBFPCrossCoupled m7 : 23|1@1+ (1,0) [0|1] "" Vector__XXX
 SG_ TRCM_a441_IKBFPConfigError m7 : 24|1@1+ (1,0) [0|1] "" Vector__XXX
 SG_ TRCM_a442_IKBFDShortToGround m7 : 25|1@1+ (1,0) [0|1] "" Vector__XXX
 SG_ TRCM_a443_IKBFDShortToBattery m7 : 26|1@1+ (1,0) [0|1] "" Vector__XXX
 SG_ TRCM_a444_IKBFDOpen m7 : 27|1@1+ (1,0) [0|1] "" Vector__XXX
 SG_ TRCM_a445_IKBFDShortToSelf m7 : 28|1@1+ (1,0) [0|1] "" Vector__XXX
 SG_ TRCM_a446_IKBFDCrossCoupled m7 : 29|1@1+ (1,0) [0|1] "" Vector__XXX
 SG_ TRCM_a447_IKBFDConfigError m7 : 30|1@1+ (1,0) [0|1] "" Vector__XXX
 SG_ TRCM_a448_PLLShortToGround m7 : 31|1@1+ (1,0) [0|1] "" Vector__XXX
 SG_ TRCM_a449_PLLShortToBattery m7 : 32|1@1+ (1,0) [0|1] "" Vector__XXX
 SG_ TRCM_a450_PLLOpen m7 : 33|1@1+ (1,0) [0|1] "" Vector__XXX
 SG_ TRCM_a451_PLLShortToSelf m7 : 34|1@1+ (1,0) [0|1] "" Vector__XXX
 SG_ TRCM_a452_PLLCrossCoupled m7 : 35|1@1+ (1,0) [0|1] "" Vector__XXX
 SG_ TRCM_a453_PLLConfigError m7 : 36|1@1+ (1,0) [0|1] "" Vector__XXX
 SG_ TRCM_a454_DLLShortToGround m7 : 37|1@1+ (1,0) [0|1] "" Vector__XXX
 SG_ TRCM_a455_DLLShortToBattery m7 : 38|1@1+ (1,0) [0|1] "" Vector__XXX
 SG_ TRCM_a456_DLLOpen m7 : 39|1@1+ (1,0) [0|1] "" Vector__XXX
 SG_ TRCM_a457_DLLShortToSelf m7 : 40|1@1+ (1,0) [0|1] "" Vector__XXX
 SG_ TRCM_a458_DLLCrossCoupled m7 : 41|1@1+ (1,0) [0|1] "" Vector__XXX
 SG_ TRCM_a459_DLLConfigError m7 : 42|1@1+ (1,0) [0|1] "" Vector__XXX
 SG_ TRCM_a460_BTRP_RetractorShortToG m7 : 43|1@1+ (1,0) [0|1] "" Vector__XXX
 SG_ TRCM_a461_BTRP_RetractorShortToB m7 : 44|1@1+ (1,0) [0|1] "" Vector__XXX
 SG_ TRCM_a462_BTRP_RetractorOpen m7 : 45|1@1+ (1,0) [0|1] "" Vector__XXX
 SG_ TRCM_a463_BTRP_RetractorShortToS m7 : 46|1@1+ (1,0) [0|1] "" Vector__XXX
 SG_ TRCM_a464_BTRP_RetractorCrossCou m7 : 47|1@1+ (1,0) [0|1] "" Vector__XXX
 SG_ TRCM_a465_BTRP_RetractorConfigEr m7 : 48|1@1+ (1,0) [0|1] "" Vector__XXX
 SG_ TRCM_a466_BTRD_RetractorShortToG m7 : 49|1@1+ (1,0) [0|1] "" Vector__XXX
 SG_ TRCM_a467_BTRD_RetractorShortToB m7 : 50|1@1+ (1,0) [0|1] "" Vector__XXX
 SG_ TRCM_a468_BTRD_RetractorOpen m7 : 51|1@1+ (1,0) [0|1] "" Vector__XXX
 SG_ TRCM_a469_BTRD_RetractorShortToS m7 : 52|1@1+ (1,0) [0|1] "" Vector__XXX
 SG_ TRCM_a470_BTRD_RetractorCrossCou m7 : 53|1@1+ (1,0) [0|1] "" Vector__XXX
 SG_ TRCM_a471_BTRD_RetractorConfigEr m7 : 54|1@1+ (1,0) [0|1] "" Vector__XXX
 SG_ TRCM_a472_SA1FLShortToGround m7 : 55|1@1+ (1,0) [0|1] "" Vector__XXX
 SG_ TRCM_a473_SA1FLShortToBattery m7 : 56|1@1+ (1,0) [0|1] "" Vector__XXX
 SG_ TRCM_a474_SA1FLOpen m7 : 57|1@1+ (1,0) [0|1] "" Vector__XXX
 SG_ TRCM_a475_SA1FLShortToSelf m7 : 58|1@1+ (1,0) [0|1] "" Vector__XXX
 SG_ TRCM_a476_SA1FLCrossCoupled m7 : 59|1@1+ (1,0) [0|1] "" Vector__XXX
 SG_ TRCM_a477_SA1FLConfigError m7 : 60|1@1+ (1,0) [0|1] "" Vector__XXX
 SG_ TRCM_a478_SA1FRShortToGround m7 : 61|1@1+ (1,0) [0|1] "" Vector__XXX
 SG_ TRCM_a479_SA1FRShortToBattery m7 : 62|1@1+ (1,0) [0|1] "" Vector__XXX
 SG_ TRCM_a480_SA1FROpen m7 : 63|1@1+ (1,0) [0|1] "" Vector__XXX
 SG_ TRCM_a481_SA1FRShortToSelf m8 : 4|1@1+ (1,0) [0|1] "" Vector__XXX
 SG_ TRCM_a482_SA1FRCrossCoupled m8 : 5|1@1+ (1,0) [0|1] "" Vector__XXX
 SG_ TRCM_a483_SA1FRConfigError m8 : 6|1@1+ (1,0) [0|1] "" Vector__XXX
 SG_ TRCM_a484_BTRRShortToGround m8 : 7|1@1+ (1,0) [0|1] "" Vector__XXX
 SG_ TRCM_a485_BTRRShortToBattery m8 : 8|1@1+ (1,0) [0|1] "" Vector__XXX
 SG_ TRCM_a486_BTRROpen m8 : 9|1@1+ (1,0) [0|1] "" Vector__XXX
 SG_ TRCM_a487_BTRRShortToSelf m8 : 10|1@1+ (1,0) [0|1] "" Vector__XXX
 SG_ TRCM_a488_BTRRCrossCoupled m8 : 11|1@1+ (1,0) [0|1] "" Vector__XXX
 SG_ TRCM_a489_BTRRConfigError m8 : 12|1@1+ (1,0) [0|1] "" Vector__XXX
 SG_ TRCM_a490_BTRLShortToGround m8 : 13|1@1+ (1,0) [0|1] "" Vector__XXX
 SG_ TRCM_a491_BTRLShortToBattery m8 : 14|1@1+ (1,0) [0|1] "" Vector__XXX
 SG_ TRCM_a492_BTRLOpen m8 : 15|1@1+ (1,0) [0|1] "" Vector__XXX
 SG_ TRCM_a493_BTRLShortToSelf m8 : 16|1@1+ (1,0) [0|1] "" Vector__XXX
 SG_ TRCM_a494_BTRLCrossCoupled m8 : 17|1@1+ (1,0) [0|1] "" Vector__XXX
 SG_ TRCM_a495_BTRLConfigError m8 : 18|1@1+ (1,0) [0|1] "" Vector__XXX
 SG_ TRCM_a496_BTRP_AnchorShortToGrou m8 : 19|1@1+ (1,0) [0|1] "" Vector__XXX
 SG_ TRCM_a497_BTRP_AnchorShortToBatt m8 : 20|1@1+ (1,0) [0|1] "" Vector__XXX
 SG_ TRCM_a498_BTRP_AnchorOpen m8 : 21|1@1+ (1,0) [0|1] "" Vector__XXX
 SG_ TRCM_a499_BTRP_AnchorShortToSelf m8 : 22|1@1+ (1,0) [0|1] "" Vector__XXX
 SG_ TRCM_a500_BTRP_AnchorCrossCouple m8 : 23|1@1+ (1,0) [0|1] "" Vector__XXX
 SG_ TRCM_a501_BTRP_AnchorConfigError m8 : 24|1@1+ (1,0) [0|1] "" Vector__XXX
 SG_ TRCM_a502_BTRD_AnchorShortToGrou m8 : 25|1@1+ (1,0) [0|1] "" Vector__XXX
 SG_ TRCM_a503_BTRD_AnchorShortToBatt m8 : 26|1@1+ (1,0) [0|1] "" Vector__XXX
 SG_ TRCM_a504_BTRD_AnchorOpen m8 : 27|1@1+ (1,0) [0|1] "" Vector__XXX
 SG_ TRCM_a505_BTRD_AnchorShortToSelf m8 : 28|1@1+ (1,0) [0|1] "" Vector__XXX
 SG_ TRCM_a506_BTRD_AnchorCrossCouple m8 : 29|1@1+ (1,0) [0|1] "" Vector__XXX
 SG_ TRCM_a507_BTRD_AnchorConfigError m8 : 30|1@1+ (1,0) [0|1] "" Vector__XXX
 SG_ TRCM_a508_IC1FRShortToGround m8 : 31|1@1+ (1,0) [0|1] "" Vector__XXX
 SG_ TRCM_a509_IC1FRShortToBattery m8 : 32|1@1+ (1,0) [0|1] "" Vector__XXX
 SG_ TRCM_a510_IC1FROpen m8 : 33|1@1+ (1,0) [0|1] "" Vector__XXX
 SG_ TRCM_a511_IC1FRShortToSelf m8 : 34|1@1+ (1,0) [0|1] "" Vector__XXX
 SG_ TRCM_a512_IC1FRCrossCoupled m8 : 35|1@1+ (1,0) [0|1] "" Vector__XXX
 SG_ TRCM_a513_IC1FRConfigError m8 : 36|1@1+ (1,0) [0|1] "" Vector__XXX
 SG_ TRCM_a514_IC1FLShortToGround m8 : 37|1@1+ (1,0) [0|1] "" Vector__XXX
 SG_ TRCM_a515_IC1FLShortToBattery m8 : 38|1@1+ (1,0) [0|1] "" Vector__XXX
 SG_ TRCM_a516_IC1FLOpen m8 : 39|1@1+ (1,0) [0|1] "" Vector__XXX
 SG_ TRCM_a517_IC1FLShortToSelf m8 : 40|1@1+ (1,0) [0|1] "" Vector__XXX
 SG_ TRCM_a518_IC1FLCrossCoupled m8 : 41|1@1+ (1,0) [0|1] "" Vector__XXX
 SG_ TRCM_a519_IC1FLConfigError m8 : 42|1@1+ (1,0) [0|1] "" Vector__XXX
 SG_ TRCM_a520_FSABShortToGround m8 : 43|1@1+ (1,0) [0|1] "" Vector__XXX
 SG_ TRCM_a521_FSABShortToBattery m8 : 44|1@1+ (1,0) [0|1] "" Vector__XXX
 SG_ TRCM_a522_FSABOpen m8 : 45|1@1+ (1,0) [0|1] "" Vector__XXX
 SG_ TRCM_a523_FSABShortToSelf m8 : 46|1@1+ (1,0) [0|1] "" Vector__XXX
 SG_ TRCM_a524_FSABCrossCoupled m8 : 47|1@1+ (1,0) [0|1] "" Vector__XXX
 SG_ TRCM_a525_FSABConfigError m8 : 48|1@1+ (1,0) [0|1] "" Vector__XXX
 SG_ TRCM_a544_erCapDiagnosticsFailed m9 : 7|1@1+ (1,0) [0|1] "" Vector__XXX
 SG_ TRCM_a545_erCapBelowAutarkyThres m9 : 8|1@1+ (1,0) [0|1] "" Vector__XXX
 SG_ TRCM_a546_sensorValuesFaultedByS m9 : 9|1@1+ (1,0) [0|1] "" Vector__XXX
 SG_ TRCM_a550_AlgoWake_RCM_WAKE_FRON m9 : 13|1@1+ (1,0) [0|1] "" Vector__XXX
 SG_ TRCM_a551_AlgoWake_RCM_WAKE_REAR m9 : 14|1@1+ (1,0) [0|1] "" Vector__XXX
 SG_ TRCM_a552_AlgoWake_RCM_WAKE_LEFT m9 : 15|1@1+ (1,0) [0|1] "" Vector__XXX
 SG_ TRCM_a553_AlgoWake_RCM_WAKE_RIGH m9 : 16|1@1+ (1,0) [0|1] "" Vector__XXX
 SG_ TRCM_a554_AlgoWake_PAS_LH_PLAUSI m9 : 17|1@1+ (1,0) [0|1] "" Vector__XXX
 SG_ TRCM_a555_AlgoWake_PAS_LH_PLAUSI m9 : 18|1@1+ (1,0) [0|1] "" Vector__XXX
 SG_ TRCM_a556_AlgoWake_PAS_LH_PLAUSI m9 : 19|1@1+ (1,0) [0|1] "" Vector__XXX
 SG_ TRCM_a557_AlgoWake_PAS_RH_PLAUSI m9 : 20|1@1+ (1,0) [0|1] "" Vector__XXX
 SG_ TRCM_a558_AlgoWake_PAS_RH_PLAUSI m9 : 21|1@1+ (1,0) [0|1] "" Vector__XXX
 SG_ TRCM_a559_AlgoWake_PAS_RH_PLAUSI m9 : 22|1@1+ (1,0) [0|1] "" Vector__XXX
 SG_ TRCM_a560_AlgoWake_RCM_WAKE_ROLL m9 : 23|1@1+ (1,0) [0|1] "" Vector__XXX
 SG_ TRCM_a561_AlgoWake_RCM_WAKE_ROLL m9 : 24|1@1+ (1,0) [0|1] "" Vector__XXX
 SG_ TRCM_a562_AlgoWake_RCM_AWAKE_FRO m9 : 25|1@1+ (1,0) [0|1] "" Vector__XXX
 SG_ TRCM_a563_AlgoWake_RCM_AWAKE_REA m9 : 26|1@1+ (1,0) [0|1] "" Vector__XXX
 SG_ TRCM_a564_AlgoWake_RCM_AWAKE_LEF m9 : 27|1@1+ (1,0) [0|1] "" Vector__XXX
 SG_ TRCM_a565_AlgoWake_RCM_AWAKE_RIG m9 : 28|1@1+ (1,0) [0|1] "" Vector__XXX
 SG_ TRCM_a566_AlgoWake_RCM_AWAKE_ROL m9 : 29|1@1+ (1,0) [0|1] "" Vector__XXX
 SG_ TRCM_a567_AlgoWake_RCM_AWAKE_X m9 : 30|1@1+ (1,0) [0|1] "" Vector__XXX
 SG_ TRCM_a568_AlgoWake_RCM_AWAKE_Y m9 : 31|1@1+ (1,0) [0|1] "" Vector__XXX
 SG_ TRCM_a569_AlgoWake_IMPACT_FINISH m9 : 32|1@1+ (1,0) [0|1] "" Vector__XXX
 SG_ TRCM_a570_AlgoWake_IMPACT_FINISH m9 : 33|1@1+ (1,0) [0|1] "" Vector__XXX
 SG_ TRCM_a571_AlgoWake_IMPACT_FINISH m9 : 34|1@1+ (1,0) [0|1] "" Vector__XXX
 SG_ TRCM_a572_AlgoWake_IMPACT_FINISH m9 : 35|1@1+ (1,0) [0|1] "" Vector__XXX
 SG_ TRCM_a573_AlgoWake_IMPACT_FINISH m9 : 36|1@1+ (1,0) [0|1] "" Vector__XXX
 SG_ TRCM_a574_AlgoWake_IMPACT_FINISH m9 : 37|1@1+ (1,0) [0|1] "" Vector__XXX
 SG_ TRCM_a575_AlgoWake_IMPACT_FINISH m9 : 38|1@1+ (1,0) [0|1] "" Vector__XXX
 SG_ TRCM_a576_AlgoWake_IMPACT_FINISH m9 : 39|1@1+ (1,0) [0|1] "" Vector__XXX
 SG_ TRCM_a577_AlgoWake_IMPACT_FINISH m9 : 40|1@1+ (1,0) [0|1] "" Vector__XXX
 SG_ TRCM_a578_AlgoWake_IMPACT_FINISH m9 : 41|1@1+ (1,0) [0|1] "" Vector__XXX
 SG_ TRCM_a579_AlgoWake_RCM_ENABLED_X m9 : 42|1@1+ (1,0) [0|1] "" Vector__XXX
 SG_ TRCM_a580_AlgoWake_RCM_ENABLED_Y m9 : 43|1@1+ (1,0) [0|1] "" Vector__XXX
 SG_ TRCM_a581_AlgoWake_RCM_ENABLED_R m9 : 44|1@1+ (1,0) [0|1] "" Vector__XXX
 SG_ TRCM_a582_AlgoWake_RCM_AWAKE m9 : 45|1@1+ (1,0) [0|1] "" Vector__XXX
 SG_ TRCM_a588_yawRateOffsetPosLimit m9 : 51|1@1+ (1,0) [0|1] "" Vector__XXX
 SG_ TRCM_a589_yawRateOffsetNegLimit m9 : 52|1@1+ (1,0) [0|1] "" Vector__XXX
 SG_ TRCM_a590_pitchRateOffsetPosLimi m9 : 53|1@1+ (1,0) [0|1] "" Vector__XXX
 SG_ TRCM_a591_pitchRateOffsetNegLimi m9 : 54|1@1+ (1,0) [0|1] "" Vector__XXX
 SG_ TRCM_a592_rollRateOffsetPosLimit m9 : 55|1@1+ (1,0) [0|1] "" Vector__XXX
 SG_ TRCM_a593_rollRateOffsetNegLimit m9 : 56|1@1+ (1,0) [0|1] "" Vector__XXX
 SG_ TRCM_a594_longitudinalAccelOffse m9 : 57|1@1+ (1,0) [0|1] "" Vector__XXX
 SG_ TRCM_a595_longitudinalAccelOffse m9 : 58|1@1+ (1,0) [0|1] "" Vector__XXX
 SG_ TRCM_a596_lateralAccelOffsetPosL m9 : 59|1@1+ (1,0) [0|1] "" Vector__XXX
 SG_ TRCM_a597_lateralAccelOffsetNegL m9 : 60|1@1+ (1,0) [0|1] "" Vector__XXX
 SG_ TRCM_a598_verticalAccelOffsetPos m9 : 61|1@1+ (1,0) [0|1] "" Vector__XXX
 SG_ TRCM_a599_verticalAccelOffsetNeg m9 : 62|1@1+ (1,0) [0|1] "" Vector__XXX
 SG_ TRCM_a600_airbagAsicStartupFailu m9 : 63|1@1+ (1,0) [0|1] "" Vector__XXX
 SG_ TRCM_a601_loop0AsicStartupDiagno m10 : 4|1@1+ (1,0) [0|1] "" Vector__XXX
 SG_ TRCM_a602_loop1AsicStartupDiagno m10 : 5|1@1+ (1,0) [0|1] "" Vector__XXX
 SG_ TRCM_a603_loop2AsicStartupDiagno m10 : 6|1@1+ (1,0) [0|1] "" Vector__XXX
 SG_ TRCM_a604_loop3AsicStartupDiagno m10 : 7|1@1+ (1,0) [0|1] "" Vector__XXX
 SG_ TRCM_a605_loop4AsicStartupDiagno m10 : 8|1@1+ (1,0) [0|1] "" Vector__XXX
 SG_ TRCM_a606_loop5AsicStartupDiagno m10 : 9|1@1+ (1,0) [0|1] "" Vector__XXX
 SG_ TRCM_a607_loop6AsicStartupDiagno m10 : 10|1@1+ (1,0) [0|1] "" Vector__XXX
 SG_ TRCM_a608_loop7AsicStartupDiagno m10 : 11|1@1+ (1,0) [0|1] "" Vector__XXX
 SG_ TRCM_a609_loop8AsicStartupDiagno m10 : 12|1@1+ (1,0) [0|1] "" Vector__XXX
 SG_ TRCM_a610_loop9AsicStartupDiagno m10 : 13|1@1+ (1,0) [0|1] "" Vector__XXX
 SG_ TRCM_a611_loop10AsicStartupDiagn m10 : 14|1@1+ (1,0) [0|1] "" Vector__XXX
 SG_ TRCM_a612_loop11AsicStartupDiagn m10 : 15|1@1+ (1,0) [0|1] "" Vector__XXX
 SG_ TRCM_a613_loop12AsicStartupDiagn m10 : 16|1@1+ (1,0) [0|1] "" Vector__XXX
 SG_ TRCM_a614_loop13AsicStartupDiagn m10 : 17|1@1+ (1,0) [0|1] "" Vector__XXX
 SG_ TRCM_a615_loop14AsicStartupDiagn m10 : 18|1@1+ (1,0) [0|1] "" Vector__XXX
 SG_ TRCM_a616_loop15AsicStartupDiagn m10 : 19|1@1+ (1,0) [0|1] "" Vector__XXX
 SG_ TRCM_a617_loop16AsicStartupDiagn m10 : 20|1@1+ (1,0) [0|1] "" Vector__XXX
 SG_ TRCM_a618_loop17AsicStartupDiagn m10 : 21|1@1+ (1,0) [0|1] "" Vector__XXX
 SG_ TRCM_a619_loop18AsicStartupDiagn m10 : 22|1@1+ (1,0) [0|1] "" Vector__XXX
 SG_ TRCM_a620_loop19AsicStartupDiagn m10 : 23|1@1+ (1,0) [0|1] "" Vector__XXX
 SG_ TRCM_a621_loop20AsicStartupDiagn m10 : 24|1@1+ (1,0) [0|1] "" Vector__XXX
 SG_ TRCM_a622_loop21AsicStartupDiagn m10 : 25|1@1+ (1,0) [0|1] "" Vector__XXX
 SG_ TRCM_a623_loop22AsicStartupDiagn m10 : 26|1@1+ (1,0) [0|1] "" Vector__XXX
 SG_ TRCM_a624_loop23AsicStartupDiagn m10 : 27|1@1+ (1,0) [0|1] "" Vector__XXX
 SG_ TRCM_a625_loop24AsicStartupDiagn m10 : 28|1@1+ (1,0) [0|1] "" Vector__XXX
 SG_ TRCM_a626_loop25AsicStartupDiagn m10 : 29|1@1+ (1,0) [0|1] "" Vector__XXX
 SG_ TRCM_a627_loop26AsicStartupDiagn m10 : 30|1@1+ (1,0) [0|1] "" Vector__XXX
 SG_ TRCM_a628_loop27AsicStartupDiagn m10 : 31|1@1+ (1,0) [0|1] "" Vector__XXX
 SG_ TRCM_a629_loop28AsicStartupDiagn m10 : 32|1@1+ (1,0) [0|1] "" Vector__XXX
 SG_ TRCM_a630_loop29AsicStartupDiagn m10 : 33|1@1+ (1,0) [0|1] "" Vector__XXX
 SG_ TRCM_a631_loop30AsicStartupDiagn m10 : 34|1@1+ (1,0) [0|1] "" Vector__XXX
 SG_ TRCM_a632_loop31AsicStartupDiagn m10 : 35|1@1+ (1,0) [0|1] "" Vector__XXX

BO_ 1641 UDS_KOSTIAsccmRequest: 8 UDS
 SG_ UDS_KOSTIAsccmRequestData : 7|64@0+ (1,0) [0|1.84467440737e+19] "" Vector__XXX

BO_ 1538 UDS_bmsRequest: 8 UDS
 SG_ UDS_bmsRequestData : 7|64@0+ (1,0) [0|1.84467440737e+19] "" Vector__XXX

BO_ 1579 UDS_ccRequest: 8 UDS
 SG_ UDS_ccRequestData : 7|64@0+ (1,0) [0|1.84467440737e+19] "" Vector__XXX

BO_ 1539 UDS_cmpRequest: 8 UDS
 SG_ UDS_cmpRequestData : 7|64@0+ (1,0) [0|1.84467440737e+19] "" Vector__XXX

BO_ 1543 UDS_cmpdRequest: 8 UDS
 SG_ UDS_cmpdRequestData : 7|64@0+ (1,0) [0|1.84467440737e+19] "" Vector__XXX

BO_ 1550 UDS_cpRequest: 8 UDS
 SG_ UDS_cpRequestData : 7|64@0+ (1,0) [0|1.84467440737e+19] "" Vector__XXX

BO_ 1609 UDS_dasRequest: 8 UDS
 SG_ UDS_dasRequestData : 7|64@0+ (1,0) [0|1.84467440737e+19] "" Vector__XXX

BO_ 1589 UDS_diRequest: 8 UDS
 SG_ UDS_diRequestData : 7|64@0+ (1,0) [0|1.84467440737e+19] "" Vector__XXX

BO_ 1541 UDS_difRequest: 8 UDS
 SG_ UDS_difRequestData : 7|64@0+ (1,0) [0|1.84467440737e+19] "" Vector__XXX

BO_ 1542 UDS_dirRequest: 8 UDS
 SG_ UDS_dirRequestData : 7|64@0+ (1,0) [0|1.84467440737e+19] "" Vector__XXX

BO_ 1584 UDS_epas3pRequest: 8 UDS
 SG_ UDS_epas3pRequestData : 7|64@0+ (1,0) [0|1.84467440737e+19] "" Vector__XXX

BO_ 1840 UDS_epas3sRequest: 8 UDS
 SG_ UDS_epas3sRequestData : 7|64@0+ (1,0) [0|1.84467440737e+19] "" Vector__XXX

BO_ 1572 UDS_epblRequest: 8 UDS
 SG_ UDS_epblRequestData_H : 7|32@0+ (1,0) [0|4294967295] "" Vector__XXX
 SG_ UDS_epblRequestData_L : 39|32@0+ (1,0) [0|4294967295] "" Vector__XXX

BO_ 1574 UDS_epbrRequest: 8 UDS
 SG_ UDS_epbrRequestData_H : 7|32@0+ (1,0) [0|4294967295] "" Vector__XXX
 SG_ UDS_epbrRequestData_L : 39|32@0+ (1,0) [0|4294967295] "" Vector__XXX

BO_ 1605 UDS_espRequest: 8 UDS
 SG_ UDS_espRequestData : 7|64@0+ (1,0) [0|1.84467440737e+19] "" Vector__XXX

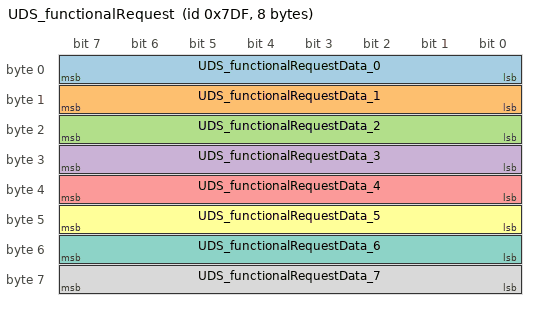
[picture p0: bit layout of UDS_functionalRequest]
BO_ 2015 UDS_functionalRequest: 8 UDS
 SG_ UDS_functionalRequestData_0 : 7|8@0+ (1,0) [0|255] "" Vector__XXX
 SG_ UDS_functionalRequestData_1 : 15|8@0+ (1,0) [0|255] "" Vector__XXX
 SG_ UDS_functionalRequestData_2 : 23|8@0+ (1,0) [0|255] "" Vector__XXX
 SG_ UDS_functionalRequestData_3 : 31|8@0+ (1,0) [0|255] "" Vector__XXX
 SG_ UDS_functionalRequestData_4 : 39|8@0+ (1,0) [0|255] "" Vector__XXX
 SG_ UDS_functionalRequestData_5 : 47|8@0+ (1,0) [0|255] "" Vector__XXX
 SG_ UDS_functionalRequestData_6 : 55|8@0+ (1,0) [0|255] "" Vector__XXX
 SG_ UDS_functionalRequestData_7 : 63|8@0+ (1,0) [0|255] "" Vector__XXX

BO_ 2014 UDS_functionalRequest_CH: 8 UDS
 SG_ UDS_functionalRequestDataCH : 7|64@0+ (1,0) [0|1.84467440737e+19] "" Vector__XXX

BO_ 1552 UDS_hvpRequest: 8 UDS
 SG_ UDS_hvpRequestData : 7|64@0+ (1,0) [0|1.84467440737e+19] "" Vector__XXX

BO_ 1613 UDS_ibstRequest: 8 UDS
 SG_ UDS_ibstRequestData : 7|64@0+ (1,0) [0|1.84467440737e+19] "" Vector__XXX

BO_TX_BU_ 1298 : TRCM;
BO_TX_BU_ 2030 : TRCM;
BO_TX_BU_ 1641 : UDS;
BO_TX_BU_ 1538 : UDS;
BO_TX_BU_ 1579 : UDS;
BO_TX_BU_ 1539 : UDS;
BO_TX_BU_ 1543 : UDS;
BO_TX_BU_ 1550 : UDS;
BO_TX_BU_ 1609 : UDS;
BO_TX_BU_ 1589 : UDS;
BO_TX_BU_ 1541 : UDS;
BO_TX_BU_ 1542 : UDS;
BO_TX_BU_ 1584 : UDS;
BO_TX_BU_ 1840 : UDS;
BO_TX_BU_ 1572 : UDS;
BO_TX_BU_ 1574 : UDS;
BO_TX_BU_ 1605 : UDS;
BO_TX_BU_ 2015 : UDS;
BO_TX_BU_ 2014 : UDS;
BO_TX_BU_ 1552 : UDS;
BO_TX_BU_ 1613 : UDS;
CM_ BO_ 1298 "TRCM ECU message: alert log";
CM_ SG_ 1298 TRCM_alertID "TRCM ECU: alert ID";
CM_ SG_ 1298 TRCM_alertState "TRCM ECU: alert state";
CM_ SG_ 1298 TRCM_a015_NVMMMemOverflow "TRCM ECU: a015 NVMM mem overflow";
CM_ SG_ 1298 TRCM_a015_NVMMFilesystemError "TRCM ECU: a015 NVMM filesystem error";
CM_ SG_ 1298 TRCM_a015_NVMMRecordIDError "TRCM ECU: a015 NVMM record ID error";
CM_ SG_ 1298 TRCM_a057_VEH_cpControl "TRCM ECU: a057 VEH cp control";
CM_ SG_ 1298 TRCM_a059_voltageDrop "TRCM ECU: a059 voltage drop";
CM_ SG_ 1298 TRCM_a059_resistanceEstimate "TRCM ECU: a059 resistance estimate";
CM_ SG_ 1298 TRCM_a059_current "TRCM ECU: a059 current";
CM_ SG_ 1298 TRCM_a063_switchChannel "TRCM ECU: a063 switch channel";
CM_ SG_ 1298 TRCM_a063_switchType "TRCM ECU: a063 switch type";
CM_ SG_ 1298 TRCM_a063_ADCVoltage "TRCM ECU: a063 ADC voltage";
CM_ SG_ 1298 TRCM_a063_disconnected "TRCM ECU: a063 disconnected";
CM_ SG_ 1298 TRCM_a063_indeterminate "TRCM ECU: a063 indeterminate";
CM_ SG_ 1298 TRCM_a063_stuckActive "TRCM ECU: a063 stuck active";
CM_ SG_ 1298 TRCM_a063_faulted "TRCM ECU: a063 faulted";
CM_ SG_ 1298 TRCM_a082_RIPC_epbPrivateState "TRCM ECU: a082 RIPC epb private state";
CM_ SG_ 1298 TRCM_a082_RIPC_remoteHSD "TRCM ECU: a082 RIPC remote HSD";
CM_ SG_ 1298 TRCM_a082_RIPC_railStatus "TRCM ECU: a082 RIPC rail status";
CM_ SG_ 1298 TRCM_a082_RIPC_remoteMux "TRCM ECU: a082 RIPC remote mux";
CM_ SG_ 1298 TRCM_a083_LIPC_epbPrivateState "TRCM ECU: a083 LIPC epb private state";
CM_ SG_ 1298 TRCM_a083_LIPC_remoteHSD "TRCM ECU: a083 LIPC remote HSD";
CM_ SG_ 1298 TRCM_a083_LIPC_railStatus "TRCM ECU: a083 LIPC rail status";
CM_ SG_ 1298 TRCM_a083_LIPC_HSDFaults "TRCM ECU: a083 LIPC HSD faults";
CM_ SG_ 1298 TRCM_a084_CH_StatusC "TRCM ECU: a084 CH status c";
CM_ SG_ 1298 TRCM_a085_PARTY_buttonStatus "TRCM ECU: a085 PARTY button status";
CM_ SG_ 1298 TRCM_a086_VEH_LVBMS_statusHigh "TRCM ECU: a086 VEH LVBMS status high";
CM_ SG_ 1298 TRCM_a086_VEH_LVBMS_statusLow "TRCM ECU: a086 VEH LVBMS status low";
CM_ SG_ 1298 TRCM_a086_VEH_status "TRCM ECU: a086 VEH status";
CM_ SG_ 1298 TRCM_a086_VEH_12VBatteryStatus "TRCM ECU: a086 VEH 12 v battery status";
CM_ SG_ 1298 TRCM_a086_VEH_LVPowerState "TRCM ECU: a086 VEH LV power state";
CM_ SG_ 1298 TRCM_a086_VEH_lightStatus "TRCM ECU: a086 VEH light status";
CM_ SG_ 1298 TRCM_a086_VEH_systemStatus "TRCM ECU: a086 VEH system status";
CM_ SG_ 1298 TRCM_a086_VEH_thermalStatus "TRCM ECU: a086 VEH thermal status";
CM_ SG_ 1298 TRCM_a086_VEH_vehNm "TRCM ECU: a086 VEH veh nm";
CM_ SG_ 1298 TRCM_a087_VEH_temperature "TRCM ECU: a087 VEH temperature";
CM_ SG_ 1298 TRCM_a087_VEH_thermalControl "TRCM ECU: a087 VEH thermal control";
CM_ SG_ 1298 TRCM_a087_VEH_torque "TRCM ECU: a087 VEH torque";
CM_ SG_ 1298 TRCM_a087_VEH_status "TRCM ECU: a087 VEH status";
CM_ SG_ 1298 TRCM_a087_PARTY_torque "TRCM ECU: a087 PARTY torque";
CM_ SG_ 1298 TRCM_a087_PARTY_status "TRCM ECU: a087 PARTY status";
CM_ SG_ 1298 TRCM_a087_PARTY_temperature "TRCM ECU: a087 PARTY temperature";
CM_ SG_ 1298 TRCM_a087_PARTY_thermalControl "TRCM ECU: a087 PARTY thermal control";
CM_ SG_ 1298 TRCM_a088_VEH_temperature "TRCM ECU: a088 VEH temperature";
CM_ SG_ 1298 TRCM_a088_VEH_thermalControl "TRCM ECU: a088 VEH thermal control";
CM_ SG_ 1298 TRCM_a088_VEH_torque "TRCM ECU: a088 VEH torque";
CM_ SG_ 1298 TRCM_a088_VEH_status "TRCM ECU: a088 VEH status";
CM_ SG_ 1298 TRCM_a088_PARTY_torque "TRCM ECU: a088 PARTY torque";
CM_ SG_ 1298 TRCM_a088_PARTY_status "TRCM ECU: a088 PARTY status";
CM_ SG_ 1298 TRCM_a088_PARTY_temperature "TRCM ECU: a088 PARTY temperature";
CM_ SG_ 1298 TRCM_a088_PARTY_thermalControl "TRCM ECU: a088 PARTY thermal control";
CM_ SG_ 1298 TRCM_a089_PARTY_party1 "TRCM ECU: a089 PARTY party1";
CM_ SG_ 1298 TRCM_a089_PARTY_status "TRCM ECU: a089 PARTY status";
CM_ SG_ 1298 TRCM_a089_VEH_status "TRCM ECU: a089 VEH status";
CM_ SG_ 1298 TRCM_a089_BDY_party1 "TRCM ECU: a089 BDY party1";
CM_ SG_ 1298 TRCM_a089_BDY_status "TRCM ECU: a089 BDY status";
CM_ SG_ 1298 TRCM_a089_CH_status "TRCM ECU: a089 CH status";
CM_ SG_ 1298 TRCM_a089_CH_party1 "TRCM ECU: a089 CH party1";
CM_ SG_ 1298 TRCM_a089_CH_party3 "TRCM ECU: a089 CH party3";
CM_ SG_ 1298 TRCM_a089_VEH_party1 "TRCM ECU: a089 VEH party1";
CM_ SG_ 1298 TRCM_a089_VEH_party3 "TRCM ECU: a089 VEH party3";
CM_ SG_ 1298 TRCM_a091_VEH_faultsAndExtras "TRCM ECU: a091 VEH faults and extras";
CM_ SG_ 1298 TRCM_a091_VEH_info "TRCM ECU: a091 VEH info";
CM_ SG_ 1298 TRCM_a091_VEH_state "TRCM ECU: a091 VEH state";
CM_ SG_ 1298 TRCM_a092_VEH_restraintStatus "TRCM ECU: a092 VEH restraint status";
CM_ SG_ 1298 TRCM_a092_VEH_switchStatus "TRCM ECU: a092 VEH switch status";
CM_ SG_ 1298 TRCM_a092_VEH_seatStatus2 "TRCM ECU: a092 VEH seat status2";
CM_ SG_ 1298 TRCM_a092_VEH_vehNm "TRCM ECU: a092 VEH veh nm";
CM_ SG_ 1298 TRCM_a093_VEH_restraintStatus "TRCM ECU: a093 VEH restraint status";
CM_ SG_ 1298 TRCM_a093_VEH_switchStatus "TRCM ECU: a093 VEH switch status";
CM_ SG_ 1298 TRCM_a093_VEH_seatStatus2 "TRCM ECU: a093 VEH seat status2";
CM_ SG_ 1298 TRCM_a093_VEH_vehNm "TRCM ECU: a093 VEH veh nm";
CM_ SG_ 1298 TRCM_a094_VEH_sysStatus "TRCM ECU: a094 VEH sys status";
CM_ SG_ 1298 TRCM_a094_PARTY_sysStatus "TRCM ECU: a094 PARTY sys status";
CM_ SG_ 1298 TRCM_a095_PT_ptNm "TRCM ECU: a095 PT pt nm";
CM_ SG_ 1298 TRCM_a095_PT_status "TRCM ECU: a095 PT status";
CM_ SG_ 1298 TRCM_a096_VEH_status "TRCM ECU: a096 VEH status";
CM_ SG_ 1298 TRCM_a096_CH_status "TRCM ECU: a096 CH status";
CM_ SG_ 1298 TRCM_a098_CH_torque "TRCM ECU: a098 CH torque";
CM_ SG_ 1298 TRCM_a098_VEH_hvStatus "TRCM ECU: a098 VEH hv status";
CM_ SG_ 1298 TRCM_a098_VEH_status "TRCM ECU: a098 VEH status";
CM_ SG_ 1298 TRCM_a098_VEH_thermalControl "TRCM ECU: a098 VEH thermal control";
CM_ SG_ 1298 TRCM_a098_VEH_temperature "TRCM ECU: a098 VEH temperature";
CM_ SG_ 1298 TRCM_a098_VEH_torque "TRCM ECU: a098 VEH torque";
CM_ SG_ 1298 TRCM_a098_PARTY_status "TRCM ECU: a098 PARTY status";
CM_ SG_ 1298 TRCM_a098_PARTY_temperature "TRCM ECU: a098 PARTY temperature";
CM_ SG_ 1298 TRCM_a098_PARTY_thermalControl "TRCM ECU: a098 PARTY thermal control";
CM_ SG_ 1298 TRCM_a098_PARTY_torque "TRCM ECU: a098 PARTY torque";
CM_ SG_ 1298 TRCM_a098_PT_thermalControl "TRCM ECU: a098 PT thermal control";
CM_ SG_ 1298 TRCM_a098_PT_temperature "TRCM ECU: a098 PT temperature";
CM_ SG_ 1298 TRCM_a099_VEH_oocStatus "TRCM ECU: a099 VEH ooc status";
CM_ SG_ 1298 TRCM_a100_VEH "TRCM ECU: a100 VEH";
CM_ SG_ 1298 TRCM_a100_PARTY "TRCM ECU: a100 PARTY";
CM_ SG_ 1298 TRCM_a100_PT "TRCM ECU: a100 PT";
CM_ SG_ 1298 TRCM_a100_CH "TRCM ECU: a100 CH";
CM_ SG_ 1298 TRCM_a100_OBD "TRCM ECU: a100 OBD";
CM_ SG_ 1298 TRCM_a101_VEH_state "TRCM ECU: a101 VEH state";
CM_ SG_ 1298 TRCM_a101_PARTY_locState "TRCM ECU: a101 PARTY loc state";
CM_ SG_ 1298 TRCM_a101_LIPC_externalWatchdogH "TRCM ECU: a101 LIPC external watchdog heart beat";
CM_ SG_ 1298 TRCM_a101_VEH_locState "TRCM ECU: a101 VEH loc state";
CM_ SG_ 1298 TRCM_a101_BDY_locState "TRCM ECU: a101 BDY loc state";
CM_ SG_ 1298 TRCM_a102_VEH_faultsAndExtras "TRCM ECU: a102 VEH faults and extras";
CM_ SG_ 1298 TRCM_a102_VEH_feedbackStatus "TRCM ECU: a102 VEH feedback status";
CM_ SG_ 1298 TRCM_a102_VEH_sensorStatus "TRCM ECU: a102 VEH sensor status";
CM_ SG_ 1298 TRCM_a102_VEH_rods "TRCM ECU: a102 VEH rods";
CM_ SG_ 1298 TRCM_a103_VEH_hvsNm "TRCM ECU: a103 VEH hvs nm";
CM_ SG_ 1298 TRCM_a103_VEH_vehNm "TRCM ECU: a103 VEH veh nm";
CM_ SG_ 1298 TRCM_a103_VEH_status "TRCM ECU: a103 VEH status";
CM_ SG_ 1298 TRCM_a103_PT_ptNm "TRCM ECU: a103 PT pt nm";
CM_ SG_ 1298 TRCM_a103_PT_status "TRCM ECU: a103 PT status";
CM_ SG_ 1298 TRCM_a103_VEH_evseStatus "TRCM ECU: a103 VEH evse status";
CM_ SG_ 1298 TRCM_a105_VEH_states "TRCM ECU: a105 VEH states";
CM_ SG_ 1298 TRCM_a105_VEH_chNm "TRCM ECU: a105 VEH ch nm";
CM_ SG_ 1298 TRCM_a105_VEH_dampingStates "TRCM ECU: a105 VEH damping states";
CM_ SG_ 1298 TRCM_a106_VEH_dcdcStatus "TRCM ECU: a106 VEH dcdc status";
CM_ SG_ 1298 TRCM_a106_VEH_thermalControl "TRCM ECU: a106 VEH thermal control";
CM_ SG_ 1298 TRCM_a106_VEH_thermalInterface "TRCM ECU: a106 VEH thermal interface";
CM_ SG_ 1298 TRCM_a106_VEH_dcdcRailStatus "TRCM ECU: a106 VEH dcdc rail status";
CM_ SG_ 1298 TRCM_a106_CH_dcdcRailStatus "TRCM ECU: a106 CH dcdc rail status";
CM_ SG_ 1298 TRCM_a106_CH_alertMatrix "TRCM ECU: a106 CH alert matrix";
CM_ SG_ 1298 TRCM_a107_VEH_hvsNm "TRCM ECU: a107 VEH hvs nm";
CM_ SG_ 1298 TRCM_a107_VEH_vehNm "TRCM ECU: a107 VEH veh nm";
CM_ SG_ 1298 TRCM_a107_VEH_status "TRCM ECU: a107 VEH status";
CM_ SG_ 1298 TRCM_a107_VEH_thermalStatus "TRCM ECU: a107 VEH thermal status";
CM_ SG_ 1298 TRCM_a107_VEH_thermalStatus2 "TRCM ECU: a107 VEH thermal status2";
CM_ SG_ 1298 TRCM_a107_VEH_bmbMinMax "TRCM ECU: a107 VEH bmb min max";
CM_ SG_ 1298 TRCM_a107_VEH_powerAvailable "TRCM ECU: a107 VEH power available";
CM_ SG_ 1298 TRCM_a107_PT_ptNm "TRCM ECU: a107 PT pt nm";
CM_ SG_ 1298 TRCM_a107_PT_status "TRCM ECU: a107 PT status";
CM_ SG_ 1298 TRCM_a107_PT_thermalStatus "TRCM ECU: a107 PT thermal status";
CM_ SG_ 1298 TRCM_a107_PT_socStatus "TRCM ECU: a107 PT soc status";
CM_ SG_ 1298 TRCM_a107_VEH_socStatus "TRCM ECU: a107 VEH soc status";
CM_ SG_ 1298 TRCM_a107_VEH_packConfig "TRCM ECU: a107 VEH pack config";
CM_ SG_ 1298 TRCM_a107_VEH_energyStatus "TRCM ECU: a107 VEH energy status";
CM_ SG_ 1298 TRCM_a107_VEH_chargeInfo "TRCM ECU: a107 VEH charge info";
CM_ SG_ 1298 TRCM_a108_VEH_hvStatus "TRCM ECU: a108 VEH hv status";
CM_ SG_ 1298 TRCM_a108_VEH_temperature "TRCM ECU: a108 VEH temperature";
CM_ SG_ 1298 TRCM_a108_VEH_thermalControl "TRCM ECU: a108 VEH thermal control";
CM_ SG_ 1298 TRCM_a108_VEH_torque "TRCM ECU: a108 VEH torque";
CM_ SG_ 1298 TRCM_a108_VEH_status "TRCM ECU: a108 VEH status";
CM_ SG_ 1298 TRCM_a108_PARTY_torque "TRCM ECU: a108 PARTY torque";
CM_ SG_ 1298 TRCM_a108_PARTY_status "TRCM ECU: a108 PARTY status";
CM_ SG_ 1298 TRCM_a108_PARTY_temperature "TRCM ECU: a108 PARTY temperature";
CM_ SG_ 1298 TRCM_a108_PARTY_thermalControl "TRCM ECU: a108 PARTY thermal control";
CM_ SG_ 1298 TRCM_a108_PT_temperature "TRCM ECU: a108 PT temperature";
CM_ SG_ 1298 TRCM_a108_PT_thermalControl "TRCM ECU: a108 PT thermal control";
CM_ SG_ 1298 TRCM_a109_PARTY_status "TRCM ECU: a109 PARTY status";
CM_ SG_ 1298 TRCM_a109_PARTY_inertial2 "TRCM ECU: a109 PARTY inertial2";
CM_ SG_ 1298 TRCM_a109_PARTY_nearDeploy "TRCM ECU: a109 PARTY near deploy";
CM_ SG_ 1298 TRCM_a109_PARTY_collision "TRCM ECU: a109 PARTY collision";
CM_ SG_ 1298 TRCM_a109_VEH_status "TRCM ECU: a109 VEH status";
CM_ SG_ 1298 TRCM_a109_VEH_imuOffsets "TRCM ECU: a109 VEH imu offsets";
CM_ SG_ 1298 TRCM_a109_PARTY_inertial1 "TRCM ECU: a109 PARTY inertial1";
CM_ SG_ 1298 TRCM_a109_BDY_imuOffsets "TRCM ECU: a109 BDY imu offsets";
CM_ SG_ 1298 TRCM_a109_BDY_inertial1 "TRCM ECU: a109 BDY inertial1";
CM_ SG_ 1298 TRCM_a109_BDY_inertial2 "TRCM ECU: a109 BDY inertial2";
CM_ SG_ 1298 TRCM_a109_BDY_status "TRCM ECU: a109 BDY status";
CM_ SG_ 1298 TRCM_a109_VEH_inertial1 "TRCM ECU: a109 VEH inertial1";
CM_ SG_ 1298 TRCM_a109_VEH_inertial2 "TRCM ECU: a109 VEH inertial2";
CM_ SG_ 1298 TRCM_a109_CH_inertial1 "TRCM ECU: a109 CH inertial1";
CM_ SG_ 1298 TRCM_a109_CH_inertial2 "TRCM ECU: a109 CH inertial2";
CM_ SG_ 1298 TRCM_a109_CH_status "TRCM ECU: a109 CH status";
CM_ SG_ 1298 TRCM_a110_VEH_carState "TRCM ECU: a110 VEH car state";
CM_ SG_ 1298 TRCM_a110_VEH_carConfig "TRCM ECU: a110 VEH car config";
CM_ SG_ 1298 TRCM_a110_VEH_time "TRCM ECU: a110 VEH time";
CM_ SG_ 1298 TRCM_a110_VEH_updateStatus "TRCM ECU: a110 VEH update status";
CM_ SG_ 1298 TRCM_a110_VEH_vehNm "TRCM ECU: a110 VEH veh nm";
CM_ SG_ 1298 TRCM_a110_VEH_mismatchFault "TRCM ECU: a110 VEH mismatch fault";
CM_ SG_ 1298 TRCM_a110_VEH_vin "TRCM ECU: a110 VEH vin";
CM_ SG_ 1298 TRCM_a110_VEH_bmpDebug "TRCM ECU: a110 VEH bmp debug";
CM_ SG_ 1298 TRCM_a110_VEH_gearControl "TRCM ECU: a110 VEH gear control";
CM_ SG_ 1298 TRCM_a110_VEH_canLogAvailability "TRCM ECU: a110 VEH can log availability";
CM_ SG_ 1298 TRCM_a110_CH_airbagCutoffStatus "TRCM ECU: a110 CH airbag cutoff status";
CM_ SG_ 1298 TRCM_a110_CH_carConfig "TRCM ECU: a110 CH car config";
CM_ SG_ 1298 TRCM_a110_CH_carState "TRCM ECU: a110 CH car state";
CM_ SG_ 1298 TRCM_a110_CH_vin "TRCM ECU: a110 CH vin";
CM_ SG_ 1298 TRCM_a110_CH_chNm "TRCM ECU: a110 CH ch nm";
CM_ SG_ 1298 TRCM_a110_CH_epochTimeGtw "TRCM ECU: a110 CH epoch time gtw";
CM_ SG_ 1298 TRCM_a111_VEH_internalStatus "TRCM ECU: a111 VEH internal status";
CM_ SG_ 1298 TRCM_a111_VEH_status "TRCM ECU: a111 VEH status";
CM_ SG_ 1298 TRCM_a111_VEH_vehNm "TRCM ECU: a111 VEH veh nm";
CM_ SG_ 1298 TRCM_a111_RIPC_LVPowerState "TRCM ECU: a111 RIPC LV power state";
CM_ SG_ 1298 TRCM_a111_RIPC_epbPrivateState "TRCM ECU: a111 RIPC epb private state";
CM_ SG_ 1298 TRCM_a111_RIPC_railStatus "TRCM ECU: a111 RIPC rail status";
CM_ SG_ 1298 TRCM_a111_RIPC_remoteADC "TRCM ECU: a111 RIPC remote ADC";
CM_ SG_ 1298 TRCM_a111_RIPC_switchStatus "TRCM ECU: a111 RIPC switch status";
CM_ SG_ 1298 TRCM_a111_VEH_LVPowerState "TRCM ECU: a111 VEH LV power state";
CM_ SG_ 1298 TRCM_a111_VEH_seatStatus "TRCM ECU: a111 VEH seat status";
CM_ SG_ 1298 TRCM_a111_PARTY_status "TRCM ECU: a111 PARTY status";
CM_ SG_ 1298 TRCM_a111_CH_status "TRCM ECU: a111 CH status";
CM_ SG_ 1298 TRCM_a112_VEH_internalStatus "TRCM ECU: a112 VEH internal status";
CM_ SG_ 1298 TRCM_a112_VEH_status "TRCM ECU: a112 VEH status";
CM_ SG_ 1298 TRCM_a112_VEH_vehNm "TRCM ECU: a112 VEH veh nm";
CM_ SG_ 1298 TRCM_a112_LIPC_LVPowerState "TRCM ECU: a112 LIPC LV power state";
CM_ SG_ 1298 TRCM_a112_LIPC_epbPrivateState "TRCM ECU: a112 LIPC epb private state";
CM_ SG_ 1298 TRCM_a112_LIPC_railStatus "TRCM ECU: a112 LIPC rail status";
CM_ SG_ 1298 TRCM_a112_LIPC_remoteADC "TRCM ECU: a112 LIPC remote ADC";
CM_ SG_ 1298 TRCM_a112_LIPC_switchStatus "TRCM ECU: a112 LIPC switch status";
CM_ SG_ 1298 TRCM_a112_VEH_LVPowerState "TRCM ECU: a112 VEH LV power state";
CM_ SG_ 1298 TRCM_a112_PARTY_status "TRCM ECU: a112 PARTY status";
CM_ SG_ 1298 TRCM_a112_CH_status "TRCM ECU: a112 CH status";
CM_ SG_ 1298 TRCM_a114_PARTY_status "TRCM ECU: a114 PARTY status";
CM_ SG_ 1298 TRCM_a114_PARTY_wheelSpeeds "TRCM ECU: a114 PARTY wheel speeds";
CM_ SG_ 1298 TRCM_a114_VEH_wheelSpeeds "TRCM ECU: a114 VEH wheel speeds";
CM_ SG_ 1298 TRCM_a114_CH_wheelSpeeds "TRCM ECU: a114 CH wheel speeds";
CM_ SG_ 1298 TRCM_a114_PARTY_party3 "TRCM ECU: a114 PARTY party3";
CM_ SG_ 1298 TRCM_a114_VEH_party3 "TRCM ECU: a114 VEH party3";
CM_ SG_ 1298 TRCM_a114_VEH_status "TRCM ECU: a114 VEH status";
CM_ SG_ 1298 TRCM_a114_PARTY_wheelRotation "TRCM ECU: a114 PARTY wheel rotation";
CM_ SG_ 1298 TRCM_a114_CH_wheelRotation "TRCM ECU: a114 CH wheel rotation";
CM_ SG_ 1298 TRCM_a114_VEH_wheelRotation "TRCM ECU: a114 VEH wheel rotation";
CM_ SG_ 1298 TRCM_a114_PARTY_brakeTorque "TRCM ECU: a114 PARTY brake torque";
CM_ SG_ 1298 TRCM_a114_PARTY_offsets "TRCM ECU: a114 PARTY offsets";
CM_ SG_ 1298 TRCM_a114_BDY_offsets "TRCM ECU: a114 BDY offsets";
CM_ SG_ 1298 TRCM_a114_BDY_party3 "TRCM ECU: a114 BDY party3";
CM_ SG_ 1298 TRCM_a114_BDY_status "TRCM ECU: a114 BDY status";
CM_ SG_ 1298 TRCM_a114_BDY_wheelRotation "TRCM ECU: a114 BDY wheel rotation";
CM_ SG_ 1298 TRCM_a114_BDY_wheelSpeeds "TRCM ECU: a114 BDY wheel speeds";
CM_ SG_ 1298 TRCM_a114_CH_party1 "TRCM ECU: a114 CH party1";
CM_ SG_ 1298 TRCM_a114_CH_party3 "TRCM ECU: a114 CH party3";
CM_ SG_ 1298 TRCM_a114_CH_status "TRCM ECU: a114 CH status";
CM_ SG_ 1298 TRCM_a115_VEH_vehNm "TRCM ECU: a115 VEH veh nm";
CM_ SG_ 1298 TRCM_a115_VEH_authentication "TRCM ECU: a115 VEH authentication";
CM_ SG_ 1298 TRCM_a115_VEH_BLEResetRequest "TRCM ECU: a115 VEH BLE reset request";
CM_ SG_ 1298 TRCM_a115_VEH_requests "TRCM ECU: a115 VEH requests";
CM_ SG_ 1298 TRCM_a115_VEH_requests2 "TRCM ECU: a115 VEH requests2";
CM_ SG_ 1298 TRCM_a115_REM_authentication "TRCM ECU: a115 REM authentication";
CM_ SG_ 1298 TRCM_a115_UI_corianderVehicleCon "TRCM ECU: a115 UI coriander vehicle control";
CM_ SG_ 1298 TRCM_a115_CH_TPMSDisplay "TRCM ECU: a115 CH TPMS display";
CM_ SG_ 1298 TRCM_a116_PARTY_epbmStatus "TRCM ECU: a116 PARTY epbm status";
CM_ SG_ 1298 TRCM_a116_VEH_vehNm "TRCM ECU: a116 VEH veh nm";
CM_ SG_ 1298 TRCM_a116_VEH_hvacRequest "TRCM ECU: a116 VEH hvac request";
CM_ SG_ 1298 TRCM_a116_VEH_hvacStatus "TRCM ECU: a116 VEH hvac status";
CM_ SG_ 1298 TRCM_a116_VEH_LVPowerState "TRCM ECU: a116 VEH LV power state";
CM_ SG_ 1298 TRCM_a116_VEH_lightStatus "TRCM ECU: a116 VEH light status";
CM_ SG_ 1298 TRCM_a116_VEH_seatStatus "TRCM ECU: a116 VEH seat status";
CM_ SG_ 1298 TRCM_a116_VEH_thsStatus "TRCM ECU: a116 VEH ths status";
CM_ SG_ 1298 TRCM_a116_VEH_doorStatus "TRCM ECU: a116 VEH door status";
CM_ SG_ 1298 TRCM_a116_VEH_seatHeatStatus "TRCM ECU: a116 VEH seat heat status";
CM_ SG_ 1298 TRCM_a116_VEH_restraintStatus "TRCM ECU: a116 VEH restraint status";
CM_ SG_ 1298 TRCM_a116_VEH_switchStatus "TRCM ECU: a116 VEH switch status";
CM_ SG_ 1298 TRCM_a116_VEH_logging1Hz "TRCM ECU: a116 VEH logging1 hz";
CM_ SG_ 1298 TRCM_a116_VEH_seatStatus2 "TRCM ECU: a116 VEH seat status2";
CM_ SG_ 1298 TRCM_a116_VEH_status "TRCM ECU: a116 VEH status";
CM_ SG_ 1298 TRCM_a116_VEH_thermalCommand "TRCM ECU: a116 VEH thermal command";
CM_ SG_ 1298 TRCM_a116_VEH_windowStatus "TRCM ECU: a116 VEH window status";
CM_ SG_ 1298 TRCM_a116_PARTY_restraintStatus "TRCM ECU: a116 PARTY restraint status";
CM_ SG_ 1298 TRCM_a116_PARTY_doorStatus "TRCM ECU: a116 PARTY door status";
CM_ SG_ 1298 TRCM_a116_BDY_epbmStatus "TRCM ECU: a116 BDY epbm status";
CM_ SG_ 1298 TRCM_a116_BDY_restraintStatus "TRCM ECU: a116 BDY restraint status";
CM_ SG_ 1298 TRCM_a117_BDY_epbmStatus "TRCM ECU: a117 BDY epbm status";
CM_ SG_ 1298 TRCM_a117_BDY_restraintStatus "TRCM ECU: a117 BDY restraint status";
CM_ SG_ 1298 TRCM_a117_VEH_prndStatus "TRCM ECU: a117 VEH prnd status";
CM_ SG_ 1298 TRCM_a117_PARTY_epbmStatus "TRCM ECU: a117 PARTY epbm status";
CM_ SG_ 1298 TRCM_a117_VEH_vehNm "TRCM ECU: a117 VEH veh nm";
CM_ SG_ 1298 TRCM_a117_VEH_hvacBlowerFdb "TRCM ECU: a117 VEH hvac blower fdb";
CM_ SG_ 1298 TRCM_a117_VEH_LVPowerState "TRCM ECU: a117 VEH LV power state";
CM_ SG_ 1298 TRCM_a117_VEH_restraintStatus "TRCM ECU: a117 VEH restraint status";
CM_ SG_ 1298 TRCM_a117_VEH_lightStatus "TRCM ECU: a117 VEH light status";
CM_ SG_ 1298 TRCM_a117_VEH_seatStatus "TRCM ECU: a117 VEH seat status";
CM_ SG_ 1298 TRCM_a117_BDY_falconSwitchStatus "TRCM ECU: a117 BDY falcon switch status";
CM_ SG_ 1298 TRCM_a117_VEH_doorStatus "TRCM ECU: a117 VEH door status";
CM_ SG_ 1298 TRCM_a117_VEH_doorStatus2 "TRCM ECU: a117 VEH door status2";
CM_ SG_ 1298 TRCM_a117_VEH_windowStatus "TRCM ECU: a117 VEH window status";
CM_ SG_ 1298 TRCM_a117_VEH_switchStatus "TRCM ECU: a117 VEH switch status";
CM_ SG_ 1298 TRCM_a117_VEH_intrusionSensorSta "TRCM ECU: a117 VEH intrusion sensor status";
CM_ SG_ 1298 TRCM_a117_VEH_liftgateStatus "TRCM ECU: a117 VEH liftgate status";
CM_ SG_ 1298 TRCM_a117_VEH_seatStatus2 "TRCM ECU: a117 VEH seat status2";
CM_ SG_ 1298 TRCM_a117_PARTY_restraintStatus "TRCM ECU: a117 PARTY restraint status";
CM_ SG_ 1298 TRCM_a117_VEH_thermalStatus "TRCM ECU: a117 VEH thermal status";
CM_ SG_ 1298 TRCM_a117_PARTY_doorStatus "TRCM ECU: a117 PARTY door status";
CM_ SG_ 1298 TRCM_a117_VEH_status "TRCM ECU: a117 VEH status";
CM_ SG_ 1298 TRCM_a117_PARTY_prndStatus "TRCM ECU: a117 PARTY prnd status";
CM_ SG_ 1298 TRCM_a118_VEH_vehNm "TRCM ECU: a118 VEH veh nm";
CM_ SG_ 1298 TRCM_a118_VEH_lighting "TRCM ECU: a118 VEH lighting";
CM_ SG_ 1298 TRCM_a118_VEH_sensors "TRCM ECU: a118 VEH sensors";
CM_ SG_ 1298 TRCM_a118_VEH_status "TRCM ECU: a118 VEH status";
CM_ SG_ 1298 TRCM_a118_VEH_okToUseHighPwr "TRCM ECU: a118 VEH ok to use high pwr";
CM_ SG_ 1298 TRCM_a118_VEH_LVPowerState "TRCM ECU: a118 VEH LV power state";
CM_ SG_ 1298 TRCM_a118_VEH_coolant "TRCM ECU: a118 VEH coolant";
CM_ SG_ 1298 TRCM_a118_VEH_vehicleStatus "TRCM ECU: a118 VEH vehicle status";
CM_ SG_ 1298 TRCM_a118_VEH_12VBatteryStatus "TRCM ECU: a118 VEH 12 v battery status";
CM_ SG_ 1298 TRCM_a118_VEH_systemStatus "TRCM ECU: a118 VEH system status";
CM_ SG_ 1298 TRCM_a118_PARTY_LVPowerState "TRCM ECU: a118 PARTY LV power state";
CM_ SG_ 1298 TRCM_a118_PARTY_outputPowerStatu "TRCM ECU: a118 PARTY output power status";
CM_ SG_ 1298 TRCM_a118_PARTY_vehicleTime "TRCM ECU: a118 PARTY vehicle time";
CM_ SG_ 1298 TRCM_a118_VEH_thermalCommand "TRCM ECU: a118 VEH thermal command";
CM_ SG_ 1298 TRCM_a118_CH_LVPowerState "TRCM ECU: a118 CH LV power state";
CM_ SG_ 1298 TRCM_a118_PARTY_sensors "TRCM ECU: a118 PARTY sensors";
CM_ SG_ 1298 TRCM_a118_CH_sensors "TRCM ECU: a118 CH sensors";
CM_ SG_ 1298 TRCM_a118_VEH_interNodeResistanc "TRCM ECU: a118 VEH inter node resistance";
CM_ SG_ 1298 TRCM_a118_CH_lighting "TRCM ECU: a118 CH lighting";
CM_ SG_ 1298 TRCM_a118_VEH_lightStatus "TRCM ECU: a118 VEH light status";
CM_ SG_ 1298 TRCM_a118_PARTY_vehNm "TRCM ECU: a118 PARTY veh nm";
CM_ SG_ 1298 TRCM_a118_CH_12VBatteryStatus "TRCM ECU: a118 CH 12 v battery status";
CM_ SG_ 1298 TRCM_a118_CH_LVBMS_statusHigh "TRCM ECU: a118 CH LVBMS status high";
CM_ SG_ 1298 TRCM_a118_CH_alertMatrix "TRCM ECU: a118 CH alert matrix";
CM_ SG_ 1298 TRCM_a118_BDY_outputPowerStatus "TRCM ECU: a118 BDY output power status";
CM_ SG_ 1298 TRCM_a118_BDY_vehicleTime "TRCM ECU: a118 BDY vehicle time";
CM_ SG_ 1298 TRCM_a118_PARTY_AP_vehicleState1 "TRCM ECU: a118 PARTY AP vehicle state1 hz muxed";
CM_ SG_ 1298 TRCM_a118_BDY_AP_vehicleState1Hz "TRCM ECU: a118 BDY AP vehicle state1 hz muxed";
CM_ SG_ 1298 TRCM_a119_VEH_steerAngle "TRCM ECU: a119 VEH steer angle";
CM_ SG_ 1298 TRCM_a119_VEH_leftStalk "TRCM ECU: a119 VEH left stalk";
CM_ SG_ 1298 TRCM_a119_VEH_rightStalk "TRCM ECU: a119 VEH right stalk";
CM_ SG_ 1298 TRCM_a119_PARTY_rightStalk "TRCM ECU: a119 PARTY right stalk";
CM_ SG_ 1298 TRCM_a119_CH_steerAngle "TRCM ECU: a119 CH steer angle";
CM_ SG_ 1298 TRCM_a119_PARTY_steerAngle "TRCM ECU: a119 PARTY steer angle";
CM_ SG_ 1298 TRCM_a120_PARTY_chassisCntl "TRCM ECU: a120 PARTY chassis cntl";
CM_ SG_ 1298 TRCM_a120_VEH_systemStatus "TRCM ECU: a120 VEH system status";
CM_ SG_ 1298 TRCM_a120_CH_chassisCntl "TRCM ECU: a120 CH chassis cntl";
CM_ SG_ 1298 TRCM_a120_PARTY_systemStatus "TRCM ECU: a120 PARTY system status";
CM_ SG_ 1298 TRCM_a120_PARTY_torque "TRCM ECU: a120 PARTY torque";
CM_ SG_ 1298 TRCM_a120_VEH_torque "TRCM ECU: a120 VEH torque";
CM_ SG_ 1298 TRCM_a120_PARTY_locStatus "TRCM ECU: a120 PARTY loc status";
CM_ SG_ 1298 TRCM_a120_PARTY_speed "TRCM ECU: a120 PARTY speed";
CM_ SG_ 1298 TRCM_a120_VEH_speed "TRCM ECU: a120 VEH speed";
CM_ SG_ 1298 TRCM_a120_PARTY_status "TRCM ECU: a120 PARTY status";
CM_ SG_ 1298 TRCM_a120_PT_speed "TRCM ECU: a120 PT speed";
CM_ SG_ 1298 TRCM_a120_PT_systemStatus "TRCM ECU: a120 PT system status";
CM_ SG_ 1298 TRCM_a120_PARTY_vehicleEstimates "TRCM ECU: a120 PARTY vehicle estimates";
CM_ SG_ 1298 TRCM_a120_VEH_aggregatedAxleSpee "TRCM ECU: a120 VEH aggregated axle speed";
CM_ SG_ 1298 TRCM_a120_PARTY_aggregatedAxleSp "TRCM ECU: a120 PARTY aggregated axle speed";
CM_ SG_ 1298 TRCM_a120_VEH_systemPower "TRCM ECU: a120 VEH system power";
CM_ SG_ 1298 TRCM_a120_PT_systemPower "TRCM ECU: a120 PT system power";
CM_ SG_ 1298 TRCM_a120_PARTY_stalklessInterfa "TRCM ECU: a120 PARTY stalkless interfaces";
CM_ SG_ 1298 TRCM_a120_CH_speed "TRCM ECU: a120 CH speed";
CM_ SG_ 1298 TRCM_a120_VEH_estimatedBrakeTemp "TRCM ECU: a120 VEH estimated brake temp";
CM_ SG_ 1298 TRCM_a120_PARTY_prndControl "TRCM ECU: a120 PARTY prnd control";
CM_ SG_ 1298 TRCM_a120_PARTY_locStatus2 "TRCM ECU: a120 PARTY loc status2";
CM_ SG_ 1298 TRCM_a120_VEH_chassisCntl "TRCM ECU: a120 VEH chassis cntl";
CM_ SG_ 1298 TRCM_a120_VEH_locStatus "TRCM ECU: a120 VEH loc status";
CM_ SG_ 1298 TRCM_a120_VEH_locStatus2 "TRCM ECU: a120 VEH loc status2";
CM_ SG_ 1298 TRCM_a120_VEH_prndControl "TRCM ECU: a120 VEH prnd control";
CM_ SG_ 1298 TRCM_a120_VEH_vehicleEstimates "TRCM ECU: a120 VEH vehicle estimates";
CM_ BO_ 2030 "TRCM ECU message: alert matrix";
CM_ SG_ 2030 TRCM_matrixIndex "TRCM ECU: matrix index";
CM_ SG_ 2030 TRCM_a003_SWAssertion "TRCM ECU: a003 SW assertion";
CM_ SG_ 2030 TRCM_a005_CANTXError "TRCM ECU: a005 CANTX error";
CM_ SG_ 2030 TRCM_a006_CANTX_cyclicError "TRCM ECU: a006 CANTX cyclic error";
CM_ SG_ 2030 TRCM_a007_chassisChecksumError "TRCM ECU: a007 chassis checksum error";
CM_ SG_ 2030 TRCM_a008_chassisCounterError "TRCM ECU: a008 chassis counter error";
CM_ SG_ 2030 TRCM_a009_partyChecksumError "TRCM ECU: a009 party checksum error";
CM_ SG_ 2030 TRCM_a010_partyCounterError "TRCM ECU: a010 party counter error";
CM_ SG_ 2030 TRCM_a012_asm5TemperatureOutside "TRCM ECU: a012 asm5 temperature outside signal range";
CM_ SG_ 2030 TRCM_a013_AlertManagerFault "TRCM ECU: a013 alert manager fault";
CM_ SG_ 2030 TRCM_a014_asm3TemperatureOutside "TRCM ECU: a014 asm3 temperature outside signal range";
CM_ SG_ 2030 TRCM_a015_NVMMError "TRCM ECU: a015 NVMM error";
CM_ SG_ 2030 TRCM_a016_NVMMRecordError "TRCM ECU: a016 NVMM record error";
CM_ SG_ 2030 TRCM_a017_asm5TemperatureOutside "TRCM ECU: a017 asm5 temperature outside operating range";
CM_ SG_ 2030 TRCM_a018_asm3TemperatureOutside "TRCM ECU: a018 asm3 temperature outside operating range";
CM_ SG_ 2030 TRCM_a019_Task500usError "TRCM ECU: a019 task500us error";
CM_ SG_ 2030 TRCM_a020_asm3ComStatusError "TRCM ECU: a020 asm3 com status error";
CM_ SG_ 2030 TRCM_a021_TaskSchedulerError "TRCM ECU: a021 task scheduler error";
CM_ SG_ 2030 TRCM_a022_TaskInitError "TRCM ECU: a022 task init error";
CM_ SG_ 2030 TRCM_a023_asm3ArsStatusXError "TRCM ECU: a023 asm3 ars status x error";
CM_ SG_ 2030 TRCM_a024_asm3AccStatusError "TRCM ECU: a024 asm3 acc status error";
CM_ SG_ 2030 TRCM_a025_CHCANBusFaults "TRCM ECU: a025 CHCAN bus faults";
CM_ SG_ 2030 TRCM_a026_airbagAsicDiagnosticFa "TRCM ECU: a026 airbag asic diagnostic fault";
CM_ SG_ 2030 TRCM_a027_airbagAsicDeploymentDi "TRCM ECU: a027 airbag asic deployment diagnostic fault";
CM_ SG_ 2030 TRCM_a030_ECULogUploadRequest "TRCM ECU: a030 ECU log upload request";
CM_ SG_ 2030 TRCM_a031_UDSActive "TRCM ECU: a031 UDS active";
CM_ SG_ 2030 TRCM_a033_HercLogCreated "TRCM ECU: a033 herc log created";
CM_ SG_ 2030 TRCM_a034_apClipTrigger "TRCM ECU: a034 ap clip trigger";
CM_ SG_ 2030 TRCM_a035_hvDisconnectCommanded "TRCM ECU: a035 hv disconnect commanded";
CM_ SG_ 2030 TRCM_a041_HighCPULoad "TRCM ECU: a041 high CPU load";
CM_ SG_ 2030 TRCM_a042_HighStackUsage "TRCM ECU: a042 high stack usage";
CM_ SG_ 2030 TRCM_a043_Task1msError "TRCM ECU: a043 task1ms error";
CM_ SG_ 2030 TRCM_a044_Task10msError "TRCM ECU: a044 task10ms error";
CM_ SG_ 2030 TRCM_a045_Task100msError "TRCM ECU: a045 task100ms error";
CM_ SG_ 2030 TRCM_a046_Task1000msError "TRCM ECU: a046 task1000ms error";
CM_ SG_ 2030 TRCM_a057_HVP_MIA "TRCM ECU: a057 HVP MIA";
CM_ SG_ 2030 TRCM_a058_inputRHighSyncDebug "TRCM ECU: a058 input r high sync debug";
CM_ SG_ 2030 TRCM_a059_inputResistanceHigh "TRCM ECU: a059 input resistance high";
CM_ SG_ 2030 TRCM_a060_engineeringBuild "TRCM ECU: a060 engineering build";
CM_ SG_ 2030 TRCM_a061_XCPConnected "TRCM ECU: a061 XCP connected";
CM_ SG_ 2030 TRCM_a062_XCPWasConnected "TRCM ECU: a062 XCP was connected";
CM_ SG_ 2030 TRCM_a063_SwitchFault "TRCM ECU: a063 switch fault";
CM_ SG_ 2030 TRCM_a064_busSleepReqTimeout "TRCM ECU: a064 bus sleep req timeout";
CM_ SG_ 2030 TRCM_a065_vSafingFetUnderVoltage "TRCM ECU: a065 v safing fet under voltage";
CM_ SG_ 2030 TRCM_a066_vBusAUnderVoltage "TRCM ECU: a066 v bus a under voltage";
CM_ SG_ 2030 TRCM_a067_vBusBUnderVoltage "TRCM ECU: a067 v bus b under voltage";
CM_ SG_ 2030 TRCM_a068_vBusCUnderVoltage "TRCM ECU: a068 v bus c under voltage";
CM_ SG_ 2030 TRCM_a069_swAppBoot "TRCM ECU: a069 sw app boot";
CM_ SG_ 2030 TRCM_a070_asm3StatusError "TRCM ECU: a070 asm3 status error";
CM_ SG_ 2030 TRCM_a071_asm3DeviceFaulted "TRCM ECU: a071 asm3 device faulted";
CM_ SG_ 2030 TRCM_a072_ais2120StatusError "TRCM ECU: a072 ais2120 status error";
CM_ SG_ 2030 TRCM_a073_ais2120DeviceFaulted "TRCM ECU: a073 ais2120 device faulted";
CM_ SG_ 2030 TRCM_a074_ais2120SelfTestXPositi "TRCM ECU: a074 ais2120 self test x positive failed";
CM_ SG_ 2030 TRCM_a075_ais2120SelfTestXNegati "TRCM ECU: a075 ais2120 self test x negative failed";
CM_ SG_ 2030 TRCM_a076_ais2120SelfTestYPositi "TRCM ECU: a076 ais2120 self test y positive failed";
CM_ SG_ 2030 TRCM_a077_ais2120SelfTestYNegati "TRCM ECU: a077 ais2120 self test y negative failed";
CM_ SG_ 2030 TRCM_a081_autarkyActive "TRCM ECU: a081 autarky active";
CM_ SG_ 2030 TRCM_a082_VCRIGHT_IPC_MIA "TRCM ECU: a082 VCRIGHT IPC MIA";
CM_ SG_ 2030 TRCM_a083_VCLEFT_IPC_MIA "TRCM ECU: a083 VCLEFT IPC MIA";
CM_ SG_ 2030 TRCM_a084_TPMS_MIA "TRCM ECU: a084 TPMS MIA";
CM_ SG_ 2030 TRCM_a085_CCCM_MIA "TRCM ECU: a085 CCCM MIA";
CM_ SG_ 2030 TRCM_a086_VCBATT_MIA "TRCM ECU: a086 VCBATT MIA";
CM_ SG_ 2030 TRCM_a087_DIREL_MIA "TRCM ECU: a087 DIREL MIA";
CM_ SG_ 2030 TRCM_a088_DIRER_MIA "TRCM ECU: a088 DIRER MIA";
CM_ SG_ 2030 TRCM_a089_IBST_MIA "TRCM ECU: a089 IBST MIA";
CM_ SG_ 2030 TRCM_a090_APS_MIA "TRCM ECU: a090 APS MIA";
CM_ SG_ 2030 TRCM_a091_CMPD_MIA "TRCM ECU: a091 CMPD MIA";
CM_ SG_ 2030 TRCM_a092_VCSEATD_MIA "TRCM ECU: a092 VCSEATD MIA";
CM_ SG_ 2030 TRCM_a093_VCSEATP_MIA "TRCM ECU: a093 VCSEATP MIA";
CM_ SG_ 2030 TRCM_a094_EPAS3P_MIA "TRCM ECU: a094 EPAS3 p MIA";
CM_ SG_ 2030 TRCM_a095_CHG_MIA "TRCM ECU: a095 CHG MIA";
CM_ SG_ 2030 TRCM_a096_OCS1P_MIA "TRCM ECU: a096 OCS1 p MIA";
CM_ SG_ 2030 TRCM_a097_CMP_MIA "TRCM ECU: a097 CMP MIA";
CM_ SG_ 2030 TRCM_a098_DIR_MIA "TRCM ECU: a098 DIR MIA";
CM_ SG_ 2030 TRCM_a099_PARK_MIA "TRCM ECU: a099 PARK MIA";
CM_ SG_ 2030 TRCM_a100_CANbus_MIA "TRCM ECU: a100 CA nbus MIA";
CM_ SG_ 2030 TRCM_a101_PM_MIA "TRCM ECU: a101 PM MIA";
CM_ SG_ 2030 TRCM_a102_PTC_MIA "TRCM ECU: a102 PTC MIA";
CM_ SG_ 2030 TRCM_a103_CP_MIA "TRCM ECU: a103 CP MIA";
CM_ SG_ 2030 TRCM_a104_DAS_MIA "TRCM ECU: a104 DAS MIA";
CM_ SG_ 2030 TRCM_a105_TAS_MIA "TRCM ECU: a105 TAS MIA";
CM_ SG_ 2030 TRCM_a106_PCS_MIA "TRCM ECU: a106 PCS MIA";
CM_ SG_ 2030 TRCM_a107_BMS_MIA "TRCM ECU: a107 BMS MIA";
CM_ SG_ 2030 TRCM_a108_DIF_MIA "TRCM ECU: a108 DIF MIA";
CM_ SG_ 2030 TRCM_a109_RCM_MIA "TRCM ECU: a109 RCM MIA";
CM_ SG_ 2030 TRCM_a110_GTW_MIA "TRCM ECU: a110 GTW MIA";
CM_ SG_ 2030 TRCM_a111_EPBR_MIA "TRCM ECU: a111 EPBR MIA";
CM_ SG_ 2030 TRCM_a112_EPBL_MIA "TRCM ECU: a112 EPBL MIA";
CM_ SG_ 2030 TRCM_a113_UI_MIA "TRCM ECU: a113 UI MIA";
CM_ SG_ 2030 TRCM_a114_ESP_MIA "TRCM ECU: a114 ESP MIA";
CM_ SG_ 2030 TRCM_a115_VCSEC_MIA "TRCM ECU: a115 VCSEC MIA";
CM_ SG_ 2030 TRCM_a116_VCRIGHT_MIA "TRCM ECU: a116 VCRIGHT MIA";
CM_ SG_ 2030 TRCM_a117_VCLEFT_MIA "TRCM ECU: a117 VCLEFT MIA";
CM_ SG_ 2030 TRCM_a118_VCFRONT_MIA "TRCM ECU: a118 VCFRONT MIA";
CM_ SG_ 2030 TRCM_a119_SCCM_MIA "TRCM ECU: a119 SCCM MIA";
CM_ SG_ 2030 TRCM_a120_DI_DRIVE_MIA "TRCM ECU: a120 DI DRIVE MIA";
CM_ SG_ 2030 TRCM_a121_glacierInitialStatusFa "TRCM ECU: a121 glacier initial status failure";
CM_ SG_ 2030 TRCM_a122_glacierTraceabilityRea "TRCM ECU: a122 glacier traceability readout A0 A0 failure";
CM_ SG_ 2030 TRCM_a123_glacierTraceabilityRea "TRCM ECU: a123 glacier traceability readout B0 B0 failure";
CM_ SG_ 2030 TRCM_a124_glacierRegisterPattern "TRCM ECU: a124 glacier register pattern write failure";
CM_ SG_ 2030 TRCM_a125_glacierFixedPatternSel "TRCM ECU: a125 glacier fixed pattern self test failure";
CM_ SG_ 2030 TRCM_a126_glacierSelfTestEFailur "TRCM ECU: a126 glacier self test e failure";
CM_ SG_ 2030 TRCM_a127_glacierSelfTestFFailur "TRCM ECU: a127 glacier self test f failure";
CM_ SG_ 2030 TRCM_a128_glacierAnalogSelfTestF "TRCM ECU: a128 glacier analog self test failure";
CM_ SG_ 2030 TRCM_a129_glacierOscillatorVerif "TRCM ECU: a129 glacier oscillator verification failure";
CM_ SG_ 2030 TRCM_a130_glacierFinalStatusFail "TRCM ECU: a130 glacier final status failure";
CM_ SG_ 2030 TRCM_a131_glacierOffsetVerificat "TRCM ECU: a131 glacier offset verification failure";
CM_ SG_ 2030 TRCM_a132_glacierNormalOperation "TRCM ECU: a132 glacier normal operation failure";
CM_ SG_ 2030 TRCM_a133_glacierDeviceReset "TRCM ECU: a133 glacier device reset";
CM_ SG_ 2030 TRCM_a134_glacierDeviceFaulted "TRCM ECU: a134 glacier device faulted";
CM_ SG_ 2030 TRCM_a135_asm5StatusError "TRCM ECU: a135 asm5 status error";
CM_ SG_ 2030 TRCM_a136_asm5DeviceFaulted "TRCM ECU: a136 asm5 device faulted";
CM_ SG_ 2030 TRCM_a137_ext1AsicSnoopTestFaile "TRCM ECU: a137 ext1 asic snoop test failed";
CM_ SG_ 2030 TRCM_a138_ext2AsicSnoopTestFaile "TRCM ECU: a138 ext2 asic snoop test failed";
CM_ SG_ 2030 TRCM_a139_disarmed "TRCM ECU: a139 disarmed";
CM_ SG_ 2030 TRCM_a140_frontRightAccelInitFai "TRCM ECU: a140 front right accel init failure";
CM_ SG_ 2030 TRCM_a141_frontRightAccelShortTo "TRCM ECU: a141 front right accel short to ground";
CM_ SG_ 2030 TRCM_a142_frontRightAccelShortTo "TRCM ECU: a142 front right accel short to battery";
CM_ SG_ 2030 TRCM_a143_frontRightAccelConfigE "TRCM ECU: a143 front right accel config error";
CM_ SG_ 2030 TRCM_a144_frontRightAccelOpen "TRCM ECU: a144 front right accel open";
CM_ SG_ 2030 TRCM_a145_frontRightAccelCommErr "TRCM ECU: a145 front right accel comm error";
CM_ SG_ 2030 TRCM_a146_frontRightAccelSensorD "TRCM ECU: a146 front right accel sensor defect";
CM_ SG_ 2030 TRCM_a147_frontRightAccelSignalM "TRCM ECU: a147 front right accel signal monitor";
CM_ SG_ 2030 TRCM_a150_rightFrontDoorPressure "TRCM ECU: a150 right front door pressure init failure";
CM_ SG_ 2030 TRCM_a151_rightFrontDoorPressure "TRCM ECU: a151 right front door pressure short to ground";
CM_ SG_ 2030 TRCM_a152_rightFrontDoorPressure "TRCM ECU: a152 right front door pressure short to battery";
CM_ SG_ 2030 TRCM_a153_rightFrontDoorPressure "TRCM ECU: a153 right front door pressure config error";
CM_ SG_ 2030 TRCM_a154_rightFrontDoorPressure "TRCM ECU: a154 right front door pressure open";
CM_ SG_ 2030 TRCM_a155_rightFrontDoorPressure "TRCM ECU: a155 right front door pressure comm error";
CM_ SG_ 2030 TRCM_a156_rightFrontDoorPressure "TRCM ECU: a156 right front door pressure sensor defect";
CM_ SG_ 2030 TRCM_a157_rightFrontDoorPressure "TRCM ECU: a157 right front door pressure signal monitor";
CM_ SG_ 2030 TRCM_a160_frontLeftAccelInitFail "TRCM ECU: a160 front left accel init failure";
CM_ SG_ 2030 TRCM_a161_frontLeftAccelShortToG "TRCM ECU: a161 front left accel short to ground";
CM_ SG_ 2030 TRCM_a162_frontLeftAccelShortToB "TRCM ECU: a162 front left accel short to battery";
CM_ SG_ 2030 TRCM_a163_frontLeftAccelConfigEr "TRCM ECU: a163 front left accel config error";
CM_ SG_ 2030 TRCM_a164_frontLeftAccelOpen "TRCM ECU: a164 front left accel open";
CM_ SG_ 2030 TRCM_a165_frontLeftAccelCommErro "TRCM ECU: a165 front left accel comm error";
CM_ SG_ 2030 TRCM_a166_frontLeftAccelSensorDe "TRCM ECU: a166 front left accel sensor defect";
CM_ SG_ 2030 TRCM_a167_frontLeftAccelSignalMo "TRCM ECU: a167 front left accel signal monitor";
CM_ SG_ 2030 TRCM_a170_leftFrontDoorPressureI "TRCM ECU: a170 left front door pressure init failure";
CM_ SG_ 2030 TRCM_a171_leftFrontDoorPressureS "TRCM ECU: a171 left front door pressure short to ground";
CM_ SG_ 2030 TRCM_a172_leftFrontDoorPressureS "TRCM ECU: a172 left front door pressure short to battery";
CM_ SG_ 2030 TRCM_a173_leftFrontDoorPressureC "TRCM ECU: a173 left front door pressure config error";
CM_ SG_ 2030 TRCM_a174_leftFrontDoorPressureO "TRCM ECU: a174 left front door pressure open";
CM_ SG_ 2030 TRCM_a175_leftFrontDoorPressureC "TRCM ECU: a175 left front door pressure comm error";
CM_ SG_ 2030 TRCM_a176_leftFrontDoorPressureS "TRCM ECU: a176 left front door pressure sensor defect";
CM_ SG_ 2030 TRCM_a177_leftFrontDoorPressureS "TRCM ECU: a177 left front door pressure signal monitor";
CM_ SG_ 2030 TRCM_a180_rightBPillarAccelInitF "TRCM ECU: a180 right b pillar accel init failure";
CM_ SG_ 2030 TRCM_a181_rightBPillarAccelShort "TRCM ECU: a181 right b pillar accel short to ground";
CM_ SG_ 2030 TRCM_a182_rightBPillarAccelShort "TRCM ECU: a182 right b pillar accel short to battery";
CM_ SG_ 2030 TRCM_a183_rightBPillarAccelConfi "TRCM ECU: a183 right b pillar accel config error";
CM_ SG_ 2030 TRCM_a184_rightBPillarAccelOpen "TRCM ECU: a184 right b pillar accel open";
CM_ SG_ 2030 TRCM_a185_rightBPillarAccelCommE "TRCM ECU: a185 right b pillar accel comm error";
CM_ SG_ 2030 TRCM_a186_rightBPillarAccelSenso "TRCM ECU: a186 right b pillar accel sensor defect";
CM_ SG_ 2030 TRCM_a187_rightBPillarAccelSigna "TRCM ECU: a187 right b pillar accel signal monitor";
CM_ SG_ 2030 TRCM_a190_leftBPillarAccelInitFa "TRCM ECU: a190 left b pillar accel init failure";
CM_ SG_ 2030 TRCM_a191_leftBPillarAccelShortT "TRCM ECU: a191 left b pillar accel short to ground";
CM_ SG_ 2030 TRCM_a192_leftBPillarAccelShortT "TRCM ECU: a192 left b pillar accel short to battery";
CM_ SG_ 2030 TRCM_a193_leftBPillarAccelConfig "TRCM ECU: a193 left b pillar accel config error";
CM_ SG_ 2030 TRCM_a194_leftBPillarAccelOpen "TRCM ECU: a194 left b pillar accel open";
CM_ SG_ 2030 TRCM_a195_leftBPillarAccelCommEr "TRCM ECU: a195 left b pillar accel comm error";
CM_ SG_ 2030 TRCM_a196_leftBPillarAccelSensor "TRCM ECU: a196 left b pillar accel sensor defect";
CM_ SG_ 2030 TRCM_a197_leftBPillarAccelSignal "TRCM ECU: a197 left b pillar accel signal monitor";
CM_ SG_ 2030 TRCM_a200_frontCenterAccelInitFa "TRCM ECU: a200 front center accel init failure";
CM_ SG_ 2030 TRCM_a201_frontCenterAccelShortT "TRCM ECU: a201 front center accel short to ground";
CM_ SG_ 2030 TRCM_a202_frontCenterAccelShortT "TRCM ECU: a202 front center accel short to battery";
CM_ SG_ 2030 TRCM_a203_frontCenterAccelConfig "TRCM ECU: a203 front center accel config error";
CM_ SG_ 2030 TRCM_a204_frontCenterAccelOpen "TRCM ECU: a204 front center accel open";
CM_ SG_ 2030 TRCM_a205_frontCenterAccelCommEr "TRCM ECU: a205 front center accel comm error";
CM_ SG_ 2030 TRCM_a206_frontCenterAccelSensor "TRCM ECU: a206 front center accel sensor defect";
CM_ SG_ 2030 TRCM_a207_frontCenterAccelSignal "TRCM ECU: a207 front center accel signal monitor";
CM_ SG_ 2030 TRCM_a210_leftCPillarAccelInitFa "TRCM ECU: a210 left c pillar accel init failure";
CM_ SG_ 2030 TRCM_a211_leftCPillarAccelShortT "TRCM ECU: a211 left c pillar accel short to ground";
CM_ SG_ 2030 TRCM_a212_leftCPillarAccelShortT "TRCM ECU: a212 left c pillar accel short to battery";
CM_ SG_ 2030 TRCM_a213_leftCPillarAccelConfig "TRCM ECU: a213 left c pillar accel config error";
CM_ SG_ 2030 TRCM_a214_leftCPillarAccelOpen "TRCM ECU: a214 left c pillar accel open";
CM_ SG_ 2030 TRCM_a215_leftCPillarAccelCommEr "TRCM ECU: a215 left c pillar accel comm error";
CM_ SG_ 2030 TRCM_a216_leftCPillarAccelSensor "TRCM ECU: a216 left c pillar accel sensor defect";
CM_ SG_ 2030 TRCM_a217_leftCPillarAccelSignal "TRCM ECU: a217 left c pillar accel signal monitor";
CM_ SG_ 2030 TRCM_a220_rightCPillarAccelInitF "TRCM ECU: a220 right c pillar accel init failure";
CM_ SG_ 2030 TRCM_a221_rightCPillarAccelShort "TRCM ECU: a221 right c pillar accel short to ground";
CM_ SG_ 2030 TRCM_a222_rightCPillarAccelShort "TRCM ECU: a222 right c pillar accel short to battery";
CM_ SG_ 2030 TRCM_a223_rightCPillarAccelConfi "TRCM ECU: a223 right c pillar accel config error";
CM_ SG_ 2030 TRCM_a224_rightCPillarAccelOpen "TRCM ECU: a224 right c pillar accel open";
CM_ SG_ 2030 TRCM_a225_rightCPillarAccelCommE "TRCM ECU: a225 right c pillar accel comm error";
CM_ SG_ 2030 TRCM_a226_rightCPillarAccelSenso "TRCM ECU: a226 right c pillar accel sensor defect";
CM_ SG_ 2030 TRCM_a227_rightCPillarAccelSigna "TRCM ECU: a227 right c pillar accel signal monitor";
CM_ SG_ 2030 TRCM_a230_leftRearDoorPressureIn "TRCM ECU: a230 left rear door pressure init failure";
CM_ SG_ 2030 TRCM_a231_leftRearDoorPressureSh "TRCM ECU: a231 left rear door pressure short to ground";
CM_ SG_ 2030 TRCM_a232_leftRearDoorPressureSh "TRCM ECU: a232 left rear door pressure short to battery";
CM_ SG_ 2030 TRCM_a233_leftRearDoorPressureCo "TRCM ECU: a233 left rear door pressure config error";
CM_ SG_ 2030 TRCM_a234_leftRearDoorPressureOp "TRCM ECU: a234 left rear door pressure open";
CM_ SG_ 2030 TRCM_a235_leftRearDoorPressureCo "TRCM ECU: a235 left rear door pressure comm error";
CM_ SG_ 2030 TRCM_a236_leftRearDoorPressureSe "TRCM ECU: a236 left rear door pressure sensor defect";
CM_ SG_ 2030 TRCM_a237_leftRearDoorPressureSi "TRCM ECU: a237 left rear door pressure signal monitor";
CM_ SG_ 2030 TRCM_a240_rightRearDoorPressureI "TRCM ECU: a240 right rear door pressure init failure";
CM_ SG_ 2030 TRCM_a241_rightRearDoorPressureS "TRCM ECU: a241 right rear door pressure short to ground";
CM_ SG_ 2030 TRCM_a242_rightRearDoorPressureS "TRCM ECU: a242 right rear door pressure short to battery";
CM_ SG_ 2030 TRCM_a243_rightRearDoorPressureC "TRCM ECU: a243 right rear door pressure config error";
CM_ SG_ 2030 TRCM_a244_rightRearDoorPressureO "TRCM ECU: a244 right rear door pressure open";
CM_ SG_ 2030 TRCM_a245_rightRearDoorPressureC "TRCM ECU: a245 right rear door pressure comm error";
CM_ SG_ 2030 TRCM_a246_rightRearDoorPressureS "TRCM ECU: a246 right rear door pressure sensor defect";
CM_ SG_ 2030 TRCM_a247_rightRearDoorPressureS "TRCM ECU: a247 right rear door pressure signal monitor";
CM_ SG_ 2030 TRCM_a250_frontCenterAccelXInitF "TRCM ECU: a250 front center accel x init failure";
CM_ SG_ 2030 TRCM_a251_frontCenterAccelXShort "TRCM ECU: a251 front center accel x short to ground";
CM_ SG_ 2030 TRCM_a252_frontCenterAccelXShort "TRCM ECU: a252 front center accel x short to battery";
CM_ SG_ 2030 TRCM_a253_frontCenterAccelXConfi "TRCM ECU: a253 front center accel x config error";
CM_ SG_ 2030 TRCM_a254_frontCenterAccelXOpen "TRCM ECU: a254 front center accel x open";
CM_ SG_ 2030 TRCM_a255_frontCenterAccelXCommE "TRCM ECU: a255 front center accel x comm error";
CM_ SG_ 2030 TRCM_a256_frontCenterAccelXSenso "TRCM ECU: a256 front center accel x sensor defect";
CM_ SG_ 2030 TRCM_a257_frontCenterAccelXSigna "TRCM ECU: a257 front center accel x signal monitor";
CM_ SG_ 2030 TRCM_a260_frontCenterAccelYInitF "TRCM ECU: a260 front center accel y init failure";
CM_ SG_ 2030 TRCM_a261_frontCenterAccelYShort "TRCM ECU: a261 front center accel y short to ground";
CM_ SG_ 2030 TRCM_a262_frontCenterAccelYShort "TRCM ECU: a262 front center accel y short to battery";
CM_ SG_ 2030 TRCM_a263_frontCenterAccelYConfi "TRCM ECU: a263 front center accel y config error";
CM_ SG_ 2030 TRCM_a264_frontCenterAccelYOpen "TRCM ECU: a264 front center accel y open";
CM_ SG_ 2030 TRCM_a265_frontCenterAccelYCommE "TRCM ECU: a265 front center accel y comm error";
CM_ SG_ 2030 TRCM_a266_frontCenterAccelYSenso "TRCM ECU: a266 front center accel y sensor defect";
CM_ SG_ 2030 TRCM_a267_frontCenterAccelYSigna "TRCM ECU: a267 front center accel y signal monitor";
CM_ SG_ 2030 TRCM_a272_asm5ComStatusError "TRCM ECU: a272 asm5 com status error";
CM_ SG_ 2030 TRCM_a273_asm5ArsStatusXError "TRCM ECU: a273 asm5 ars status x error";
CM_ SG_ 2030 TRCM_a274_asm5ArsStatusZError "TRCM ECU: a274 asm5 ars status z error";
CM_ SG_ 2030 TRCM_a275_asm5AccStatusError "TRCM ECU: a275 asm5 acc status error";
CM_ SG_ 2030 TRCM_a276_watchdogStatus "TRCM ECU: a276 watchdog status";
CM_ SG_ 2030 TRCM_a278_safingEngine0Armed "TRCM ECU: a278 safing engine0 armed";
CM_ SG_ 2030 TRCM_a279_safingEngine1Armed "TRCM ECU: a279 safing engine1 armed";
CM_ SG_ 2030 TRCM_a280_safingEngine2Armed "TRCM ECU: a280 safing engine2 armed";
CM_ SG_ 2030 TRCM_a281_safingEngine3Armed "TRCM ECU: a281 safing engine3 armed";
CM_ SG_ 2030 TRCM_a282_safingEngine4Armed "TRCM ECU: a282 safing engine4 armed";
CM_ SG_ 2030 TRCM_a283_safingEngine5Armed "TRCM ECU: a283 safing engine5 armed";
CM_ SG_ 2030 TRCM_a284_safingEngine6Armed "TRCM ECU: a284 safing engine6 armed";
CM_ SG_ 2030 TRCM_a285_safingEngine7Armed "TRCM ECU: a285 safing engine7 armed";
CM_ SG_ 2030 TRCM_a286_safingEngine8Armed "TRCM ECU: a286 safing engine8 armed";
CM_ SG_ 2030 TRCM_a287_safingEngine9Armed "TRCM ECU: a287 safing engine9 armed";
CM_ SG_ 2030 TRCM_a288_safingEngine10Armed "TRCM ECU: a288 safing engine10 armed";
CM_ SG_ 2030 TRCM_a289_safingEngine11Armed "TRCM ECU: a289 safing engine11 armed";
CM_ SG_ 2030 TRCM_a290_safingEngine12Armed "TRCM ECU: a290 safing engine12 armed";
CM_ SG_ 2030 TRCM_a291_safingEngine13Armed "TRCM ECU: a291 safing engine13 armed";
CM_ SG_ 2030 TRCM_a292_safingEngine14Armed "TRCM ECU: a292 safing engine14 armed";
CM_ SG_ 2030 TRCM_a293_safingEngine15Armed "TRCM ECU: a293 safing engine15 armed";
CM_ SG_ 2030 TRCM_a294_safingEngine16Armed "TRCM ECU: a294 safing engine16 armed";
CM_ SG_ 2030 TRCM_a295_safingEngine17Armed "TRCM ECU: a295 safing engine17 armed";
CM_ SG_ 2030 TRCM_a296_safingEngine18Armed "TRCM ECU: a296 safing engine18 armed";
CM_ SG_ 2030 TRCM_a297_safingEngine19Armed "TRCM ECU: a297 safing engine19 armed";
CM_ SG_ 2030 TRCM_a298_safingEngine20Armed "TRCM ECU: a298 safing engine20 armed";
CM_ SG_ 2030 TRCM_a299_safingEngine21Armed "TRCM ECU: a299 safing engine21 armed";
CM_ SG_ 2030 TRCM_a300_unarmedAB1FPDeployComm "TRCM ECU: a300 unarmed AB1 FP deploy command";
CM_ SG_ 2030 TRCM_a301_unarmedAB1FDDeployComm "TRCM ECU: a301 unarmed AB1 FD deploy command";
CM_ SG_ 2030 TRCM_a302_unarmedAV1FPDeployComm "TRCM ECU: a302 unarmed AV1 FP deploy command";
CM_ SG_ 2030 TRCM_a303_unarmedFSABDeployComma "TRCM ECU: a303 unarmed FSAB deploy command";
CM_ SG_ 2030 TRCM_a304_unarmedAB2FPDeployComm "TRCM ECU: a304 unarmed AB2 FP deploy command";
CM_ SG_ 2030 TRCM_a305_unarmedAB2FDDeployComm "TRCM ECU: a305 unarmed AB2 FD deploy command";
CM_ SG_ 2030 TRCM_a306_unarmedAV1FDDeployComm "TRCM ECU: a306 unarmed AV1 FD deploy command";
CM_ SG_ 2030 TRCM_a307_unarmedLoop7DeployComm "TRCM ECU: a307 unarmed loop7 deploy command";
CM_ SG_ 2030 TRCM_a308_unarmedKA1FPDeployComm "TRCM ECU: a308 unarmed KA1 FP deploy command";
CM_ SG_ 2030 TRCM_a309_unarmedKA1FDDeployComm "TRCM ECU: a309 unarmed KA1 FD deploy command";
CM_ SG_ 2030 TRCM_a310_unarmedALLFRDeployComm "TRCM ECU: a310 unarmed ALLFR deploy command";
CM_ SG_ 2030 TRCM_a311_unarmedALLFLDeployComm "TRCM ECU: a311 unarmed ALLFL deploy command";
CM_ SG_ 2030 TRCM_a312_unarmedBT2FRDeployComm "TRCM ECU: a312 unarmed BT2 FR deploy command";
CM_ SG_ 2030 TRCM_a313_unarmedBT2FLDeployComm "TRCM ECU: a313 unarmed BT2 FL deploy command";
CM_ SG_ 2030 TRCM_a314_unarmedSA1FLDeployComm "TRCM ECU: a314 unarmed SA1 FL deploy command";
CM_ SG_ 2030 TRCM_a315_unarmedSA1FRDeployComm "TRCM ECU: a315 unarmed SA1 FR deploy command";
CM_ SG_ 2030 TRCM_a316_unarmedBT1RRDeployComm "TRCM ECU: a316 unarmed BT1 RR deploy command";
CM_ SG_ 2030 TRCM_a317_unarmedBT1RLDeployComm "TRCM ECU: a317 unarmed BT1 RL deploy command";
CM_ SG_ 2030 TRCM_a318_unarmedBT1FRDeployComm "TRCM ECU: a318 unarmed BT1 FR deploy command";
CM_ SG_ 2030 TRCM_a319_unarmedBT1FLDeployComm "TRCM ECU: a319 unarmed BT1 FL deploy command";
CM_ SG_ 2030 TRCM_a320_unarmedLoop20DeployCom "TRCM ECU: a320 unarmed loop20 deploy command";
CM_ SG_ 2030 TRCM_a321_unarmedLoop21DeployCom "TRCM ECU: a321 unarmed loop21 deploy command";
CM_ SG_ 2030 TRCM_a322_unarmedIC1FRDeployComm "TRCM ECU: a322 unarmed IC1 FR deploy command";
CM_ SG_ 2030 TRCM_a323_unarmedIC1FLDeployComm "TRCM ECU: a323 unarmed IC1 FL deploy command";
CM_ SG_ 2030 TRCM_a324_unarmedLoop24DeployCom "TRCM ECU: a324 unarmed loop24 deploy command";
CM_ SG_ 2030 TRCM_a325_unarmedLoop25DeployCom "TRCM ECU: a325 unarmed loop25 deploy command";
CM_ SG_ 2030 TRCM_a326_unarmedLoop26DeployCom "TRCM ECU: a326 unarmed loop26 deploy command";
CM_ SG_ 2030 TRCM_a327_unarmedLoop27DeployCom "TRCM ECU: a327 unarmed loop27 deploy command";
CM_ SG_ 2030 TRCM_a328_unarmedLoop28DeployCom "TRCM ECU: a328 unarmed loop28 deploy command";
CM_ SG_ 2030 TRCM_a329_unarmedLoop29DeployCom "TRCM ECU: a329 unarmed loop29 deploy command";
CM_ SG_ 2030 TRCM_a330_unarmedLoop30DeployCom "TRCM ECU: a330 unarmed loop30 deploy command";
CM_ SG_ 2030 TRCM_a331_unarmedLoop31DeployCom "TRCM ECU: a331 unarmed loop31 deploy command";
CM_ SG_ 2030 TRCM_a332_AB1FPDeployment "TRCM ECU: a332 AB1 FP deployment";
CM_ SG_ 2030 TRCM_a333_AB1FDDeployment "TRCM ECU: a333 AB1 FD deployment";
CM_ SG_ 2030 TRCM_a334_AV1FPDeployment "TRCM ECU: a334 AV1 FP deployment";
CM_ SG_ 2030 TRCM_a335_Loop3Deployment "TRCM ECU: a335 loop3 deployment";
CM_ SG_ 2030 TRCM_a336_AB2FPDeployment "TRCM ECU: a336 AB2 FP deployment";
CM_ SG_ 2030 TRCM_a337_AB2FDDeployment "TRCM ECU: a337 AB2 FD deployment";
CM_ SG_ 2030 TRCM_a338_AV1FDDeployment "TRCM ECU: a338 AV1 FD deployment";
CM_ SG_ 2030 TRCM_a339_Loop7Deployment "TRCM ECU: a339 loop7 deployment";
CM_ SG_ 2030 TRCM_a340_KA1FPDeployment "TRCM ECU: a340 KA1 FP deployment";
CM_ SG_ 2030 TRCM_a341_KA1FDDeployment "TRCM ECU: a341 KA1 FD deployment";
CM_ SG_ 2030 TRCM_a342_ALLFRDeployment "TRCM ECU: a342 ALLFR deployment";
CM_ SG_ 2030 TRCM_a343_ALLFLDeployment "TRCM ECU: a343 ALLFL deployment";
CM_ SG_ 2030 TRCM_a344_BT2FRDeployment "TRCM ECU: a344 BT2 FR deployment";
CM_ SG_ 2030 TRCM_a345_BT2FLDeployment "TRCM ECU: a345 BT2 FL deployment";
CM_ SG_ 2030 TRCM_a346_SA1FLDeployment "TRCM ECU: a346 SA1 FL deployment";
CM_ SG_ 2030 TRCM_a347_SA1FRDeployment "TRCM ECU: a347 SA1 FR deployment";
CM_ SG_ 2030 TRCM_a348_BT1RRDeployment "TRCM ECU: a348 BT1 RR deployment";
CM_ SG_ 2030 TRCM_a349_BT1RLDeployment "TRCM ECU: a349 BT1 RL deployment";
CM_ SG_ 2030 TRCM_a350_BT1FRDeployment "TRCM ECU: a350 BT1 FR deployment";
CM_ SG_ 2030 TRCM_a351_BT1FLDeployment "TRCM ECU: a351 BT1 FL deployment";
CM_ SG_ 2030 TRCM_a352_Loop20Deployment "TRCM ECU: a352 loop20 deployment";
CM_ SG_ 2030 TRCM_a353_Loop21Deployment "TRCM ECU: a353 loop21 deployment";
CM_ SG_ 2030 TRCM_a354_IC1FRDeployment "TRCM ECU: a354 IC1 FR deployment";
CM_ SG_ 2030 TRCM_a355_IC1FLDeployment "TRCM ECU: a355 IC1 FL deployment";
CM_ SG_ 2030 TRCM_a356_Loop24Deployment "TRCM ECU: a356 loop24 deployment";
CM_ SG_ 2030 TRCM_a357_Loop25Deployment "TRCM ECU: a357 loop25 deployment";
CM_ SG_ 2030 TRCM_a358_Loop26Deployment "TRCM ECU: a358 loop26 deployment";
CM_ SG_ 2030 TRCM_a359_Loop27Deployment "TRCM ECU: a359 loop27 deployment";
CM_ SG_ 2030 TRCM_a360_Loop28Deployment "TRCM ECU: a360 loop28 deployment";
CM_ SG_ 2030 TRCM_a361_Loop29Deployment "TRCM ECU: a361 loop29 deployment";
CM_ SG_ 2030 TRCM_a362_Loop30Deployment "TRCM ECU: a362 loop30 deployment";
CM_ SG_ 2030 TRCM_a363_Loop31Deployment "TRCM ECU: a363 loop31 deployment";
CM_ SG_ 2030 TRCM_a364_safingEngine0NoValidDa "TRCM ECU: a364 safing engine0 no valid data";
CM_ SG_ 2030 TRCM_a365_safingEngine1NoValidDa "TRCM ECU: a365 safing engine1 no valid data";
CM_ SG_ 2030 TRCM_a366_safingEngine2NoValidDa "TRCM ECU: a366 safing engine2 no valid data";
CM_ SG_ 2030 TRCM_a367_safingEngine3NoValidDa "TRCM ECU: a367 safing engine3 no valid data";
CM_ SG_ 2030 TRCM_a368_safingEngine4NoValidDa "TRCM ECU: a368 safing engine4 no valid data";
CM_ SG_ 2030 TRCM_a369_safingEngine5NoValidDa "TRCM ECU: a369 safing engine5 no valid data";
CM_ SG_ 2030 TRCM_a370_safingEngine6NoValidDa "TRCM ECU: a370 safing engine6 no valid data";
CM_ SG_ 2030 TRCM_a371_safingEngine7NoValidDa "TRCM ECU: a371 safing engine7 no valid data";
CM_ SG_ 2030 TRCM_a372_safingEngine8NoValidDa "TRCM ECU: a372 safing engine8 no valid data";
CM_ SG_ 2030 TRCM_a373_safingEngine9NoValidDa "TRCM ECU: a373 safing engine9 no valid data";
CM_ SG_ 2030 TRCM_a374_safingEngine10NoValidD "TRCM ECU: a374 safing engine10 no valid data";
CM_ SG_ 2030 TRCM_a375_safingEngine11NoValidD "TRCM ECU: a375 safing engine11 no valid data";
CM_ SG_ 2030 TRCM_a376_safingEngine12NoValidD "TRCM ECU: a376 safing engine12 no valid data";
CM_ SG_ 2030 TRCM_a377_safingEngine13NoValidD "TRCM ECU: a377 safing engine13 no valid data";
CM_ SG_ 2030 TRCM_a378_safingEngine14NoValidD "TRCM ECU: a378 safing engine14 no valid data";
CM_ SG_ 2030 TRCM_a379_safingEngine15NoValidD "TRCM ECU: a379 safing engine15 no valid data";
CM_ SG_ 2030 TRCM_a380_safingEngine16NoValidD "TRCM ECU: a380 safing engine16 no valid data";
CM_ SG_ 2030 TRCM_a381_safingEngine17NoValidD "TRCM ECU: a381 safing engine17 no valid data";
CM_ SG_ 2030 TRCM_a382_safingEngine18NoValidD "TRCM ECU: a382 safing engine18 no valid data";
CM_ SG_ 2030 TRCM_a383_safingEngine19NoValidD "TRCM ECU: a383 safing engine19 no valid data";
CM_ SG_ 2030 TRCM_a384_safingEngine20NoValidD "TRCM ECU: a384 safing engine20 no valid data";
CM_ SG_ 2030 TRCM_a385_safingEngine21NoValidD "TRCM ECU: a385 safing engine21 no valid data";
CM_ SG_ 2030 TRCM_a387_primaryAsicResetSource "TRCM ECU: a387 primary asic reset source";
CM_ SG_ 2030 TRCM_a388_cpuLoadHigh "TRCM ECU: a388 cpu load high";
CM_ SG_ 2030 TRCM_a389_asicPwrStatusError "TRCM ECU: a389 asic pwr status error";
CM_ SG_ 2030 TRCM_a390_systemAsicClockOrOpera "TRCM ECU: a390 system asic clock or operating state error";
CM_ SG_ 2030 TRCM_a391_extAsic1ClockOrOperati "TRCM ECU: a391 ext asic1 clock or operating state error";
CM_ SG_ 2030 TRCM_a392_extAsic2ClockOrOperati "TRCM ECU: a392 ext asic2 clock or operating state error";
CM_ SG_ 2030 TRCM_a393_depAdcConvertRatioErro "TRCM ECU: a393 dep adc convert ratio error";
CM_ SG_ 2030 TRCM_a394_gspiGlobalStatusWordEr "TRCM ECU: a394 gspi global status word error";
CM_ SG_ 2030 TRCM_a395_imuCalibrationNotDone "TRCM ECU: a395 imu calibration not done";
CM_ SG_ 2030 TRCM_a396_spiCommunicationProgra "TRCM ECU: a396 spi communication program error";
CM_ SG_ 2030 TRCM_a397_safingMonitorError "TRCM ECU: a397 safing monitor error";
CM_ SG_ 2030 TRCM_a398_asicNvmReprogrammed "TRCM ECU: a398 asic nvm reprogrammed";
CM_ SG_ 2030 TRCM_a400_AB1FPShortToGround "TRCM ECU: a400 AB1 FP short to ground";
CM_ SG_ 2030 TRCM_a401_AB1FPShortToBattery "TRCM ECU: a401 AB1 FP short to battery";
CM_ SG_ 2030 TRCM_a402_AB1FPOpen "TRCM ECU: a402 AB1 FP open";
CM_ SG_ 2030 TRCM_a403_AB1FPShortToSelf "TRCM ECU: a403 AB1 FP short to self";
CM_ SG_ 2030 TRCM_a404_AB1FPCrossCoupled "TRCM ECU: a404 AB1 FP cross coupled";
CM_ SG_ 2030 TRCM_a405_AB1FPConfigError "TRCM ECU: a405 AB1 FP config error";
CM_ SG_ 2030 TRCM_a406_AB1FDShortToGround "TRCM ECU: a406 AB1 FD short to ground";
CM_ SG_ 2030 TRCM_a407_AB1FDShortToBattery "TRCM ECU: a407 AB1 FD short to battery";
CM_ SG_ 2030 TRCM_a408_AB1FDOpen "TRCM ECU: a408 AB1 FD open";
CM_ SG_ 2030 TRCM_a409_AB1FDShortToSelf "TRCM ECU: a409 AB1 FD short to self";
CM_ SG_ 2030 TRCM_a410_AB1FDCrossCoupled "TRCM ECU: a410 AB1 FD cross coupled";
CM_ SG_ 2030 TRCM_a411_AB1FDConfigError "TRCM ECU: a411 AB1 FD config error";
CM_ SG_ 2030 TRCM_a412_PAVShortToGround "TRCM ECU: a412 PAV short to ground";
CM_ SG_ 2030 TRCM_a413_PAVShortToBattery "TRCM ECU: a413 PAV short to battery";
CM_ SG_ 2030 TRCM_a414_PAVOpen "TRCM ECU: a414 PAV open";
CM_ SG_ 2030 TRCM_a415_PAVShortToSelf "TRCM ECU: a415 PAV short to self";
CM_ SG_ 2030 TRCM_a416_PAVCrossCoupled "TRCM ECU: a416 PAV cross coupled";
CM_ SG_ 2030 TRCM_a417_PAVConfigError "TRCM ECU: a417 PAV config error";
CM_ SG_ 2030 TRCM_a418_AB2FPShortToGround "TRCM ECU: a418 AB2 FP short to ground";
CM_ SG_ 2030 TRCM_a419_AB2FPShortToBattery "TRCM ECU: a419 AB2 FP short to battery";
CM_ SG_ 2030 TRCM_a420_AB2FPOpen "TRCM ECU: a420 AB2 FP open";
CM_ SG_ 2030 TRCM_a421_AB2FPShortToSelf "TRCM ECU: a421 AB2 FP short to self";
CM_ SG_ 2030 TRCM_a422_AB2FPCrossCoupled "TRCM ECU: a422 AB2 FP cross coupled";
CM_ SG_ 2030 TRCM_a423_AB2FPConfigError "TRCM ECU: a423 AB2 FP config error";
CM_ SG_ 2030 TRCM_a424_AB2FDShortToGround "TRCM ECU: a424 AB2 FD short to ground";
CM_ SG_ 2030 TRCM_a425_AB2FDShortToBattery "TRCM ECU: a425 AB2 FD short to battery";
CM_ SG_ 2030 TRCM_a426_AB2FDOpen "TRCM ECU: a426 AB2 FD open";
CM_ SG_ 2030 TRCM_a427_AB2FDShortToSelf "TRCM ECU: a427 AB2 FD short to self";
CM_ SG_ 2030 TRCM_a428_AB2FDCrossCoupled "TRCM ECU: a428 AB2 FD cross coupled";
CM_ SG_ 2030 TRCM_a429_AB2FDConfigError "TRCM ECU: a429 AB2 FD config error";
CM_ SG_ 2030 TRCM_a430_DAVShortToGround "TRCM ECU: a430 DAV short to ground";
CM_ SG_ 2030 TRCM_a431_DAVShortToBattery "TRCM ECU: a431 DAV short to battery";
CM_ SG_ 2030 TRCM_a432_DAVOpen "TRCM ECU: a432 DAV open";
CM_ SG_ 2030 TRCM_a433_DAVShortToSelf "TRCM ECU: a433 DAV short to self";
CM_ SG_ 2030 TRCM_a434_DAVCrossCoupled "TRCM ECU: a434 DAV cross coupled";
CM_ SG_ 2030 TRCM_a435_DAVConfigError "TRCM ECU: a435 DAV config error";
CM_ SG_ 2030 TRCM_a436_IKBFPShortToGround "TRCM ECU: a436 IKBFP short to ground";
CM_ SG_ 2030 TRCM_a437_IKBFPShortToBattery "TRCM ECU: a437 IKBFP short to battery";
CM_ SG_ 2030 TRCM_a438_IKBFPOpen "TRCM ECU: a438 IKBFP open";
CM_ SG_ 2030 TRCM_a439_IKBFPShortToSelf "TRCM ECU: a439 IKBFP short to self";
CM_ SG_ 2030 TRCM_a440_IKBFPCrossCoupled "TRCM ECU: a440 IKBFP cross coupled";
CM_ SG_ 2030 TRCM_a441_IKBFPConfigError "TRCM ECU: a441 IKBFP config error";
CM_ SG_ 2030 TRCM_a442_IKBFDShortToGround "TRCM ECU: a442 IKBFD short to ground";
CM_ SG_ 2030 TRCM_a443_IKBFDShortToBattery "TRCM ECU: a443 IKBFD short to battery";
CM_ SG_ 2030 TRCM_a444_IKBFDOpen "TRCM ECU: a444 IKBFD open";
CM_ SG_ 2030 TRCM_a445_IKBFDShortToSelf "TRCM ECU: a445 IKBFD short to self";
CM_ SG_ 2030 TRCM_a446_IKBFDCrossCoupled "TRCM ECU: a446 IKBFD cross coupled";
CM_ SG_ 2030 TRCM_a447_IKBFDConfigError "TRCM ECU: a447 IKBFD config error";
CM_ SG_ 2030 TRCM_a448_PLLShortToGround "TRCM ECU: a448 PLL short to ground";
CM_ SG_ 2030 TRCM_a449_PLLShortToBattery "TRCM ECU: a449 PLL short to battery";
CM_ SG_ 2030 TRCM_a450_PLLOpen "TRCM ECU: a450 PLL open";
CM_ SG_ 2030 TRCM_a451_PLLShortToSelf "TRCM ECU: a451 PLL short to self";
CM_ SG_ 2030 TRCM_a452_PLLCrossCoupled "TRCM ECU: a452 PLL cross coupled";
CM_ SG_ 2030 TRCM_a453_PLLConfigError "TRCM ECU: a453 PLL config error";
CM_ SG_ 2030 TRCM_a454_DLLShortToGround "TRCM ECU: a454 DLL short to ground";
CM_ SG_ 2030 TRCM_a455_DLLShortToBattery "TRCM ECU: a455 DLL short to battery";
CM_ SG_ 2030 TRCM_a456_DLLOpen "TRCM ECU: a456 DLL open";
CM_ SG_ 2030 TRCM_a457_DLLShortToSelf "TRCM ECU: a457 DLL short to self";
CM_ SG_ 2030 TRCM_a458_DLLCrossCoupled "TRCM ECU: a458 DLL cross coupled";
CM_ SG_ 2030 TRCM_a459_DLLConfigError "TRCM ECU: a459 DLL config error";
CM_ SG_ 2030 TRCM_a460_BTRP_RetractorShortToG "TRCM ECU: a460 BTRP retractor short to ground";
CM_ SG_ 2030 TRCM_a461_BTRP_RetractorShortToB "TRCM ECU: a461 BTRP retractor short to battery";
CM_ SG_ 2030 TRCM_a462_BTRP_RetractorOpen "TRCM ECU: a462 BTRP retractor open";
CM_ SG_ 2030 TRCM_a463_BTRP_RetractorShortToS "TRCM ECU: a463 BTRP retractor short to self";
CM_ SG_ 2030 TRCM_a464_BTRP_RetractorCrossCou "TRCM ECU: a464 BTRP retractor cross coupled";
CM_ SG_ 2030 TRCM_a465_BTRP_RetractorConfigEr "TRCM ECU: a465 BTRP retractor config error";
CM_ SG_ 2030 TRCM_a466_BTRD_RetractorShortToG "TRCM ECU: a466 BTRD retractor short to ground";
CM_ SG_ 2030 TRCM_a467_BTRD_RetractorShortToB "TRCM ECU: a467 BTRD retractor short to battery";
CM_ SG_ 2030 TRCM_a468_BTRD_RetractorOpen "TRCM ECU: a468 BTRD retractor open";
CM_ SG_ 2030 TRCM_a469_BTRD_RetractorShortToS "TRCM ECU: a469 BTRD retractor short to self";
CM_ SG_ 2030 TRCM_a470_BTRD_RetractorCrossCou "TRCM ECU: a470 BTRD retractor cross coupled";
CM_ SG_ 2030 TRCM_a471_BTRD_RetractorConfigEr "TRCM ECU: a471 BTRD retractor config error";
CM_ SG_ 2030 TRCM_a472_SA1FLShortToGround "TRCM ECU: a472 SA1 FL short to ground";
CM_ SG_ 2030 TRCM_a473_SA1FLShortToBattery "TRCM ECU: a473 SA1 FL short to battery";
CM_ SG_ 2030 TRCM_a474_SA1FLOpen "TRCM ECU: a474 SA1 FL open";
CM_ SG_ 2030 TRCM_a475_SA1FLShortToSelf "TRCM ECU: a475 SA1 FL short to self";
CM_ SG_ 2030 TRCM_a476_SA1FLCrossCoupled "TRCM ECU: a476 SA1 FL cross coupled";
CM_ SG_ 2030 TRCM_a477_SA1FLConfigError "TRCM ECU: a477 SA1 FL config error";
CM_ SG_ 2030 TRCM_a478_SA1FRShortToGround "TRCM ECU: a478 SA1 FR short to ground";
CM_ SG_ 2030 TRCM_a479_SA1FRShortToBattery "TRCM ECU: a479 SA1 FR short to battery";
CM_ SG_ 2030 TRCM_a480_SA1FROpen "TRCM ECU: a480 SA1 FR open";
CM_ SG_ 2030 TRCM_a481_SA1FRShortToSelf "TRCM ECU: a481 SA1 FR short to self";
CM_ SG_ 2030 TRCM_a482_SA1FRCrossCoupled "TRCM ECU: a482 SA1 FR cross coupled";
CM_ SG_ 2030 TRCM_a483_SA1FRConfigError "TRCM ECU: a483 SA1 FR config error";
CM_ SG_ 2030 TRCM_a484_BTRRShortToGround "TRCM ECU: a484 BTRR short to ground";
CM_ SG_ 2030 TRCM_a485_BTRRShortToBattery "TRCM ECU: a485 BTRR short to battery";
CM_ SG_ 2030 TRCM_a486_BTRROpen "TRCM ECU: a486 BTRR open";
CM_ SG_ 2030 TRCM_a487_BTRRShortToSelf "TRCM ECU: a487 BTRR short to self";
CM_ SG_ 2030 TRCM_a488_BTRRCrossCoupled "TRCM ECU: a488 BTRR cross coupled";
CM_ SG_ 2030 TRCM_a489_BTRRConfigError "TRCM ECU: a489 BTRR config error";
CM_ SG_ 2030 TRCM_a490_BTRLShortToGround "TRCM ECU: a490 BTRL short to ground";
CM_ SG_ 2030 TRCM_a491_BTRLShortToBattery "TRCM ECU: a491 BTRL short to battery";
CM_ SG_ 2030 TRCM_a492_BTRLOpen "TRCM ECU: a492 BTRL open";
CM_ SG_ 2030 TRCM_a493_BTRLShortToSelf "TRCM ECU: a493 BTRL short to self";
CM_ SG_ 2030 TRCM_a494_BTRLCrossCoupled "TRCM ECU: a494 BTRL cross coupled";
CM_ SG_ 2030 TRCM_a495_BTRLConfigError "TRCM ECU: a495 BTRL config error";
CM_ SG_ 2030 TRCM_a496_BTRP_AnchorShortToGrou "TRCM ECU: a496 BTRP anchor short to ground";
CM_ SG_ 2030 TRCM_a497_BTRP_AnchorShortToBatt "TRCM ECU: a497 BTRP anchor short to battery";
CM_ SG_ 2030 TRCM_a498_BTRP_AnchorOpen "TRCM ECU: a498 BTRP anchor open";
CM_ SG_ 2030 TRCM_a499_BTRP_AnchorShortToSelf "TRCM ECU: a499 BTRP anchor short to self";
CM_ SG_ 2030 TRCM_a500_BTRP_AnchorCrossCouple "TRCM ECU: a500 BTRP anchor cross coupled";
CM_ SG_ 2030 TRCM_a501_BTRP_AnchorConfigError "TRCM ECU: a501 BTRP anchor config error";
CM_ SG_ 2030 TRCM_a502_BTRD_AnchorShortToGrou "TRCM ECU: a502 BTRD anchor short to ground";
CM_ SG_ 2030 TRCM_a503_BTRD_AnchorShortToBatt "TRCM ECU: a503 BTRD anchor short to battery";
CM_ SG_ 2030 TRCM_a504_BTRD_AnchorOpen "TRCM ECU: a504 BTRD anchor open";
CM_ SG_ 2030 TRCM_a505_BTRD_AnchorShortToSelf "TRCM ECU: a505 BTRD anchor short to self";
CM_ SG_ 2030 TRCM_a506_BTRD_AnchorCrossCouple "TRCM ECU: a506 BTRD anchor cross coupled";
CM_ SG_ 2030 TRCM_a507_BTRD_AnchorConfigError "TRCM ECU: a507 BTRD anchor config error";
CM_ SG_ 2030 TRCM_a508_IC1FRShortToGround "TRCM ECU: a508 IC1 FR short to ground";
CM_ SG_ 2030 TRCM_a509_IC1FRShortToBattery "TRCM ECU: a509 IC1 FR short to battery";
CM_ SG_ 2030 TRCM_a510_IC1FROpen "TRCM ECU: a510 IC1 FR open";
CM_ SG_ 2030 TRCM_a511_IC1FRShortToSelf "TRCM ECU: a511 IC1 FR short to self";
CM_ SG_ 2030 TRCM_a512_IC1FRCrossCoupled "TRCM ECU: a512 IC1 FR cross coupled";
CM_ SG_ 2030 TRCM_a513_IC1FRConfigError "TRCM ECU: a513 IC1 FR config error";
CM_ SG_ 2030 TRCM_a514_IC1FLShortToGround "TRCM ECU: a514 IC1 FL short to ground";
CM_ SG_ 2030 TRCM_a515_IC1FLShortToBattery "TRCM ECU: a515 IC1 FL short to battery";
CM_ SG_ 2030 TRCM_a516_IC1FLOpen "TRCM ECU: a516 IC1 FL open";
CM_ SG_ 2030 TRCM_a517_IC1FLShortToSelf "TRCM ECU: a517 IC1 FL short to self";
CM_ SG_ 2030 TRCM_a518_IC1FLCrossCoupled "TRCM ECU: a518 IC1 FL cross coupled";
CM_ SG_ 2030 TRCM_a519_IC1FLConfigError "TRCM ECU: a519 IC1 FL config error";
CM_ SG_ 2030 TRCM_a520_FSABShortToGround "TRCM ECU: a520 FSAB short to ground";
CM_ SG_ 2030 TRCM_a521_FSABShortToBattery "TRCM ECU: a521 FSAB short to battery";
CM_ SG_ 2030 TRCM_a522_FSABOpen "TRCM ECU: a522 FSAB open";
CM_ SG_ 2030 TRCM_a523_FSABShortToSelf "TRCM ECU: a523 FSAB short to self";
CM_ SG_ 2030 TRCM_a524_FSABCrossCoupled "TRCM ECU: a524 FSAB cross coupled";
CM_ SG_ 2030 TRCM_a525_FSABConfigError "TRCM ECU: a525 FSAB config error";
CM_ SG_ 2030 TRCM_a544_erCapDiagnosticsFailed "TRCM ECU: a544 er cap diagnostics failed";
CM_ SG_ 2030 TRCM_a545_erCapBelowAutarkyThres "TRCM ECU: a545 er cap below autarky threshold";
CM_ SG_ 2030 TRCM_a546_sensorValuesFaultedByS "TRCM ECU: a546 sensor values faulted by smart";
CM_ SG_ 2030 TRCM_a550_AlgoWake_RCM_WAKE_FRON "TRCM ECU: a550 algo wake RCM WAKE FRONT";
CM_ SG_ 2030 TRCM_a551_AlgoWake_RCM_WAKE_REAR "TRCM ECU: a551 algo wake RCM WAKE REAR";
CM_ SG_ 2030 TRCM_a552_AlgoWake_RCM_WAKE_LEFT "TRCM ECU: a552 algo wake RCM WAKE LEFT";
CM_ SG_ 2030 TRCM_a553_AlgoWake_RCM_WAKE_RIGH "TRCM ECU: a553 algo wake RCM WAKE RIGHT";
CM_ SG_ 2030 TRCM_a554_AlgoWake_PAS_LH_PLAUSI "TRCM ECU: a554 algo wake PAS LH PLAUSI FRONT";
CM_ SG_ 2030 TRCM_a555_AlgoWake_PAS_LH_PLAUSI "TRCM ECU: a555 algo wake PAS LH PLAUSI REAR";
CM_ SG_ 2030 TRCM_a556_AlgoWake_PAS_LH_PLAUSI "TRCM ECU: a556 algo wake PAS LH PLAUSI";
CM_ SG_ 2030 TRCM_a557_AlgoWake_PAS_RH_PLAUSI "TRCM ECU: a557 algo wake PAS RH PLAUSI FRONT";
CM_ SG_ 2030 TRCM_a558_AlgoWake_PAS_RH_PLAUSI "TRCM ECU: a558 algo wake PAS RH PLAUSI REAR";
CM_ SG_ 2030 TRCM_a559_AlgoWake_PAS_RH_PLAUSI "TRCM ECU: a559 algo wake PAS RH PLAUSI";
CM_ SG_ 2030 TRCM_a560_AlgoWake_RCM_WAKE_ROLL "TRCM ECU: a560 algo wake RCM WAKE ROLL LEFT";
CM_ SG_ 2030 TRCM_a561_AlgoWake_RCM_WAKE_ROLL "TRCM ECU: a561 algo wake RCM WAKE ROLL RIGHT";
CM_ SG_ 2030 TRCM_a562_AlgoWake_RCM_AWAKE_FRO "TRCM ECU: a562 algo wake RCM AWAKE FRONT";
CM_ SG_ 2030 TRCM_a563_AlgoWake_RCM_AWAKE_REA "TRCM ECU: a563 algo wake RCM AWAKE REAR";
CM_ SG_ 2030 TRCM_a564_AlgoWake_RCM_AWAKE_LEF "TRCM ECU: a564 algo wake RCM AWAKE LEFT";
CM_ SG_ 2030 TRCM_a565_AlgoWake_RCM_AWAKE_RIG "TRCM ECU: a565 algo wake RCM AWAKE RIGHT";
CM_ SG_ 2030 TRCM_a566_AlgoWake_RCM_AWAKE_ROL "TRCM ECU: a566 algo wake RCM AWAKE ROLL";
CM_ SG_ 2030 TRCM_a567_AlgoWake_RCM_AWAKE_X "TRCM ECU: a567 algo wake RCM AWAKE x";
CM_ SG_ 2030 TRCM_a568_AlgoWake_RCM_AWAKE_Y "TRCM ECU: a568 algo wake RCM AWAKE y";
CM_ SG_ 2030 TRCM_a569_AlgoWake_IMPACT_FINISH "TRCM ECU: a569 algo wake IMPACT FINISH x FRONT";
CM_ SG_ 2030 TRCM_a570_AlgoWake_IMPACT_FINISH "TRCM ECU: a570 algo wake IMPACT FINISH x REAR";
CM_ SG_ 2030 TRCM_a571_AlgoWake_IMPACT_FINISH "TRCM ECU: a571 algo wake IMPACT FINISH y RCM POS";
CM_ SG_ 2030 TRCM_a572_AlgoWake_IMPACT_FINISH "TRCM ECU: a572 algo wake IMPACT FINISH y RCM NEG";
CM_ SG_ 2030 TRCM_a573_AlgoWake_IMPACT_FINISH "TRCM ECU: a573 algo wake IMPACT FINISH y RCM";
CM_ SG_ 2030 TRCM_a574_AlgoWake_IMPACT_FINISH "TRCM ECU: a574 algo wake IMPACT FINISH ROLL RIGHT";
CM_ SG_ 2030 TRCM_a575_AlgoWake_IMPACT_FINISH "TRCM ECU: a575 algo wake IMPACT FINISH ROLL LEFT";
CM_ SG_ 2030 TRCM_a576_AlgoWake_IMPACT_FINISH "TRCM ECU: a576 algo wake IMPACT FINISH x";
CM_ SG_ 2030 TRCM_a577_AlgoWake_IMPACT_FINISH "TRCM ECU: a577 algo wake IMPACT FINISH y";
CM_ SG_ 2030 TRCM_a578_AlgoWake_IMPACT_FINISH "TRCM ECU: a578 algo wake IMPACT FINISH ROLL";
CM_ SG_ 2030 TRCM_a579_AlgoWake_RCM_ENABLED_X "TRCM ECU: a579 algo wake RCM ENABLED x";
CM_ SG_ 2030 TRCM_a580_AlgoWake_RCM_ENABLED_Y "TRCM ECU: a580 algo wake RCM ENABLED y";
CM_ SG_ 2030 TRCM_a581_AlgoWake_RCM_ENABLED_R "TRCM ECU: a581 algo wake RCM ENABLED ROLL";
CM_ SG_ 2030 TRCM_a582_AlgoWake_RCM_AWAKE "TRCM ECU: a582 algo wake RCM AWAKE";
CM_ SG_ 2030 TRCM_a588_yawRateOffsetPosLimit "TRCM ECU: a588 yaw rate offset pos limit";
CM_ SG_ 2030 TRCM_a589_yawRateOffsetNegLimit "TRCM ECU: a589 yaw rate offset neg limit";
CM_ SG_ 2030 TRCM_a590_pitchRateOffsetPosLimi "TRCM ECU: a590 pitch rate offset pos limit";
CM_ SG_ 2030 TRCM_a591_pitchRateOffsetNegLimi "TRCM ECU: a591 pitch rate offset neg limit";
CM_ SG_ 2030 TRCM_a592_rollRateOffsetPosLimit "TRCM ECU: a592 roll rate offset pos limit";
CM_ SG_ 2030 TRCM_a593_rollRateOffsetNegLimit "TRCM ECU: a593 roll rate offset neg limit";
CM_ SG_ 2030 TRCM_a594_longitudinalAccelOffse "TRCM ECU: a594 longitudinal accel offset pos limit";
CM_ SG_ 2030 TRCM_a595_longitudinalAccelOffse "TRCM ECU: a595 longitudinal accel offset neg limit";
CM_ SG_ 2030 TRCM_a596_lateralAccelOffsetPosL "TRCM ECU: a596 lateral accel offset pos limit";
CM_ SG_ 2030 TRCM_a597_lateralAccelOffsetNegL "TRCM ECU: a597 lateral accel offset neg limit";
CM_ SG_ 2030 TRCM_a598_verticalAccelOffsetPos "TRCM ECU: a598 vertical accel offset pos limit";
CM_ SG_ 2030 TRCM_a599_verticalAccelOffsetNeg "TRCM ECU: a599 vertical accel offset neg limit";
CM_ SG_ 2030 TRCM_a600_airbagAsicStartupFailu "TRCM ECU: a600 airbag asic startup failure";
CM_ SG_ 2030 TRCM_a601_loop0AsicStartupDiagno "TRCM ECU: a601 loop0 asic startup diagnostic failure";
CM_ SG_ 2030 TRCM_a602_loop1AsicStartupDiagno "TRCM ECU: a602 loop1 asic startup diagnostic failure";
CM_ SG_ 2030 TRCM_a603_loop2AsicStartupDiagno "TRCM ECU: a603 loop2 asic startup diagnostic failure";
CM_ SG_ 2030 TRCM_a604_loop3AsicStartupDiagno "TRCM ECU: a604 loop3 asic startup diagnostic failure";
CM_ SG_ 2030 TRCM_a605_loop4AsicStartupDiagno "TRCM ECU: a605 loop4 asic startup diagnostic failure";
CM_ SG_ 2030 TRCM_a606_loop5AsicStartupDiagno "TRCM ECU: a606 loop5 asic startup diagnostic failure";
CM_ SG_ 2030 TRCM_a607_loop6AsicStartupDiagno "TRCM ECU: a607 loop6 asic startup diagnostic failure";
CM_ SG_ 2030 TRCM_a608_loop7AsicStartupDiagno "TRCM ECU: a608 loop7 asic startup diagnostic failure";
CM_ SG_ 2030 TRCM_a609_loop8AsicStartupDiagno "TRCM ECU: a609 loop8 asic startup diagnostic failure";
CM_ SG_ 2030 TRCM_a610_loop9AsicStartupDiagno "TRCM ECU: a610 loop9 asic startup diagnostic failure";
CM_ SG_ 2030 TRCM_a611_loop10AsicStartupDiagn "TRCM ECU: a611 loop10 asic startup diagnostic failure";
CM_ SG_ 2030 TRCM_a612_loop11AsicStartupDiagn "TRCM ECU: a612 loop11 asic startup diagnostic failure";
CM_ SG_ 2030 TRCM_a613_loop12AsicStartupDiagn "TRCM ECU: a613 loop12 asic startup diagnostic failure";
CM_ SG_ 2030 TRCM_a614_loop13AsicStartupDiagn "TRCM ECU: a614 loop13 asic startup diagnostic failure";
CM_ SG_ 2030 TRCM_a615_loop14AsicStartupDiagn "TRCM ECU: a615 loop14 asic startup diagnostic failure";
CM_ SG_ 2030 TRCM_a616_loop15AsicStartupDiagn "TRCM ECU: a616 loop15 asic startup diagnostic failure";
CM_ SG_ 2030 TRCM_a617_loop16AsicStartupDiagn "TRCM ECU: a617 loop16 asic startup diagnostic failure";
CM_ SG_ 2030 TRCM_a618_loop17AsicStartupDiagn "TRCM ECU: a618 loop17 asic startup diagnostic failure";
CM_ SG_ 2030 TRCM_a619_loop18AsicStartupDiagn "TRCM ECU: a619 loop18 asic startup diagnostic failure";
CM_ SG_ 2030 TRCM_a620_loop19AsicStartupDiagn "TRCM ECU: a620 loop19 asic startup diagnostic failure";
CM_ SG_ 2030 TRCM_a621_loop20AsicStartupDiagn "TRCM ECU: a621 loop20 asic startup diagnostic failure";
CM_ SG_ 2030 TRCM_a622_loop21AsicStartupDiagn "TRCM ECU: a622 loop21 asic startup diagnostic failure";
CM_ SG_ 2030 TRCM_a623_loop22AsicStartupDiagn "TRCM ECU: a623 loop22 asic startup diagnostic failure";
CM_ SG_ 2030 TRCM_a624_loop23AsicStartupDiagn "TRCM ECU: a624 loop23 asic startup diagnostic failure";
CM_ SG_ 2030 TRCM_a625_loop24AsicStartupDiagn "TRCM ECU: a625 loop24 asic startup diagnostic failure";
CM_ SG_ 2030 TRCM_a626_loop25AsicStartupDiagn "TRCM ECU: a626 loop25 asic startup diagnostic failure";
CM_ SG_ 2030 TRCM_a627_loop26AsicStartupDiagn "TRCM ECU: a627 loop26 asic startup diagnostic failure";
CM_ SG_ 2030 TRCM_a628_loop27AsicStartupDiagn "TRCM ECU: a628 loop27 asic startup diagnostic failure";
CM_ SG_ 2030 TRCM_a629_loop28AsicStartupDiagn "TRCM ECU: a629 loop28 asic startup diagnostic failure";
CM_ SG_ 2030 TRCM_a630_loop29AsicStartupDiagn "TRCM ECU: a630 loop29 asic startup diagnostic failure";
CM_ SG_ 2030 TRCM_a631_loop30AsicStartupDiagn "TRCM ECU: a631 loop30 asic startup diagnostic failure";
CM_ SG_ 2030 TRCM_a632_loop31AsicStartupDiagn "TRCM ECU: a632 loop31 asic startup diagnostic failure";
CM_ BO_ 1641 "UDS ECU message: KOSTI asccm request";
CM_ SG_ 1641 UDS_KOSTIAsccmRequestData "UDS ECU: KOSTI asccm request data";
CM_ BO_ 1538 "UDS ECU message: bms request";
CM_ SG_ 1538 UDS_bmsRequestData "UDS ECU: bms request data";
CM_ BO_ 1579 "UDS ECU message: cc request";
CM_ SG_ 1579 UDS_ccRequestData "UDS ECU: cc request data";
CM_ BO_ 1539 "UDS ECU message: cmp request";
CM_ SG_ 1539 UDS_cmpRequestData "UDS ECU: cmp request data";
CM_ BO_ 1543 "UDS ECU message: cmpd request";
CM_ SG_ 1543 UDS_cmpdRequestData "UDS ECU: cmpd request data";
CM_ BO_ 1550 "UDS ECU message: cp request";
CM_ SG_ 1550 UDS_cpRequestData "UDS ECU: cp request data";
CM_ BO_ 1609 "UDS ECU message: das request";
CM_ SG_ 1609 UDS_dasRequestData "UDS ECU: das request data";
CM_ BO_ 1589 "UDS ECU message: di request";
CM_ SG_ 1589 UDS_diRequestData "UDS ECU: di request data";
CM_ BO_ 1541 "UDS ECU message: dif request";
CM_ SG_ 1541 UDS_difRequestData "UDS ECU: dif request data";
CM_ BO_ 1542 "UDS ECU message: dir request";
CM_ SG_ 1542 UDS_dirRequestData "UDS ECU: dir request data";
CM_ BO_ 1584 "UDS ECU message: epas3p request";
CM_ SG_ 1584 UDS_epas3pRequestData "UDS ECU: epas3p request data";
CM_ BO_ 1840 "UDS ECU message: epas3s request";
CM_ SG_ 1840 UDS_epas3sRequestData "UDS ECU: epas3s request data";
CM_ BO_ 1572 "UDS ECU message: epbl request";
CM_ SG_ 1572 UDS_epblRequestData_H "UDS ECU: epbl request data h";
CM_ SG_ 1572 UDS_epblRequestData_L "UDS ECU: epbl request data l";
CM_ BO_ 1574 "UDS ECU message: epbr request";
CM_ SG_ 1574 UDS_epbrRequestData_H "UDS ECU: epbr request data h";
CM_ SG_ 1574 UDS_epbrRequestData_L "UDS ECU: epbr request data l";
CM_ BO_ 1605 "UDS ECU message: esp request";
CM_ SG_ 1605 UDS_espRequestData "UDS ECU: esp request data";
CM_ BO_ 2015 "UDS ECU message: functional request";
CM_ SG_ 2015 UDS_functionalRequestData_0 "UDS ECU: functional request data 0";
CM_ SG_ 2015 UDS_functionalRequestData_1 "UDS ECU: functional request data 1";
CM_ SG_ 2015 UDS_functionalRequestData_2 "UDS ECU: functional request data 2";
CM_ SG_ 2015 UDS_functionalRequestData_3 "UDS ECU: functional request data 3";
CM_ SG_ 2015 UDS_functionalRequestData_4 "UDS ECU: functional request data 4";
CM_ SG_ 2015 UDS_functionalRequestData_5 "UDS ECU: functional request data 5";
CM_ SG_ 2015 UDS_functionalRequestData_6 "UDS ECU: functional request data 6";
CM_ SG_ 2015 UDS_functionalRequestData_7 "UDS ECU: functional request data 7";
CM_ BO_ 2014 "UDS ECU message: functional request CH";
CM_ SG_ 2014 UDS_functionalRequestDataCH "UDS ECU: functional request data CH";
CM_ BO_ 1552 "UDS ECU message: hvp request";
CM_ SG_ 1552 UDS_hvpRequestData "UDS ECU: hvp request data";
CM_ BO_ 1613 "UDS ECU message: ibst request";
CM_ SG_ 1613 UDS_ibstRequestData "UDS ECU: ibst request data";
BA_DEF_ BO_ "GenMsgCycleTime" INT 0 3600000;
BA_DEF_ BO_ "GenMsgSendType" ENUM "Cyclic","NotUsed","NotUsed","NotUsed","NotUsed","NotUsed","NotUsed","IfActive","NoMsgSendType","NotUsed";
BA_DEF_ BO_ "VFrameFormat" ENUM "StandardCAN","ExtendedCAN","reserved","J1939PG","reserved","reserved","reserved","reserved","reserved","reserved","reserved","reserved","reserved","reserved","StandardCAN_FD","ExtendedCAN_FD";
BA_DEF_ BO_ "CANFD_BRS" ENUM "0","1";
BA_DEF_ SG_ "GenSigSNA" STRING;
BA_DEF_ SG_ "SystemSignalLongSymbol" STRING;
BA_DEF_ SG_ "Confidence" ENUM "validated","plausible","layout-only","contradicted";
BA_DEF_DEF_ "GenMsgCycleTime" 0;
BA_DEF_DEF_ "GenMsgSendType" "NoMsgSendType";
BA_DEF_DEF_ "VFrameFormat" "StandardCAN";
BA_DEF_DEF_ "CANFD_BRS" "1";
BA_DEF_DEF_ "GenSigSNA" "";
BA_DEF_DEF_ "SystemSignalLongSymbol" "";
BA_DEF_DEF_ "Confidence" "layout-only";
BA_ "GenMsgCycleTime" BO_ 2030 100;
BA_ "GenMsgSendType" BO_ 2030 0;
BA_ "Confidence" SG_ 1298 TRCM_alertID 1;
BA_ "Confidence" SG_ 1298 TRCM_alertState 1;
BA_ "Confidence" SG_ 1298 TRCM_a059_voltageDrop 1;
BA_ "Confidence" SG_ 1298 TRCM_a059_resistanceEstimate 1;
BA_ "Confidence" SG_ 1298 TRCM_a059_current 1;
BA_ "Confidence" SG_ 1298 TRCM_a063_ADCVoltage 1;
BA_ "SystemSignalLongSymbol" SG_ 1298 TRCM_a101_LIPC_externalWatchdogH "TRCM_a101_LIPC_externalWatchdogHeartBeat";
BA_ "SystemSignalLongSymbol" SG_ 1298 TRCM_a115_UI_corianderVehicleCon "TRCM_a115_UI_corianderVehicleControl";
BA_ "SystemSignalLongSymbol" SG_ 1298 TRCM_a117_VEH_intrusionSensorSta "TRCM_a117_VEH_intrusionSensorStatus";
BA_ "SystemSignalLongSymbol" SG_ 1298 TRCM_a118_PARTY_outputPowerStatu "TRCM_a118_PARTY_outputPowerStatus";
BA_ "SystemSignalLongSymbol" SG_ 1298 TRCM_a118_VEH_interNodeResistanc "TRCM_a118_VEH_interNodeResistance";
BA_ "SystemSignalLongSymbol" SG_ 1298 TRCM_a118_PARTY_AP_vehicleState1 "TRCM_a118_PARTY_AP_vehicleState1HzMuxed";
BA_ "SystemSignalLongSymbol" SG_ 1298 TRCM_a118_BDY_AP_vehicleState1Hz "TRCM_a118_BDY_AP_vehicleState1HzMuxed";
BA_ "SystemSignalLongSymbol" SG_ 1298 TRCM_a120_VEH_aggregatedAxleSpee "TRCM_a120_VEH_aggregatedAxleSpeed";
BA_ "SystemSignalLongSymbol" SG_ 1298 TRCM_a120_PARTY_aggregatedAxleSp "TRCM_a120_PARTY_aggregatedAxleSpeed";
BA_ "SystemSignalLongSymbol" SG_ 1298 TRCM_a120_PARTY_stalklessInterfa "TRCM_a120_PARTY_stalklessInterfaces";
BA_ "Confidence" SG_ 2030 TRCM_matrixIndex 1;
BA_ "SystemSignalLongSymbol" SG_ 2030 TRCM_a012_asm5TemperatureOutside "TRCM_a012_asm5TemperatureOutsideSignalRange";
BA_ "SystemSignalLongSymbol" SG_ 2030 TRCM_a014_asm3TemperatureOutside "TRCM_a014_asm3TemperatureOutsideSignalRange";
BA_ "SystemSignalLongSymbol" SG_ 2030 TRCM_a017_asm5TemperatureOutside "TRCM_a017_asm5TemperatureOutsideOperatingRange";
BA_ "SystemSignalLongSymbol" SG_ 2030 TRCM_a018_asm3TemperatureOutside "TRCM_a018_asm3TemperatureOutsideOperatingRange";
BA_ "SystemSignalLongSymbol" SG_ 2030 TRCM_a026_airbagAsicDiagnosticFa "TRCM_a026_airbagAsicDiagnosticFault";
BA_ "SystemSignalLongSymbol" SG_ 2030 TRCM_a027_airbagAsicDeploymentDi "TRCM_a027_airbagAsicDeploymentDiagnosticFault";
BA_ "SystemSignalLongSymbol" SG_ 2030 TRCM_a074_ais2120SelfTestXPositi "TRCM_a074_ais2120SelfTestXPositiveFailed";
BA_ "SystemSignalLongSymbol" SG_ 2030 TRCM_a075_ais2120SelfTestXNegati "TRCM_a075_ais2120SelfTestXNegativeFailed";
BA_ "SystemSignalLongSymbol" SG_ 2030 TRCM_a076_ais2120SelfTestYPositi "TRCM_a076_ais2120SelfTestYPositiveFailed";
BA_ "SystemSignalLongSymbol" SG_ 2030 TRCM_a077_ais2120SelfTestYNegati "TRCM_a077_ais2120SelfTestYNegativeFailed";
BA_ "SystemSignalLongSymbol" SG_ 2030 TRCM_a121_glacierInitialStatusFa "TRCM_a121_glacierInitialStatusFailure";
BA_ "SystemSignalLongSymbol" SG_ 2030 TRCM_a122_glacierTraceabilityRea "TRCM_a122_glacierTraceabilityReadoutA0A0Failure";
BA_ "SystemSignalLongSymbol" SG_ 2030 TRCM_a123_glacierTraceabilityRea "TRCM_a123_glacierTraceabilityReadoutB0B0Failure";
BA_ "SystemSignalLongSymbol" SG_ 2030 TRCM_a124_glacierRegisterPattern "TRCM_a124_glacierRegisterPatternWriteFailure";
BA_ "SystemSignalLongSymbol" SG_ 2030 TRCM_a125_glacierFixedPatternSel "TRCM_a125_glacierFixedPatternSelfTestFailure";
BA_ "SystemSignalLongSymbol" SG_ 2030 TRCM_a126_glacierSelfTestEFailur "TRCM_a126_glacierSelfTestEFailure";
BA_ "SystemSignalLongSymbol" SG_ 2030 TRCM_a127_glacierSelfTestFFailur "TRCM_a127_glacierSelfTestFFailure";
BA_ "SystemSignalLongSymbol" SG_ 2030 TRCM_a128_glacierAnalogSelfTestF "TRCM_a128_glacierAnalogSelfTestFailure";
BA_ "SystemSignalLongSymbol" SG_ 2030 TRCM_a129_glacierOscillatorVerif "TRCM_a129_glacierOscillatorVerificationFailure";
BA_ "SystemSignalLongSymbol" SG_ 2030 TRCM_a130_glacierFinalStatusFail "TRCM_a130_glacierFinalStatusFailure";
BA_ "SystemSignalLongSymbol" SG_ 2030 TRCM_a131_glacierOffsetVerificat "TRCM_a131_glacierOffsetVerificationFailure";
BA_ "SystemSignalLongSymbol" SG_ 2030 TRCM_a132_glacierNormalOperation "TRCM_a132_glacierNormalOperationFailure";
BA_ "SystemSignalLongSymbol" SG_ 2030 TRCM_a137_ext1AsicSnoopTestFaile "TRCM_a137_ext1AsicSnoopTestFailed";
BA_ "SystemSignalLongSymbol" SG_ 2030 TRCM_a138_ext2AsicSnoopTestFaile "TRCM_a138_ext2AsicSnoopTestFailed";
BA_ "SystemSignalLongSymbol" SG_ 2030 TRCM_a140_frontRightAccelInitFai "TRCM_a140_frontRightAccelInitFailure";
BA_ "SystemSignalLongSymbol" SG_ 2030 TRCM_a141_frontRightAccelShortTo "TRCM_a141_frontRightAccelShortToGround";
BA_ "SystemSignalLongSymbol" SG_ 2030 TRCM_a142_frontRightAccelShortTo "TRCM_a142_frontRightAccelShortToBattery";
BA_ "SystemSignalLongSymbol" SG_ 2030 TRCM_a143_frontRightAccelConfigE "TRCM_a143_frontRightAccelConfigError";
BA_ "SystemSignalLongSymbol" SG_ 2030 TRCM_a145_frontRightAccelCommErr "TRCM_a145_frontRightAccelCommError";
BA_ "SystemSignalLongSymbol" SG_ 2030 TRCM_a146_frontRightAccelSensorD "TRCM_a146_frontRightAccelSensorDefect";
BA_ "SystemSignalLongSymbol" SG_ 2030 TRCM_a147_frontRightAccelSignalM "TRCM_a147_frontRightAccelSignalMonitor";
BA_ "SystemSignalLongSymbol" SG_ 2030 TRCM_a150_rightFrontDoorPressure "TRCM_a150_rightFrontDoorPressureInitFailure";
BA_ "SystemSignalLongSymbol" SG_ 2030 TRCM_a151_rightFrontDoorPressure "TRCM_a151_rightFrontDoorPressureShortToGround";
BA_ "SystemSignalLongSymbol" SG_ 2030 TRCM_a152_rightFrontDoorPressure "TRCM_a152_rightFrontDoorPressureShortToBattery";
BA_ "SystemSignalLongSymbol" SG_ 2030 TRCM_a153_rightFrontDoorPressure "TRCM_a153_rightFrontDoorPressureConfigError";
BA_ "SystemSignalLongSymbol" SG_ 2030 TRCM_a154_rightFrontDoorPressure "TRCM_a154_rightFrontDoorPressureOpen";
BA_ "SystemSignalLongSymbol" SG_ 2030 TRCM_a155_rightFrontDoorPressure "TRCM_a155_rightFrontDoorPressureCommError";
BA_ "SystemSignalLongSymbol" SG_ 2030 TRCM_a156_rightFrontDoorPressure "TRCM_a156_rightFrontDoorPressureSensorDefect";
BA_ "SystemSignalLongSymbol" SG_ 2030 TRCM_a157_rightFrontDoorPressure "TRCM_a157_rightFrontDoorPressureSignalMonitor";
BA_ "SystemSignalLongSymbol" SG_ 2030 TRCM_a160_frontLeftAccelInitFail "TRCM_a160_frontLeftAccelInitFailure";
BA_ "SystemSignalLongSymbol" SG_ 2030 TRCM_a161_frontLeftAccelShortToG "TRCM_a161_frontLeftAccelShortToGround";
BA_ "SystemSignalLongSymbol" SG_ 2030 TRCM_a162_frontLeftAccelShortToB "TRCM_a162_frontLeftAccelShortToBattery";
BA_ "SystemSignalLongSymbol" SG_ 2030 TRCM_a163_frontLeftAccelConfigEr "TRCM_a163_frontLeftAccelConfigError";
BA_ "SystemSignalLongSymbol" SG_ 2030 TRCM_a165_frontLeftAccelCommErro "TRCM_a165_frontLeftAccelCommError";
BA_ "SystemSignalLongSymbol" SG_ 2030 TRCM_a166_frontLeftAccelSensorDe "TRCM_a166_frontLeftAccelSensorDefect";
BA_ "SystemSignalLongSymbol" SG_ 2030 TRCM_a167_frontLeftAccelSignalMo "TRCM_a167_frontLeftAccelSignalMonitor";
BA_ "SystemSignalLongSymbol" SG_ 2030 TRCM_a170_leftFrontDoorPressureI "TRCM_a170_leftFrontDoorPressureInitFailure";
BA_ "SystemSignalLongSymbol" SG_ 2030 TRCM_a171_leftFrontDoorPressureS "TRCM_a171_leftFrontDoorPressureShortToGround";
BA_ "SystemSignalLongSymbol" SG_ 2030 TRCM_a172_leftFrontDoorPressureS "TRCM_a172_leftFrontDoorPressureShortToBattery";
BA_ "SystemSignalLongSymbol" SG_ 2030 TRCM_a173_leftFrontDoorPressureC "TRCM_a173_leftFrontDoorPressureConfigError";
BA_ "SystemSignalLongSymbol" SG_ 2030 TRCM_a174_leftFrontDoorPressureO "TRCM_a174_leftFrontDoorPressureOpen";
BA_ "SystemSignalLongSymbol" SG_ 2030 TRCM_a175_leftFrontDoorPressureC "TRCM_a175_leftFrontDoorPressureCommError";
BA_ "SystemSignalLongSymbol" SG_ 2030 TRCM_a176_leftFrontDoorPressureS "TRCM_a176_leftFrontDoorPressureSensorDefect";
BA_ "SystemSignalLongSymbol" SG_ 2030 TRCM_a177_leftFrontDoorPressureS "TRCM_a177_leftFrontDoorPressureSignalMonitor";
BA_ "SystemSignalLongSymbol" SG_ 2030 TRCM_a180_rightBPillarAccelInitF "TRCM_a180_rightBPillarAccelInitFailure";
BA_ "SystemSignalLongSymbol" SG_ 2030 TRCM_a181_rightBPillarAccelShort "TRCM_a181_rightBPillarAccelShortToGround";
BA_ "SystemSignalLongSymbol" SG_ 2030 TRCM_a182_rightBPillarAccelShort "TRCM_a182_rightBPillarAccelShortToBattery";
BA_ "SystemSignalLongSymbol" SG_ 2030 TRCM_a183_rightBPillarAccelConfi "TRCM_a183_rightBPillarAccelConfigError";
BA_ "SystemSignalLongSymbol" SG_ 2030 TRCM_a185_rightBPillarAccelCommE "TRCM_a185_rightBPillarAccelCommError";
BA_ "SystemSignalLongSymbol" SG_ 2030 TRCM_a186_rightBPillarAccelSenso "TRCM_a186_rightBPillarAccelSensorDefect";
BA_ "SystemSignalLongSymbol" SG_ 2030 TRCM_a187_rightBPillarAccelSigna "TRCM_a187_rightBPillarAccelSignalMonitor";
BA_ "SystemSignalLongSymbol" SG_ 2030 TRCM_a190_leftBPillarAccelInitFa "TRCM_a190_leftBPillarAccelInitFailure";
BA_ "SystemSignalLongSymbol" SG_ 2030 TRCM_a191_leftBPillarAccelShortT "TRCM_a191_leftBPillarAccelShortToGround";
BA_ "SystemSignalLongSymbol" SG_ 2030 TRCM_a192_leftBPillarAccelShortT "TRCM_a192_leftBPillarAccelShortToBattery";
BA_ "SystemSignalLongSymbol" SG_ 2030 TRCM_a193_leftBPillarAccelConfig "TRCM_a193_leftBPillarAccelConfigError";
BA_ "SystemSignalLongSymbol" SG_ 2030 TRCM_a195_leftBPillarAccelCommEr "TRCM_a195_leftBPillarAccelCommError";
BA_ "SystemSignalLongSymbol" SG_ 2030 TRCM_a196_leftBPillarAccelSensor "TRCM_a196_leftBPillarAccelSensorDefect";
BA_ "SystemSignalLongSymbol" SG_ 2030 TRCM_a197_leftBPillarAccelSignal "TRCM_a197_leftBPillarAccelSignalMonitor";
BA_ "SystemSignalLongSymbol" SG_ 2030 TRCM_a200_frontCenterAccelInitFa "TRCM_a200_frontCenterAccelInitFailure";
BA_ "SystemSignalLongSymbol" SG_ 2030 TRCM_a201_frontCenterAccelShortT "TRCM_a201_frontCenterAccelShortToGround";
BA_ "SystemSignalLongSymbol" SG_ 2030 TRCM_a202_frontCenterAccelShortT "TRCM_a202_frontCenterAccelShortToBattery";
BA_ "SystemSignalLongSymbol" SG_ 2030 TRCM_a203_frontCenterAccelConfig "TRCM_a203_frontCenterAccelConfigError";
BA_ "SystemSignalLongSymbol" SG_ 2030 TRCM_a205_frontCenterAccelCommEr "TRCM_a205_frontCenterAccelCommError";
BA_ "SystemSignalLongSymbol" SG_ 2030 TRCM_a206_frontCenterAccelSensor "TRCM_a206_frontCenterAccelSensorDefect";
BA_ "SystemSignalLongSymbol" SG_ 2030 TRCM_a207_frontCenterAccelSignal "TRCM_a207_frontCenterAccelSignalMonitor";
BA_ "SystemSignalLongSymbol" SG_ 2030 TRCM_a210_leftCPillarAccelInitFa "TRCM_a210_leftCPillarAccelInitFailure";
BA_ "SystemSignalLongSymbol" SG_ 2030 TRCM_a211_leftCPillarAccelShortT "TRCM_a211_leftCPillarAccelShortToGround";
BA_ "SystemSignalLongSymbol" SG_ 2030 TRCM_a212_leftCPillarAccelShortT "TRCM_a212_leftCPillarAccelShortToBattery";
BA_ "SystemSignalLongSymbol" SG_ 2030 TRCM_a213_leftCPillarAccelConfig "TRCM_a213_leftCPillarAccelConfigError";
BA_ "SystemSignalLongSymbol" SG_ 2030 TRCM_a215_leftCPillarAccelCommEr "TRCM_a215_leftCPillarAccelCommError";
BA_ "SystemSignalLongSymbol" SG_ 2030 TRCM_a216_leftCPillarAccelSensor "TRCM_a216_leftCPillarAccelSensorDefect";
BA_ "SystemSignalLongSymbol" SG_ 2030 TRCM_a217_leftCPillarAccelSignal "TRCM_a217_leftCPillarAccelSignalMonitor";
BA_ "SystemSignalLongSymbol" SG_ 2030 TRCM_a220_rightCPillarAccelInitF "TRCM_a220_rightCPillarAccelInitFailure";
BA_ "SystemSignalLongSymbol" SG_ 2030 TRCM_a221_rightCPillarAccelShort "TRCM_a221_rightCPillarAccelShortToGround";
BA_ "SystemSignalLongSymbol" SG_ 2030 TRCM_a222_rightCPillarAccelShort "TRCM_a222_rightCPillarAccelShortToBattery";
BA_ "SystemSignalLongSymbol" SG_ 2030 TRCM_a223_rightCPillarAccelConfi "TRCM_a223_rightCPillarAccelConfigError";
BA_ "SystemSignalLongSymbol" SG_ 2030 TRCM_a225_rightCPillarAccelCommE "TRCM_a225_rightCPillarAccelCommError";
BA_ "SystemSignalLongSymbol" SG_ 2030 TRCM_a226_rightCPillarAccelSenso "TRCM_a226_rightCPillarAccelSensorDefect";
BA_ "SystemSignalLongSymbol" SG_ 2030 TRCM_a227_rightCPillarAccelSigna "TRCM_a227_rightCPillarAccelSignalMonitor";
BA_ "SystemSignalLongSymbol" SG_ 2030 TRCM_a230_leftRearDoorPressureIn "TRCM_a230_leftRearDoorPressureInitFailure";
BA_ "SystemSignalLongSymbol" SG_ 2030 TRCM_a231_leftRearDoorPressureSh "TRCM_a231_leftRearDoorPressureShortToGround";
BA_ "SystemSignalLongSymbol" SG_ 2030 TRCM_a232_leftRearDoorPressureSh "TRCM_a232_leftRearDoorPressureShortToBattery";
BA_ "SystemSignalLongSymbol" SG_ 2030 TRCM_a233_leftRearDoorPressureCo "TRCM_a233_leftRearDoorPressureConfigError";
BA_ "SystemSignalLongSymbol" SG_ 2030 TRCM_a234_leftRearDoorPressureOp "TRCM_a234_leftRearDoorPressureOpen";
BA_ "SystemSignalLongSymbol" SG_ 2030 TRCM_a235_leftRearDoorPressureCo "TRCM_a235_leftRearDoorPressureCommError";
BA_ "SystemSignalLongSymbol" SG_ 2030 TRCM_a236_leftRearDoorPressureSe "TRCM_a236_leftRearDoorPressureSensorDefect";
BA_ "SystemSignalLongSymbol" SG_ 2030 TRCM_a237_leftRearDoorPressureSi "TRCM_a237_leftRearDoorPressureSignalMonitor";
BA_ "SystemSignalLongSymbol" SG_ 2030 TRCM_a240_rightRearDoorPressureI "TRCM_a240_rightRearDoorPressureInitFailure";
BA_ "SystemSignalLongSymbol" SG_ 2030 TRCM_a241_rightRearDoorPressureS "TRCM_a241_rightRearDoorPressureShortToGround";
BA_ "SystemSignalLongSymbol" SG_ 2030 TRCM_a242_rightRearDoorPressureS "TRCM_a242_rightRearDoorPressureShortToBattery";
BA_ "SystemSignalLongSymbol" SG_ 2030 TRCM_a243_rightRearDoorPressureC "TRCM_a243_rightRearDoorPressureConfigError";
BA_ "SystemSignalLongSymbol" SG_ 2030 TRCM_a244_rightRearDoorPressureO "TRCM_a244_rightRearDoorPressureOpen";
BA_ "SystemSignalLongSymbol" SG_ 2030 TRCM_a245_rightRearDoorPressureC "TRCM_a245_rightRearDoorPressureCommError";
BA_ "SystemSignalLongSymbol" SG_ 2030 TRCM_a246_rightRearDoorPressureS "TRCM_a246_rightRearDoorPressureSensorDefect";
BA_ "SystemSignalLongSymbol" SG_ 2030 TRCM_a247_rightRearDoorPressureS "TRCM_a247_rightRearDoorPressureSignalMonitor";
BA_ "SystemSignalLongSymbol" SG_ 2030 TRCM_a250_frontCenterAccelXInitF "TRCM_a250_frontCenterAccelXInitFailure";
BA_ "SystemSignalLongSymbol" SG_ 2030 TRCM_a251_frontCenterAccelXShort "TRCM_a251_frontCenterAccelXShortToGround";
BA_ "SystemSignalLongSymbol" SG_ 2030 TRCM_a252_frontCenterAccelXShort "TRCM_a252_frontCenterAccelXShortToBattery";
BA_ "SystemSignalLongSymbol" SG_ 2030 TRCM_a253_frontCenterAccelXConfi "TRCM_a253_frontCenterAccelXConfigError";
BA_ "SystemSignalLongSymbol" SG_ 2030 TRCM_a255_frontCenterAccelXCommE "TRCM_a255_frontCenterAccelXCommError";
BA_ "SystemSignalLongSymbol" SG_ 2030 TRCM_a256_frontCenterAccelXSenso "TRCM_a256_frontCenterAccelXSensorDefect";
BA_ "SystemSignalLongSymbol" SG_ 2030 TRCM_a257_frontCenterAccelXSigna "TRCM_a257_frontCenterAccelXSignalMonitor";
BA_ "SystemSignalLongSymbol" SG_ 2030 TRCM_a260_frontCenterAccelYInitF "TRCM_a260_frontCenterAccelYInitFailure";
BA_ "SystemSignalLongSymbol" SG_ 2030 TRCM_a261_frontCenterAccelYShort "TRCM_a261_frontCenterAccelYShortToGround";
BA_ "SystemSignalLongSymbol" SG_ 2030 TRCM_a262_frontCenterAccelYShort "TRCM_a262_frontCenterAccelYShortToBattery";
BA_ "SystemSignalLongSymbol" SG_ 2030 TRCM_a263_frontCenterAccelYConfi "TRCM_a263_frontCenterAccelYConfigError";
BA_ "SystemSignalLongSymbol" SG_ 2030 TRCM_a265_frontCenterAccelYCommE "TRCM_a265_frontCenterAccelYCommError";
BA_ "SystemSignalLongSymbol" SG_ 2030 TRCM_a266_frontCenterAccelYSenso "TRCM_a266_frontCenterAccelYSensorDefect";
BA_ "SystemSignalLongSymbol" SG_ 2030 TRCM_a267_frontCenterAccelYSigna "TRCM_a267_frontCenterAccelYSignalMonitor";
BA_ "SystemSignalLongSymbol" SG_ 2030 TRCM_a300_unarmedAB1FPDeployComm "TRCM_a300_unarmedAB1FPDeployCommand";
BA_ "SystemSignalLongSymbol" SG_ 2030 TRCM_a301_unarmedAB1FDDeployComm "TRCM_a301_unarmedAB1FDDeployCommand";
BA_ "SystemSignalLongSymbol" SG_ 2030 TRCM_a302_unarmedAV1FPDeployComm "TRCM_a302_unarmedAV1FPDeployCommand";
BA_ "SystemSignalLongSymbol" SG_ 2030 TRCM_a303_unarmedFSABDeployComma "TRCM_a303_unarmedFSABDeployCommand";
BA_ "SystemSignalLongSymbol" SG_ 2030 TRCM_a304_unarmedAB2FPDeployComm "TRCM_a304_unarmedAB2FPDeployCommand";
BA_ "SystemSignalLongSymbol" SG_ 2030 TRCM_a305_unarmedAB2FDDeployComm "TRCM_a305_unarmedAB2FDDeployCommand";
BA_ "SystemSignalLongSymbol" SG_ 2030 TRCM_a306_unarmedAV1FDDeployComm "TRCM_a306_unarmedAV1FDDeployCommand";
BA_ "SystemSignalLongSymbol" SG_ 2030 TRCM_a307_unarmedLoop7DeployComm "TRCM_a307_unarmedLoop7DeployCommand";
BA_ "SystemSignalLongSymbol" SG_ 2030 TRCM_a308_unarmedKA1FPDeployComm "TRCM_a308_unarmedKA1FPDeployCommand";
BA_ "SystemSignalLongSymbol" SG_ 2030 TRCM_a309_unarmedKA1FDDeployComm "TRCM_a309_unarmedKA1FDDeployCommand";
BA_ "SystemSignalLongSymbol" SG_ 2030 TRCM_a310_unarmedALLFRDeployComm "TRCM_a310_unarmedALLFRDeployCommand";
BA_ "SystemSignalLongSymbol" SG_ 2030 TRCM_a311_unarmedALLFLDeployComm "TRCM_a311_unarmedALLFLDeployCommand";
BA_ "SystemSignalLongSymbol" SG_ 2030 TRCM_a312_unarmedBT2FRDeployComm "TRCM_a312_unarmedBT2FRDeployCommand";
BA_ "SystemSignalLongSymbol" SG_ 2030 TRCM_a313_unarmedBT2FLDeployComm "TRCM_a313_unarmedBT2FLDeployCommand";
BA_ "SystemSignalLongSymbol" SG_ 2030 TRCM_a314_unarmedSA1FLDeployComm "TRCM_a314_unarmedSA1FLDeployCommand";
BA_ "SystemSignalLongSymbol" SG_ 2030 TRCM_a315_unarmedSA1FRDeployComm "TRCM_a315_unarmedSA1FRDeployCommand";
BA_ "SystemSignalLongSymbol" SG_ 2030 TRCM_a316_unarmedBT1RRDeployComm "TRCM_a316_unarmedBT1RRDeployCommand";
BA_ "SystemSignalLongSymbol" SG_ 2030 TRCM_a317_unarmedBT1RLDeployComm "TRCM_a317_unarmedBT1RLDeployCommand";
BA_ "SystemSignalLongSymbol" SG_ 2030 TRCM_a318_unarmedBT1FRDeployComm "TRCM_a318_unarmedBT1FRDeployCommand";
BA_ "SystemSignalLongSymbol" SG_ 2030 TRCM_a319_unarmedBT1FLDeployComm "TRCM_a319_unarmedBT1FLDeployCommand";
BA_ "SystemSignalLongSymbol" SG_ 2030 TRCM_a320_unarmedLoop20DeployCom "TRCM_a320_unarmedLoop20DeployCommand";
BA_ "SystemSignalLongSymbol" SG_ 2030 TRCM_a321_unarmedLoop21DeployCom "TRCM_a321_unarmedLoop21DeployCommand";
BA_ "SystemSignalLongSymbol" SG_ 2030 TRCM_a322_unarmedIC1FRDeployComm "TRCM_a322_unarmedIC1FRDeployCommand";
BA_ "SystemSignalLongSymbol" SG_ 2030 TRCM_a323_unarmedIC1FLDeployComm "TRCM_a323_unarmedIC1FLDeployCommand";
BA_ "SystemSignalLongSymbol" SG_ 2030 TRCM_a324_unarmedLoop24DeployCom "TRCM_a324_unarmedLoop24DeployCommand";
BA_ "SystemSignalLongSymbol" SG_ 2030 TRCM_a325_unarmedLoop25DeployCom "TRCM_a325_unarmedLoop25DeployCommand";
BA_ "SystemSignalLongSymbol" SG_ 2030 TRCM_a326_unarmedLoop26DeployCom "TRCM_a326_unarmedLoop26DeployCommand";
BA_ "SystemSignalLongSymbol" SG_ 2030 TRCM_a327_unarmedLoop27DeployCom "TRCM_a327_unarmedLoop27DeployCommand";
BA_ "SystemSignalLongSymbol" SG_ 2030 TRCM_a328_unarmedLoop28DeployCom "TRCM_a328_unarmedLoop28DeployCommand";
BA_ "SystemSignalLongSymbol" SG_ 2030 TRCM_a329_unarmedLoop29DeployCom "TRCM_a329_unarmedLoop29DeployCommand";
BA_ "SystemSignalLongSymbol" SG_ 2030 TRCM_a330_unarmedLoop30DeployCom "TRCM_a330_unarmedLoop30DeployCommand";
BA_ "SystemSignalLongSymbol" SG_ 2030 TRCM_a331_unarmedLoop31DeployCom "TRCM_a331_unarmedLoop31DeployCommand";
BA_ "SystemSignalLongSymbol" SG_ 2030 TRCM_a364_safingEngine0NoValidDa "TRCM_a364_safingEngine0NoValidData";
BA_ "SystemSignalLongSymbol" SG_ 2030 TRCM_a365_safingEngine1NoValidDa "TRCM_a365_safingEngine1NoValidData";
BA_ "SystemSignalLongSymbol" SG_ 2030 TRCM_a366_safingEngine2NoValidDa "TRCM_a366_safingEngine2NoValidData";
BA_ "SystemSignalLongSymbol" SG_ 2030 TRCM_a367_safingEngine3NoValidDa "TRCM_a367_safingEngine3NoValidData";
BA_ "SystemSignalLongSymbol" SG_ 2030 TRCM_a368_safingEngine4NoValidDa "TRCM_a368_safingEngine4NoValidData";
BA_ "SystemSignalLongSymbol" SG_ 2030 TRCM_a369_safingEngine5NoValidDa "TRCM_a369_safingEngine5NoValidData";
BA_ "SystemSignalLongSymbol" SG_ 2030 TRCM_a370_safingEngine6NoValidDa "TRCM_a370_safingEngine6NoValidData";
BA_ "SystemSignalLongSymbol" SG_ 2030 TRCM_a371_safingEngine7NoValidDa "TRCM_a371_safingEngine7NoValidData";
BA_ "SystemSignalLongSymbol" SG_ 2030 TRCM_a372_safingEngine8NoValidDa "TRCM_a372_safingEngine8NoValidData";
BA_ "SystemSignalLongSymbol" SG_ 2030 TRCM_a373_safingEngine9NoValidDa "TRCM_a373_safingEngine9NoValidData";
BA_ "SystemSignalLongSymbol" SG_ 2030 TRCM_a374_safingEngine10NoValidD "TRCM_a374_safingEngine10NoValidData";
BA_ "SystemSignalLongSymbol" SG_ 2030 TRCM_a375_safingEngine11NoValidD "TRCM_a375_safingEngine11NoValidData";
BA_ "SystemSignalLongSymbol" SG_ 2030 TRCM_a376_safingEngine12NoValidD "TRCM_a376_safingEngine12NoValidData";
BA_ "SystemSignalLongSymbol" SG_ 2030 TRCM_a377_safingEngine13NoValidD "TRCM_a377_safingEngine13NoValidData";
BA_ "SystemSignalLongSymbol" SG_ 2030 TRCM_a378_safingEngine14NoValidD "TRCM_a378_safingEngine14NoValidData";
BA_ "SystemSignalLongSymbol" SG_ 2030 TRCM_a379_safingEngine15NoValidD "TRCM_a379_safingEngine15NoValidData";
BA_ "SystemSignalLongSymbol" SG_ 2030 TRCM_a380_safingEngine16NoValidD "TRCM_a380_safingEngine16NoValidData";
BA_ "SystemSignalLongSymbol" SG_ 2030 TRCM_a381_safingEngine17NoValidD "TRCM_a381_safingEngine17NoValidData";
BA_ "SystemSignalLongSymbol" SG_ 2030 TRCM_a382_safingEngine18NoValidD "TRCM_a382_safingEngine18NoValidData";
BA_ "SystemSignalLongSymbol" SG_ 2030 TRCM_a383_safingEngine19NoValidD "TRCM_a383_safingEngine19NoValidData";
BA_ "SystemSignalLongSymbol" SG_ 2030 TRCM_a384_safingEngine20NoValidD "TRCM_a384_safingEngine20NoValidData";
BA_ "SystemSignalLongSymbol" SG_ 2030 TRCM_a385_safingEngine21NoValidD "TRCM_a385_safingEngine21NoValidData";
BA_ "SystemSignalLongSymbol" SG_ 2030 TRCM_a390_systemAsicClockOrOpera "TRCM_a390_systemAsicClockOrOperatingStateError";
BA_ "SystemSignalLongSymbol" SG_ 2030 TRCM_a391_extAsic1ClockOrOperati "TRCM_a391_extAsic1ClockOrOperatingStateError";
BA_ "SystemSignalLongSymbol" SG_ 2030 TRCM_a392_extAsic2ClockOrOperati "TRCM_a392_extAsic2ClockOrOperatingStateError";
BA_ "SystemSignalLongSymbol" SG_ 2030 TRCM_a393_depAdcConvertRatioErro "TRCM_a393_depAdcConvertRatioError";
BA_ "SystemSignalLongSymbol" SG_ 2030 TRCM_a394_gspiGlobalStatusWordEr "TRCM_a394_gspiGlobalStatusWordError";
BA_ "SystemSignalLongSymbol" SG_ 2030 TRCM_a396_spiCommunicationProgra "TRCM_a396_spiCommunicationProgramError";
BA_ "SystemSignalLongSymbol" SG_ 2030 TRCM_a460_BTRP_RetractorShortToG "TRCM_a460_BTRP_RetractorShortToGround";
BA_ "SystemSignalLongSymbol" SG_ 2030 TRCM_a461_BTRP_RetractorShortToB "TRCM_a461_BTRP_RetractorShortToBattery";
BA_ "SystemSignalLongSymbol" SG_ 2030 TRCM_a463_BTRP_RetractorShortToS "TRCM_a463_BTRP_RetractorShortToSelf";
BA_ "SystemSignalLongSymbol" SG_ 2030 TRCM_a464_BTRP_RetractorCrossCou "TRCM_a464_BTRP_RetractorCrossCoupled";
BA_ "SystemSignalLongSymbol" SG_ 2030 TRCM_a465_BTRP_RetractorConfigEr "TRCM_a465_BTRP_RetractorConfigError";
BA_ "SystemSignalLongSymbol" SG_ 2030 TRCM_a466_BTRD_RetractorShortToG "TRCM_a466_BTRD_RetractorShortToGround";
BA_ "SystemSignalLongSymbol" SG_ 2030 TRCM_a467_BTRD_RetractorShortToB "TRCM_a467_BTRD_RetractorShortToBattery";
BA_ "SystemSignalLongSymbol" SG_ 2030 TRCM_a469_BTRD_RetractorShortToS "TRCM_a469_BTRD_RetractorShortToSelf";
BA_ "SystemSignalLongSymbol" SG_ 2030 TRCM_a470_BTRD_RetractorCrossCou "TRCM_a470_BTRD_RetractorCrossCoupled";
BA_ "SystemSignalLongSymbol" SG_ 2030 TRCM_a471_BTRD_RetractorConfigEr "TRCM_a471_BTRD_RetractorConfigError";
BA_ "SystemSignalLongSymbol" SG_ 2030 TRCM_a496_BTRP_AnchorShortToGrou "TRCM_a496_BTRP_AnchorShortToGround";
BA_ "SystemSignalLongSymbol" SG_ 2030 TRCM_a497_BTRP_AnchorShortToBatt "TRCM_a497_BTRP_AnchorShortToBattery";
BA_ "SystemSignalLongSymbol" SG_ 2030 TRCM_a500_BTRP_AnchorCrossCouple "TRCM_a500_BTRP_AnchorCrossCoupled";
BA_ "SystemSignalLongSymbol" SG_ 2030 TRCM_a502_BTRD_AnchorShortToGrou "TRCM_a502_BTRD_AnchorShortToGround";
BA_ "SystemSignalLongSymbol" SG_ 2030 TRCM_a503_BTRD_AnchorShortToBatt "TRCM_a503_BTRD_AnchorShortToBattery";
BA_ "SystemSignalLongSymbol" SG_ 2030 TRCM_a506_BTRD_AnchorCrossCouple "TRCM_a506_BTRD_AnchorCrossCoupled";
BA_ "SystemSignalLongSymbol" SG_ 2030 TRCM_a545_erCapBelowAutarkyThres "TRCM_a545_erCapBelowAutarkyThreshold";
BA_ "SystemSignalLongSymbol" SG_ 2030 TRCM_a546_sensorValuesFaultedByS "TRCM_a546_sensorValuesFaultedBySmart";
BA_ "SystemSignalLongSymbol" SG_ 2030 TRCM_a550_AlgoWake_RCM_WAKE_FRON "TRCM_a550_AlgoWake_RCM_WAKE_FRONT";
BA_ "SystemSignalLongSymbol" SG_ 2030 TRCM_a553_AlgoWake_RCM_WAKE_RIGH "TRCM_a553_AlgoWake_RCM_WAKE_RIGHT";
BA_ "SystemSignalLongSymbol" SG_ 2030 TRCM_a554_AlgoWake_PAS_LH_PLAUSI "TRCM_a554_AlgoWake_PAS_LH_PLAUSI_FRONT";
BA_ "SystemSignalLongSymbol" SG_ 2030 TRCM_a555_AlgoWake_PAS_LH_PLAUSI "TRCM_a555_AlgoWake_PAS_LH_PLAUSI_REAR";
BA_ "SystemSignalLongSymbol" SG_ 2030 TRCM_a557_AlgoWake_PAS_RH_PLAUSI "TRCM_a557_AlgoWake_PAS_RH_PLAUSI_FRONT";
BA_ "SystemSignalLongSymbol" SG_ 2030 TRCM_a558_AlgoWake_PAS_RH_PLAUSI "TRCM_a558_AlgoWake_PAS_RH_PLAUSI_REAR";
BA_ "SystemSignalLongSymbol" SG_ 2030 TRCM_a560_AlgoWake_RCM_WAKE_ROLL "TRCM_a560_AlgoWake_RCM_WAKE_ROLL_LEFT";
BA_ "SystemSignalLongSymbol" SG_ 2030 TRCM_a561_AlgoWake_RCM_WAKE_ROLL "TRCM_a561_AlgoWake_RCM_WAKE_ROLL_RIGHT";
BA_ "SystemSignalLongSymbol" SG_ 2030 TRCM_a562_AlgoWake_RCM_AWAKE_FRO "TRCM_a562_AlgoWake_RCM_AWAKE_FRONT";
BA_ "SystemSignalLongSymbol" SG_ 2030 TRCM_a563_AlgoWake_RCM_AWAKE_REA "TRCM_a563_AlgoWake_RCM_AWAKE_REAR";
BA_ "SystemSignalLongSymbol" SG_ 2030 TRCM_a564_AlgoWake_RCM_AWAKE_LEF "TRCM_a564_AlgoWake_RCM_AWAKE_LEFT";
BA_ "SystemSignalLongSymbol" SG_ 2030 TRCM_a565_AlgoWake_RCM_AWAKE_RIG "TRCM_a565_AlgoWake_RCM_AWAKE_RIGHT";
BA_ "SystemSignalLongSymbol" SG_ 2030 TRCM_a566_AlgoWake_RCM_AWAKE_ROL "TRCM_a566_AlgoWake_RCM_AWAKE_ROLL";
BA_ "SystemSignalLongSymbol" SG_ 2030 TRCM_a569_AlgoWake_IMPACT_FINISH "TRCM_a569_AlgoWake_IMPACT_FINISH_X_FRONT";
BA_ "SystemSignalLongSymbol" SG_ 2030 TRCM_a570_AlgoWake_IMPACT_FINISH "TRCM_a570_AlgoWake_IMPACT_FINISH_X_REAR";
BA_ "SystemSignalLongSymbol" SG_ 2030 TRCM_a571_AlgoWake_IMPACT_FINISH "TRCM_a571_AlgoWake_IMPACT_FINISH_Y_RCM_POS";
BA_ "SystemSignalLongSymbol" SG_ 2030 TRCM_a572_AlgoWake_IMPACT_FINISH "TRCM_a572_AlgoWake_IMPACT_FINISH_Y_RCM_NEG";
BA_ "SystemSignalLongSymbol" SG_ 2030 TRCM_a573_AlgoWake_IMPACT_FINISH "TRCM_a573_AlgoWake_IMPACT_FINISH_Y_RCM";
BA_ "SystemSignalLongSymbol" SG_ 2030 TRCM_a574_AlgoWake_IMPACT_FINISH "TRCM_a574_AlgoWake_IMPACT_FINISH_ROLL_RIGHT";
BA_ "SystemSignalLongSymbol" SG_ 2030 TRCM_a575_AlgoWake_IMPACT_FINISH "TRCM_a575_AlgoWake_IMPACT_FINISH_ROLL_LEFT";
BA_ "SystemSignalLongSymbol" SG_ 2030 TRCM_a576_AlgoWake_IMPACT_FINISH "TRCM_a576_AlgoWake_IMPACT_FINISH_X";
BA_ "SystemSignalLongSymbol" SG_ 2030 TRCM_a577_AlgoWake_IMPACT_FINISH "TRCM_a577_AlgoWake_IMPACT_FINISH_Y";
BA_ "SystemSignalLongSymbol" SG_ 2030 TRCM_a578_AlgoWake_IMPACT_FINISH "TRCM_a578_AlgoWake_IMPACT_FINISH_ROLL";
BA_ "SystemSignalLongSymbol" SG_ 2030 TRCM_a581_AlgoWake_RCM_ENABLED_R "TRCM_a581_AlgoWake_RCM_ENABLED_ROLL";
BA_ "SystemSignalLongSymbol" SG_ 2030 TRCM_a590_pitchRateOffsetPosLimi "TRCM_a590_pitchRateOffsetPosLimit";
BA_ "SystemSignalLongSymbol" SG_ 2030 TRCM_a591_pitchRateOffsetNegLimi "TRCM_a591_pitchRateOffsetNegLimit";
BA_ "SystemSignalLongSymbol" SG_ 2030 TRCM_a594_longitudinalAccelOffse "TRCM_a594_longitudinalAccelOffsetPosLimit";
BA_ "SystemSignalLongSymbol" SG_ 2030 TRCM_a595_longitudinalAccelOffse "TRCM_a595_longitudinalAccelOffsetNegLimit";
BA_ "SystemSignalLongSymbol" SG_ 2030 TRCM_a596_lateralAccelOffsetPosL "TRCM_a596_lateralAccelOffsetPosLimit";
BA_ "SystemSignalLongSymbol" SG_ 2030 TRCM_a597_lateralAccelOffsetNegL "TRCM_a597_lateralAccelOffsetNegLimit";
BA_ "SystemSignalLongSymbol" SG_ 2030 TRCM_a598_verticalAccelOffsetPos "TRCM_a598_verticalAccelOffsetPosLimit";
BA_ "SystemSignalLongSymbol" SG_ 2030 TRCM_a599_verticalAccelOffsetNeg "TRCM_a599_verticalAccelOffsetNegLimit";
BA_ "SystemSignalLongSymbol" SG_ 2030 TRCM_a600_airbagAsicStartupFailu "TRCM_a600_airbagAsicStartupFailure";
BA_ "SystemSignalLongSymbol" SG_ 2030 TRCM_a601_loop0AsicStartupDiagno "TRCM_a601_loop0AsicStartupDiagnosticFailure";
BA_ "SystemSignalLongSymbol" SG_ 2030 TRCM_a602_loop1AsicStartupDiagno "TRCM_a602_loop1AsicStartupDiagnosticFailure";
BA_ "SystemSignalLongSymbol" SG_ 2030 TRCM_a603_loop2AsicStartupDiagno "TRCM_a603_loop2AsicStartupDiagnosticFailure";
BA_ "SystemSignalLongSymbol" SG_ 2030 TRCM_a604_loop3AsicStartupDiagno "TRCM_a604_loop3AsicStartupDiagnosticFailure";
BA_ "SystemSignalLongSymbol" SG_ 2030 TRCM_a605_loop4AsicStartupDiagno "TRCM_a605_loop4AsicStartupDiagnosticFailure";
BA_ "SystemSignalLongSymbol" SG_ 2030 TRCM_a606_loop5AsicStartupDiagno "TRCM_a606_loop5AsicStartupDiagnosticFailure";
BA_ "SystemSignalLongSymbol" SG_ 2030 TRCM_a607_loop6AsicStartupDiagno "TRCM_a607_loop6AsicStartupDiagnosticFailure";
BA_ "SystemSignalLongSymbol" SG_ 2030 TRCM_a608_loop7AsicStartupDiagno "TRCM_a608_loop7AsicStartupDiagnosticFailure";
BA_ "SystemSignalLongSymbol" SG_ 2030 TRCM_a609_loop8AsicStartupDiagno "TRCM_a609_loop8AsicStartupDiagnosticFailure";
BA_ "SystemSignalLongSymbol" SG_ 2030 TRCM_a610_loop9AsicStartupDiagno "TRCM_a610_loop9AsicStartupDiagnosticFailure";
BA_ "SystemSignalLongSymbol" SG_ 2030 TRCM_a611_loop10AsicStartupDiagn "TRCM_a611_loop10AsicStartupDiagnosticFailure";
BA_ "SystemSignalLongSymbol" SG_ 2030 TRCM_a612_loop11AsicStartupDiagn "TRCM_a612_loop11AsicStartupDiagnosticFailure";
BA_ "SystemSignalLongSymbol" SG_ 2030 TRCM_a613_loop12AsicStartupDiagn "TRCM_a613_loop12AsicStartupDiagnosticFailure";
BA_ "SystemSignalLongSymbol" SG_ 2030 TRCM_a614_loop13AsicStartupDiagn "TRCM_a614_loop13AsicStartupDiagnosticFailure";
BA_ "SystemSignalLongSymbol" SG_ 2030 TRCM_a615_loop14AsicStartupDiagn "TRCM_a615_loop14AsicStartupDiagnosticFailure";
BA_ "SystemSignalLongSymbol" SG_ 2030 TRCM_a616_loop15AsicStartupDiagn "TRCM_a616_loop15AsicStartupDiagnosticFailure";
BA_ "SystemSignalLongSymbol" SG_ 2030 TRCM_a617_loop16AsicStartupDiagn "TRCM_a617_loop16AsicStartupDiagnosticFailure";
BA_ "SystemSignalLongSymbol" SG_ 2030 TRCM_a618_loop17AsicStartupDiagn "TRCM_a618_loop17AsicStartupDiagnosticFailure";
BA_ "SystemSignalLongSymbol" SG_ 2030 TRCM_a619_loop18AsicStartupDiagn "TRCM_a619_loop18AsicStartupDiagnosticFailure";
BA_ "SystemSignalLongSymbol" SG_ 2030 TRCM_a620_loop19AsicStartupDiagn "TRCM_a620_loop19AsicStartupDiagnosticFailure";
BA_ "SystemSignalLongSymbol" SG_ 2030 TRCM_a621_loop20AsicStartupDiagn "TRCM_a621_loop20AsicStartupDiagnosticFailure";
BA_ "SystemSignalLongSymbol" SG_ 2030 TRCM_a622_loop21AsicStartupDiagn "TRCM_a622_loop21AsicStartupDiagnosticFailure";
BA_ "SystemSignalLongSymbol" SG_ 2030 TRCM_a623_loop22AsicStartupDiagn "TRCM_a623_loop22AsicStartupDiagnosticFailure";
BA_ "SystemSignalLongSymbol" SG_ 2030 TRCM_a624_loop23AsicStartupDiagn "TRCM_a624_loop23AsicStartupDiagnosticFailure";
BA_ "SystemSignalLongSymbol" SG_ 2030 TRCM_a625_loop24AsicStartupDiagn "TRCM_a625_loop24AsicStartupDiagnosticFailure";
BA_ "SystemSignalLongSymbol" SG_ 2030 TRCM_a626_loop25AsicStartupDiagn "TRCM_a626_loop25AsicStartupDiagnosticFailure";
BA_ "SystemSignalLongSymbol" SG_ 2030 TRCM_a627_loop26AsicStartupDiagn "TRCM_a627_loop26AsicStartupDiagnosticFailure";
BA_ "SystemSignalLongSymbol" SG_ 2030 TRCM_a628_loop27AsicStartupDiagn "TRCM_a628_loop27AsicStartupDiagnosticFailure";
BA_ "SystemSignalLongSymbol" SG_ 2030 TRCM_a629_loop28AsicStartupDiagn "TRCM_a629_loop28AsicStartupDiagnosticFailure";
BA_ "SystemSignalLongSymbol" SG_ 2030 TRCM_a630_loop29AsicStartupDiagn "TRCM_a630_loop29AsicStartupDiagnosticFailure";
BA_ "SystemSignalLongSymbol" SG_ 2030 TRCM_a631_loop30AsicStartupDiagn "TRCM_a631_loop30AsicStartupDiagnosticFailure";
BA_ "SystemSignalLongSymbol" SG_ 2030 TRCM_a632_loop31AsicStartupDiagn "TRCM_a632_loop31AsicStartupDiagnosticFailure";
BA_ "Confidence" SG_ 1641 UDS_KOSTIAsccmRequestData 1;
BA_ "Confidence" SG_ 1538 UDS_bmsRequestData 1;
BA_ "Confidence" SG_ 1579 UDS_ccRequestData 1;
BA_ "Confidence" SG_ 1539 UDS_cmpRequestData 1;
BA_ "Confidence" SG_ 1543 UDS_cmpdRequestData 1;
BA_ "Confidence" SG_ 1550 UDS_cpRequestData 1;
BA_ "Confidence" SG_ 1609 UDS_dasRequestData 1;
BA_ "Confidence" SG_ 1589 UDS_diRequestData 1;
BA_ "Confidence" SG_ 1541 UDS_difRequestData 1;
BA_ "Confidence" SG_ 1542 UDS_dirRequestData 1;
BA_ "Confidence" SG_ 1584 UDS_epas3pRequestData 1;
BA_ "Confidence" SG_ 1840 UDS_epas3sRequestData 1;
BA_ "Confidence" SG_ 1572 UDS_epblRequestData_H 1;
BA_ "Confidence" SG_ 1572 UDS_epblRequestData_L 1;
BA_ "Confidence" SG_ 1574 UDS_epbrRequestData_H 1;
BA_ "Confidence" SG_ 1574 UDS_epbrRequestData_L 1;
BA_ "Confidence" SG_ 1605 UDS_espRequestData 1;
BA_ "Confidence" SG_ 2015 UDS_functionalRequestData_0 1;
BA_ "Confidence" SG_ 2015 UDS_functionalRequestData_1 1;
BA_ "Confidence" SG_ 2015 UDS_functionalRequestData_2 1;
BA_ "Confidence" SG_ 2015 UDS_functionalRequestData_3 1;
BA_ "Confidence" SG_ 2015 UDS_functionalRequestData_4 1;
BA_ "Confidence" SG_ 2015 UDS_functionalRequestData_5 1;
BA_ "Confidence" SG_ 2015 UDS_functionalRequestData_6 1;
BA_ "Confidence" SG_ 2015 UDS_functionalRequestData_7 1;
BA_ "Confidence" SG_ 2014 UDS_functionalRequestDataCH 1;
BA_ "Confidence" SG_ 1552 UDS_hvpRequestData 1;
BA_ "Confidence" SG_ 1613 UDS_ibstRequestData 1;
VAL_ 1298 TRCM_alertID 632 "a632_loop31AsicStartupDiagnosticFailure" 631 "a631_loop30AsicStartupDiagnosticFailure" 630 "a630_loop29AsicStartupDiagnosticFailure" 629 "a629_loop28AsicStartupDiagnosticFailure" 628 "a628_loop27AsicStartupDiagnosticFailure" 627 "a627_loop26AsicStartupDiagnosticFailure" 626 "a626_loop25AsicStartupDiagnosticFailure" 625 "a625_loop24AsicStartupDiagnosticFailure" 624 "a624_loop23AsicStartupDiagnosticFailure" 623 "a623_loop22AsicStartupDiagnosticFailure" 622 "a622_loop21AsicStartupDiagnosticFailure" 621 "a621_loop20AsicStartupDiagnosticFailure" 620 "a620_loop19AsicStartupDiagnosticFailure" 619 "a619_loop18AsicStartupDiagnosticFailure" 618 "a618_loop17AsicStartupDiagnosticFailure" 617 "a617_loop16AsicStartupDiagnosticFailure" 616 "a616_loop15AsicStartupDiagnosticFailure" 615 "a615_loop14AsicStartupDiagnosticFailure" 614 "a614_loop13AsicStartupDiagnosticFailure" 613 "a613_loop12AsicStartupDiagnosticFailure" 612 "a612_loop11AsicStartupDiagnosticFailure" 611 "a611_loop10AsicStartupDiagnosticFailure" 610 "a610_loop9AsicStartupDiagnosticFailure" 609 "a609_loop8AsicStartupDiagnosticFailure" 608 "a608_loop7AsicStartupDiagnosticFailure" 607 "a607_loop6AsicStartupDiagnosticFailure" 606 "a606_loop5AsicStartupDiagnosticFailure" 605 "a605_loop4AsicStartupDiagnosticFailure" 604 "a604_loop3AsicStartupDiagnosticFailure" 603 "a603_loop2AsicStartupDiagnosticFailure" 602 "a602_loop1AsicStartupDiagnosticFailure" 601 "a601_loop0AsicStartupDiagnosticFailure" 600 "a600_airbagAsicStartupFailure" 599 "a599_verticalAccelOffsetNegLimit" 598 "a598_verticalAccelOffsetPosLimit" 597 "a597_lateralAccelOffsetNegLimit" 596 "a596_lateralAccelOffsetPosLimit" 595 "a595_longitudinalAccelOffsetNegLimit" 594 "a594_longitudinalAccelOffsetPosLimit" 593 "a593_rollRateOffsetNegLimit" 592 "a592_rollRateOffsetPosLimit" 591 "a591_pitchRateOffsetNegLimit" 590 "a590_pitchRateOffsetPosLimit" 589 "a589_yawRateOffsetNegLimit" 588 "a588_yawRateOffsetPosLimit" 582 "a582_AlgoWake_RCM_AWAKE" 581 "a581_AlgoWake_RCM_ENABLED_ROLL" 580 "a580_AlgoWake_RCM_ENABLED_Y" 579 "a579_AlgoWake_RCM_ENABLED_X" 578 "a578_AlgoWake_IMPACT_FINISH_ROLL" 577 "a577_AlgoWake_IMPACT_FINISH_Y" 576 "a576_AlgoWake_IMPACT_FINISH_X" 575 "a575_AlgoWake_IMPACT_FINISH_ROLL_LEFT" 574 "a574_AlgoWake_IMPACT_FINISH_ROLL_RIGHT" 573 "a573_AlgoWake_IMPACT_FINISH_Y_RCM" 572 "a572_AlgoWake_IMPACT_FINISH_Y_RCM_NEG" 571 "a571_AlgoWake_IMPACT_FINISH_Y_RCM_POS" 570 "a570_AlgoWake_IMPACT_FINISH_X_REAR" 569 "a569_AlgoWake_IMPACT_FINISH_X_FRONT" 568 "a568_AlgoWake_RCM_AWAKE_Y" 567 "a567_AlgoWake_RCM_AWAKE_X" 566 "a566_AlgoWake_RCM_AWAKE_ROLL" 565 "a565_AlgoWake_RCM_AWAKE_RIGHT" 564 "a564_AlgoWake_RCM_AWAKE_LEFT" 563 "a563_AlgoWake_RCM_AWAKE_REAR" 562 "a562_AlgoWake_RCM_AWAKE_FRONT" 561 "a561_AlgoWake_RCM_WAKE_ROLL_RIGHT" 560 "a560_AlgoWake_RCM_WAKE_ROLL_LEFT" 559 "a559_AlgoWake_PAS_RH_PLAUSI" 558 "a558_AlgoWake_PAS_RH_PLAUSI_REAR" 557 "a557_AlgoWake_PAS_RH_PLAUSI_FRONT" 556 "a556_AlgoWake_PAS_LH_PLAUSI" 555 "a555_AlgoWake_PAS_LH_PLAUSI_REAR" 554 "a554_AlgoWake_PAS_LH_PLAUSI_FRONT" 553 "a553_AlgoWake_RCM_WAKE_RIGHT" 552 "a552_AlgoWake_RCM_WAKE_LEFT" 551 "a551_AlgoWake_RCM_WAKE_REAR" 550 "a550_AlgoWake_RCM_WAKE_FRONT" 546 "a546_sensorValuesFaultedBySmart" 545 "a545_erCapBelowAutarkyThreshold" 544 "a544_erCapDiagnosticsFailed" 525 "a525_FSABConfigError" 524 "a524_FSABCrossCoupled" 523 "a523_FSABShortToSelf" 522 "a522_FSABOpen" 521 "a521_FSABShortToBattery" 520 "a520_FSABShortToGround" 519 "a519_IC1FLConfigError" 518 "a518_IC1FLCrossCoupled" 517 "a517_IC1FLShortToSelf" 516 "a516_IC1FLOpen" 515 "a515_IC1FLShortToBattery" 514 "a514_IC1FLShortToGround" 513 "a513_IC1FRConfigError" 512 "a512_IC1FRCrossCoupled" 511 "a511_IC1FRShortToSelf" 510 "a510_IC1FROpen" 509 "a509_IC1FRShortToBattery" 508 "a508_IC1FRShortToGround" 507 "a507_BTRD_AnchorConfigError" 506 "a506_BTRD_AnchorCrossCoupled" 505 "a505_BTRD_AnchorShortToSelf" 504 "a504_BTRD_AnchorOpen" 503 "a503_BTRD_AnchorShortToBattery" 502 "a502_BTRD_AnchorShortToGround" 501 "a501_BTRP_AnchorConfigError" 500 "a500_BTRP_AnchorCrossCoupled" 499 "a499_BTRP_AnchorShortToSelf" 498 "a498_BTRP_AnchorOpen" 497 "a497_BTRP_AnchorShortToBattery" 496 "a496_BTRP_AnchorShortToGround" 495 "a495_BTRLConfigError" 494 "a494_BTRLCrossCoupled" 493 "a493_BTRLShortToSelf" 492 "a492_BTRLOpen" 491 "a491_BTRLShortToBattery" 490 "a490_BTRLShortToGround" 489 "a489_BTRRConfigError" 488 "a488_BTRRCrossCoupled" 487 "a487_BTRRShortToSelf" 486 "a486_BTRROpen" 485 "a485_BTRRShortToBattery" 484 "a484_BTRRShortToGround" 483 "a483_SA1FRConfigError" 482 "a482_SA1FRCrossCoupled" 481 "a481_SA1FRShortToSelf" 480 "a480_SA1FROpen" 479 "a479_SA1FRShortToBattery" 478 "a478_SA1FRShortToGround" 477 "a477_SA1FLConfigError" 476 "a476_SA1FLCrossCoupled" 475 "a475_SA1FLShortToSelf" 474 "a474_SA1FLOpen" 473 "a473_SA1FLShortToBattery" 472 "a472_SA1FLShortToGround" 471 "a471_BTRD_RetractorConfigError" 470 "a470_BTRD_RetractorCrossCoupled" 469 "a469_BTRD_RetractorShortToSelf" 468 "a468_BTRD_RetractorOpen" 467 "a467_BTRD_RetractorShortToBattery" 466 "a466_BTRD_RetractorShortToGround" 465 "a465_BTRP_RetractorConfigError" 464 "a464_BTRP_RetractorCrossCoupled" 463 "a463_BTRP_RetractorShortToSelf" 462 "a462_BTRP_RetractorOpen" 461 "a461_BTRP_RetractorShortToBattery" 460 "a460_BTRP_RetractorShortToGround" 459 "a459_DLLConfigError" 458 "a458_DLLCrossCoupled" 457 "a457_DLLShortToSelf" 456 "a456_DLLOpen" 455 "a455_DLLShortToBattery" 454 "a454_DLLShortToGround" 453 "a453_PLLConfigError" 452 "a452_PLLCrossCoupled" 451 "a451_PLLShortToSelf" 450 "a450_PLLOpen" 449 "a449_PLLShortToBattery" 448 "a448_PLLShortToGround" 447 "a447_IKBFDConfigError" 446 "a446_IKBFDCrossCoupled" 445 "a445_IKBFDShortToSelf" 444 "a444_IKBFDOpen" 443 "a443_IKBFDShortToBattery" 442 "a442_IKBFDShortToGround" 441 "a441_IKBFPConfigError" 440 "a440_IKBFPCrossCoupled" 439 "a439_IKBFPShortToSelf" 438 "a438_IKBFPOpen" 437 "a437_IKBFPShortToBattery" 436 "a436_IKBFPShortToGround" 435 "a435_DAVConfigError" 434 "a434_DAVCrossCoupled" 433 "a433_DAVShortToSelf" 432 "a432_DAVOpen" 431 "a431_DAVShortToBattery" 430 "a430_DAVShortToGround" 429 "a429_AB2FDConfigError" 428 "a428_AB2FDCrossCoupled" 427 "a427_AB2FDShortToSelf" 426 "a426_AB2FDOpen" 425 "a425_AB2FDShortToBattery" 424 "a424_AB2FDShortToGround" 423 "a423_AB2FPConfigError" 422 "a422_AB2FPCrossCoupled" 421 "a421_AB2FPShortToSelf" 420 "a420_AB2FPOpen" 419 "a419_AB2FPShortToBattery" 418 "a418_AB2FPShortToGround" 417 "a417_PAVConfigError" 416 "a416_PAVCrossCoupled" 415 "a415_PAVShortToSelf" 414 "a414_PAVOpen" 413 "a413_PAVShortToBattery" 412 "a412_PAVShortToGround" 411 "a411_AB1FDConfigError" 410 "a410_AB1FDCrossCoupled" 409 "a409_AB1FDShortToSelf" 408 "a408_AB1FDOpen" 407 "a407_AB1FDShortToBattery" 406 "a406_AB1FDShortToGround" 405 "a405_AB1FPConfigError" 404 "a404_AB1FPCrossCoupled" 403 "a403_AB1FPShortToSelf" 402 "a402_AB1FPOpen" 401 "a401_AB1FPShortToBattery" 400 "a400_AB1FPShortToGround" 398 "a398_asicNvmReprogrammed" 397 "a397_safingMonitorError" 396 "a396_spiCommunicationProgramError" 395 "a395_imuCalibrationNotDone" 394 "a394_gspiGlobalStatusWordError" 393 "a393_depAdcConvertRatioError" 392 "a392_extAsic2ClockOrOperatingStateError" 391 "a391_extAsic1ClockOrOperatingStateError" 390 "a390_systemAsicClockOrOperatingStateError" 389 "a389_asicPwrStatusError" 388 "a388_cpuLoadHigh" 387 "a387_primaryAsicResetSource" 385 "a385_safingEngine21NoValidData" 384 "a384_safingEngine20NoValidData" 383 "a383_safingEngine19NoValidData" 382 "a382_safingEngine18NoValidData" 381 "a381_safingEngine17NoValidData" 380 "a380_safingEngine16NoValidData" 379 "a379_safingEngine15NoValidData" 378 "a378_safingEngine14NoValidData" 377 "a377_safingEngine13NoValidData" 376 "a376_safingEngine12NoValidData" 375 "a375_safingEngine11NoValidData" 374 "a374_safingEngine10NoValidData" 373 "a373_safingEngine9NoValidData" 372 "a372_safingEngine8NoValidData" 371 "a371_safingEngine7NoValidData" 370 "a370_safingEngine6NoValidData" 369 "a369_safingEngine5NoValidData" 368 "a368_safingEngine4NoValidData" 367 "a367_safingEngine3NoValidData" 366 "a366_safingEngine2NoValidData" 365 "a365_safingEngine1NoValidData" 364 "a364_safingEngine0NoValidData" 363 "a363_Loop31Deployment" 362 "a362_Loop30Deployment" 361 "a361_Loop29Deployment" 360 "a360_Loop28Deployment" 359 "a359_Loop27Deployment" 358 "a358_Loop26Deployment" 357 "a357_Loop25Deployment" 356 "a356_Loop24Deployment" 355 "a355_IC1FLDeployment" 354 "a354_IC1FRDeployment" 353 "a353_Loop21Deployment" 352 "a352_Loop20Deployment" 351 "a351_BT1FLDeployment" 350 "a350_BT1FRDeployment" 349 "a349_BT1RLDeployment" 348 "a348_BT1RRDeployment" 347 "a347_SA1FRDeployment" 346 "a346_SA1FLDeployment" 345 "a345_BT2FLDeployment" 344 "a344_BT2FRDeployment" 343 "a343_ALLFLDeployment" 342 "a342_ALLFRDeployment" 341 "a341_KA1FDDeployment" 340 "a340_KA1FPDeployment" 339 "a339_Loop7Deployment" 338 "a338_AV1FDDeployment" 337 "a337_AB2FDDeployment" 336 "a336_AB2FPDeployment" 335 "a335_Loop3Deployment" 334 "a334_AV1FPDeployment" 333 "a333_AB1FDDeployment" 332 "a332_AB1FPDeployment" 331 "a331_unarmedLoop31DeployCommand" 330 "a330_unarmedLoop30DeployCommand" 329 "a329_unarmedLoop29DeployCommand" 328 "a328_unarmedLoop28DeployCommand" 327 "a327_unarmedLoop27DeployCommand" 326 "a326_unarmedLoop26DeployCommand" 325 "a325_unarmedLoop25DeployCommand" 324 "a324_unarmedLoop24DeployCommand" 323 "a323_unarmedIC1FLDeployCommand" 322 "a322_unarmedIC1FRDeployCommand" 321 "a321_unarmedLoop21DeployCommand" 320 "a320_unarmedLoop20DeployCommand" 319 "a319_unarmedBT1FLDeployCommand" 318 "a318_unarmedBT1FRDeployCommand" 317 "a317_unarmedBT1RLDeployCommand" 316 "a316_unarmedBT1RRDeployCommand" 315 "a315_unarmedSA1FRDeployCommand" 314 "a314_unarmedSA1FLDeployCommand" 313 "a313_unarmedBT2FLDeployCommand" 312 "a312_unarmedBT2FRDeployCommand" 311 "a311_unarmedALLFLDeployCommand" 310 "a310_unarmedALLFRDeployCommand" 309 "a309_unarmedKA1FDDeployCommand" 308 "a308_unarmedKA1FPDeployCommand" 307 "a307_unarmedLoop7DeployCommand" 306 "a306_unarmedAV1FDDeployCommand" 305 "a305_unarmedAB2FDDeployCommand" 304 "a304_unarmedAB2FPDeployCommand" 303 "a303_unarmedFSABDeployCommand" 302 "a302_unarmedAV1FPDeployCommand" 301 "a301_unarmedAB1FDDeployCommand" 300 "a300_unarmedAB1FPDeployCommand" 299 "a299_safingEngine21Armed" 298 "a298_safingEngine20Armed" 297 "a297_safingEngine19Armed" 296 "a296_safingEngine18Armed" 295 "a295_safingEngine17Armed" 294 "a294_safingEngine16Armed" 293 "a293_safingEngine15Armed" 292 "a292_safingEngine14Armed" 291 "a291_safingEngine13Armed" 290 "a290_safingEngine12Armed" 289 "a289_safingEngine11Armed" 288 "a288_safingEngine10Armed" 287 "a287_safingEngine9Armed" 286 "a286_safingEngine8Armed" 285 "a285_safingEngine7Armed" 284 "a284_safingEngine6Armed" 283 "a283_safingEngine5Armed" 282 "a282_safingEngine4Armed" 281 "a281_safingEngine3Armed" 280 "a280_safingEngine2Armed" 279 "a279_safingEngine1Armed" 278 "a278_safingEngine0Armed" 276 "a276_watchdogStatus" 275 "a275_asm5AccStatusError" 274 "a274_asm5ArsStatusZError" 273 "a273_asm5ArsStatusXError" 272 "a272_asm5ComStatusError" 267 "a267_frontCenterAccelYSignalMonitor" 266 "a266_frontCenterAccelYSensorDefect" 265 "a265_frontCenterAccelYCommError" 264 "a264_frontCenterAccelYOpen" 263 "a263_frontCenterAccelYConfigError" 262 "a262_frontCenterAccelYShortToBattery" 261 "a261_frontCenterAccelYShortToGround" 260 "a260_frontCenterAccelYInitFailure" 257 "a257_frontCenterAccelXSignalMonitor" 256 "a256_frontCenterAccelXSensorDefect" 255 "a255_frontCenterAccelXCommError" 254 "a254_frontCenterAccelXOpen" 253 "a253_frontCenterAccelXConfigError" 252 "a252_frontCenterAccelXShortToBattery" 251 "a251_frontCenterAccelXShortToGround" 250 "a250_frontCenterAccelXInitFailure" 247 "a247_rightRearDoorPressureSignalMonitor" 246 "a246_rightRearDoorPressureSensorDefect" 245 "a245_rightRearDoorPressureCommError" 244 "a244_rightRearDoorPressureOpen" 243 "a243_rightRearDoorPressureConfigError" 242 "a242_rightRearDoorPressureShortToBattery" 241 "a241_rightRearDoorPressureShortToGround" 240 "a240_rightRearDoorPressureInitFailure" 237 "a237_leftRearDoorPressureSignalMonitor" 236 "a236_leftRearDoorPressureSensorDefect" 235 "a235_leftRearDoorPressureCommError" 234 "a234_leftRearDoorPressureOpen" 233 "a233_leftRearDoorPressureConfigError" 232 "a232_leftRearDoorPressureShortToBattery" 231 "a231_leftRearDoorPressureShortToGround" 230 "a230_leftRearDoorPressureInitFailure" 227 "a227_rightCPillarAccelSignalMonitor" 226 "a226_rightCPillarAccelSensorDefect" 225 "a225_rightCPillarAccelCommError" 224 "a224_rightCPillarAccelOpen" 223 "a223_rightCPillarAccelConfigError" 222 "a222_rightCPillarAccelShortToBattery" 221 "a221_rightCPillarAccelShortToGround" 220 "a220_rightCPillarAccelInitFailure" 217 "a217_leftCPillarAccelSignalMonitor" 216 "a216_leftCPillarAccelSensorDefect" 215 "a215_leftCPillarAccelCommError" 214 "a214_leftCPillarAccelOpen" 213 "a213_leftCPillarAccelConfigError" 212 "a212_leftCPillarAccelShortToBattery" 211 "a211_leftCPillarAccelShortToGround" 210 "a210_leftCPillarAccelInitFailure" 207 "a207_frontCenterAccelSignalMonitor" 206 "a206_frontCenterAccelSensorDefect" 205 "a205_frontCenterAccelCommError" 204 "a204_frontCenterAccelOpen" 203 "a203_frontCenterAccelConfigError" 202 "a202_frontCenterAccelShortToBattery" 201 "a201_frontCenterAccelShortToGround" 200 "a200_frontCenterAccelInitFailure" 197 "a197_leftBPillarAccelSignalMonitor" 196 "a196_leftBPillarAccelSensorDefect" 195 "a195_leftBPillarAccelCommError" 194 "a194_leftBPillarAccelOpen" 193 "a193_leftBPillarAccelConfigError" 192 "a192_leftBPillarAccelShortToBattery" 191 "a191_leftBPillarAccelShortToGround" 190 "a190_leftBPillarAccelInitFailure" 187 "a187_rightBPillarAccelSignalMonitor" 186 "a186_rightBPillarAccelSensorDefect" 185 "a185_rightBPillarAccelCommError" 184 "a184_rightBPillarAccelOpen" 183 "a183_rightBPillarAccelConfigError" 182 "a182_rightBPillarAccelShortToBattery" 181 "a181_rightBPillarAccelShortToGround" 180 "a180_rightBPillarAccelInitFailure" 177 "a177_leftFrontDoorPressureSignalMonitor" 176 "a176_leftFrontDoorPressureSensorDefect" 175 "a175_leftFrontDoorPressureCommError" 174 "a174_leftFrontDoorPressureOpen" 173 "a173_leftFrontDoorPressureConfigError" 172 "a172_leftFrontDoorPressureShortToBattery" 171 "a171_leftFrontDoorPressureShortToGround" 170 "a170_leftFrontDoorPressureInitFailure" 167 "a167_frontLeftAccelSignalMonitor" 166 "a166_frontLeftAccelSensorDefect" 165 "a165_frontLeftAccelCommError" 164 "a164_frontLeftAccelOpen" 163 "a163_frontLeftAccelConfigError" 162 "a162_frontLeftAccelShortToBattery" 161 "a161_frontLeftAccelShortToGround" 160 "a160_frontLeftAccelInitFailure" 157 "a157_rightFrontDoorPressureSignalMonitor" 156 "a156_rightFrontDoorPressureSensorDefect" 155 "a155_rightFrontDoorPressureCommError" 154 "a154_rightFrontDoorPressureOpen" 153 "a153_rightFrontDoorPressureConfigError" 152 "a152_rightFrontDoorPressureShortToBattery" 151 "a151_rightFrontDoorPressureShortToGround" 150 "a150_rightFrontDoorPressureInitFailure" 147 "a147_frontRightAccelSignalMonitor" 146 "a146_frontRightAccelSensorDefect" 145 "a145_frontRightAccelCommError" 144 "a144_frontRightAccelOpen" 143 "a143_frontRightAccelConfigError" 142 "a142_frontRightAccelShortToBattery" 141 "a141_frontRightAccelShortToGround" 140 "a140_frontRightAccelInitFailure" 139 "a139_disarmed" 138 "a138_ext2AsicSnoopTestFailed" 137 "a137_ext1AsicSnoopTestFailed" 136 "a136_asm5DeviceFaulted" 135 "a135_asm5StatusError" 134 "a134_glacierDeviceFaulted" 133 "a133_glacierDeviceReset" 132 "a132_glacierNormalOperationFailure" 131 "a131_glacierOffsetVerificationFailure" 130 "a130_glacierFinalStatusFailure" 129 "a129_glacierOscillatorVerificationFailure" 128 "a128_glacierAnalogSelfTestFailure" 127 "a127_glacierSelfTestFFailure" 126 "a126_glacierSelfTestEFailure" 125 "a125_glacierFixedPatternSelfTestFailure" 124 "a124_glacierRegisterPatternWriteFailure" 123 "a123_glacierTraceabilityReadoutB0B0Failure" 122 "a122_glacierTraceabilityReadoutA0A0Failure" 121 "a121_glacierInitialStatusFailure" 120 "a120_DI_DRIVE_MIA" 119 "a119_SCCM_MIA" 118 "a118_VCFRONT_MIA" 117 "a117_VCLEFT_MIA" 116 "a116_VCRIGHT_MIA" 115 "a115_VCSEC_MIA" 114 "a114_ESP_MIA" 113 "a113_UI_MIA" 112 "a112_EPBL_MIA" 111 "a111_EPBR_MIA" 110 "a110_GTW_MIA" 109 "a109_RCM_MIA" 108 "a108_DIF_MIA" 107 "a107_BMS_MIA" 106 "a106_PCS_MIA" 105 "a105_TAS_MIA" 104 "a104_DAS_MIA" 103 "a103_CP_MIA" 102 "a102_PTC_MIA" 101 "a101_PM_MIA" 100 "a100_CANbus_MIA" 99 "a099_PARK_MIA" 98 "a098_DIR_MIA" 97 "a097_CMP_MIA" 96 "a096_OCS1P_MIA" 95 "a095_CHG_MIA" 94 "a094_EPAS3P_MIA" 93 "a093_VCSEATP_MIA" 92 "a092_VCSEATD_MIA" 91 "a091_CMPD_MIA" 90 "a090_APS_MIA" 89 "a089_IBST_MIA" 88 "a088_DIRER_MIA" 87 "a087_DIREL_MIA" 86 "a086_VCBATT_MIA" 85 "a085_CCCM_MIA" 84 "a084_TPMS_MIA" 83 "a083_VCLEFT_IPC_MIA" 82 "a082_VCRIGHT_IPC_MIA" 81 "a081_autarkyActive" 77 "a077_ais2120SelfTestYNegativeFailed" 76 "a076_ais2120SelfTestYPositiveFailed" 75 "a075_ais2120SelfTestXNegativeFailed" 74 "a074_ais2120SelfTestXPositiveFailed" 73 "a073_ais2120DeviceFaulted" 72 "a072_ais2120StatusError" 71 "a071_asm3DeviceFaulted" 70 "a070_asm3StatusError" 69 "a069_swAppBoot" 68 "a068_vBusCUnderVoltage" 67 "a067_vBusBUnderVoltage" 66 "a066_vBusAUnderVoltage" 65 "a065_vSafingFetUnderVoltage" 64 "a064_busSleepReqTimeout" 63 "a063_SwitchFault" 62 "a062_XCPWasConnected" 61 "a061_XCPConnected" 60 "a060_engineeringBuild" 59 "a059_inputResistanceHigh" 58 "a058_inputRHighSyncDebug" 57 "a057_HVP_MIA" 46 "a046_Task1000msError" 45 "a045_Task100msError" 44 "a044_Task10msError" 43 "a043_Task1msError" 42 "a042_HighStackUsage" 41 "a041_HighCPULoad" 35 "a035_hvDisconnectCommanded" 34 "a034_apClipTrigger" 33 "a033_HercLogCreated" 31 "a031_UDSActive" 30 "a030_ECULogUploadRequest" 27 "a027_airbagAsicDeploymentDiagnosticFault" 26 "a026_airbagAsicDiagnosticFault" 25 "a025_CHCANBusFaults" 24 "a024_asm3AccStatusError" 23 "a023_asm3ArsStatusXError" 22 "a022_TaskInitError" 21 "a021_TaskSchedulerError" 20 "a020_asm3ComStatusError" 19 "a019_Task500usError" 18 "a018_asm3TemperatureOutsideOperatingRange" 17 "a017_asm5TemperatureOutsideOperatingRange" 16 "a016_NVMMRecordError" 15 "a015_NVMMError" 14 "a014_asm3TemperatureOutsideSignalRange" 13 "a013_AlertManagerFault" 12 "a012_asm5TemperatureOutsideSignalRange" 10 "a010_partyCounterError" 9 "a009_partyChecksumError" 8 "a008_chassisCounterError" 7 "a007_chassisChecksumError" 6 "a006_CANTX_cyclicError" 5 "a005_CANTXError" 3 "a003_SWAssertion" 0 "ALERT_DO_NOT_USE_ZERO" ;
VAL_ 1298 TRCM_alertState 1 "SET" 0 "CLEARED" ;
VAL_ 2030 TRCM_matrixIndex 10 "AlertMatrix10" 9 "AlertMatrix9" 8 "AlertMatrix8" 7 "AlertMatrix7" 6 "AlertMatrix6" 5 "AlertMatrix5" 4 "AlertMatrix4" 3 "AlertMatrix3" 2 "AlertMatrix2" 1 "AlertMatrix1" 0 "AlertMatrix0" ;
